VERSION ""

NS_ :

BS_:

BU_: VCM SCIM IC CCM

BO_ 156 VCM_04P_C05: 8 VCM
 SG_ LiftAxle2LowerACK : 32|3@1+ (1,0) [0|0] ""  IC
 SG_ LiftAxle2PositionStatus : 20|3@1+ (1,0) [0|0] ""  IC
 SG_ LiftAxle2LiftFuncSelected : 53|3@1+ (1,0) [0|0] ""  IC
 SG_ PassengerDoorAjar_stat : 35|3@1+ (1,0) [0|0] ""  CCM
 SG_ AirFlowSelectionDownBtn_stat : 2|2@1+ (1,0) [0|0] ""  IC
 SG_ LevelControlInformation : 56|4@1+ (1,0) [0|0] ""  IC
 SG_ LiftAxle1LowerACK : 38|3@1+ (1,0) [0|0] ""  IC
 SG_ WiperModeStatus : 41|3@1+ (1,0) [0|0] ""  IC,CCM
 SG_ Washing_HMI_rqst : 60|2@1+ (1,0) [0|0] ""  CCM
 SG_ LiftAxle2AutoLiftSelected : 8|2@1+ (1,0) [0|0] ""  IC
 SG_ ReverseGearEngaged : 10|2@1+ (1,0) [0|0] ""  CCM
 SG_ LiftAxle1PositionStatus : 17|3@1+ (1,0) [0|0] ""  IC
 SG_ ACC_Status : 47|3@1+ (1,0) [0|0] ""  IC
 SG_ LECM_CabClim_MaxDef_GuiReq : 6|2@1+ (1,0) [0|0] ""  IC
 SG_ RegenerationSwitchStatus : 23|3@1+ (1,0) [0|0] ""  IC
 SG_ DSWindowPosition : 29|3@1+ (1,0) [0|0] ""  CCM
 SG_ WindscreenDefrost_ButtonStatus : 4|2@1+ (1,0) [0|0] ""  IC
 SG_ GearSplit_Status : 0|2@1+ (1,0) [0|0] ""  IC
 SG_ KeyPosition : 44|3@1+ (1,0) [0|0] ""  IC
 SG_ LiftAxle1LiftFuncSelected : 50|3@1+ (1,0) [0|0] ""  IC
 SG_ LiftAxle2UpRequestACK : 26|3@1+ (1,0) [0|0] ""  IC
 SG_ PreTrip_ButtonStat3 : 12|2@1+ (1,0) [0|0] ""  IC
 SG_ LiftAxle1UpRequestACK : 14|3@1+ (1,0) [0|0] ""  IC

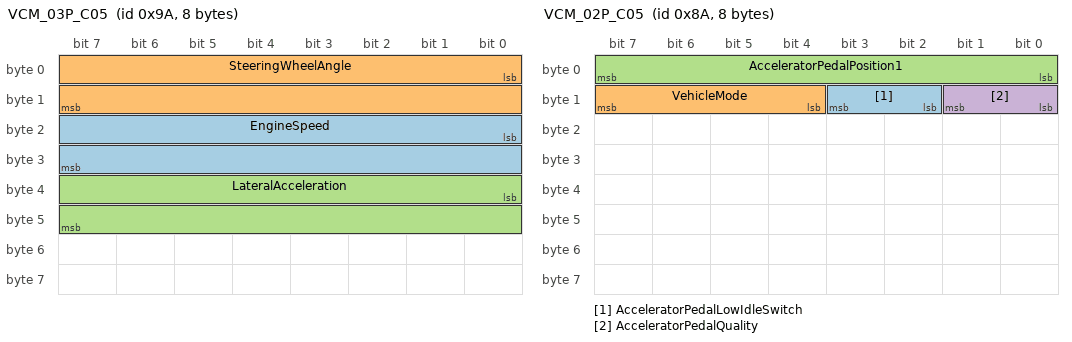
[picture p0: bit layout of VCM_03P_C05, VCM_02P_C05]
BO_ 154 VCM_03P_C05: 8 VCM
 SG_ EngineSpeed : 16|16@1+ (0.125,0) [0|8191.875] "rpm"  CCM
 SG_ SteeringWheelAngle : 0|16@1+ (0.0009765625,-31.374) [-31.374|32.6250234375] "rad"  IC
 SG_ LateralAcceleration : 32|16@1+ (0.00048828125,-15.687) [-15.687|16.31251171875] "m_per_s_squared"  IC

BO_ 138 VCM_02P_C05: 8 VCM
 SG_ AcceleratorPedalLowIdleSwitch : 10|2@1+ (1,0) [0|0] ""  IC
 SG_ VehicleMode : 12|4@1+ (1,0) [0|0] ""  SCIM,IC,CCM
 SG_ AcceleratorPedalPosition1 : 0|8@1+ (0.4,0) [0|102] "Percent"  IC
 SG_ AcceleratorPedalQuality : 8|2@1+ (1,0) [0|0] ""  IC

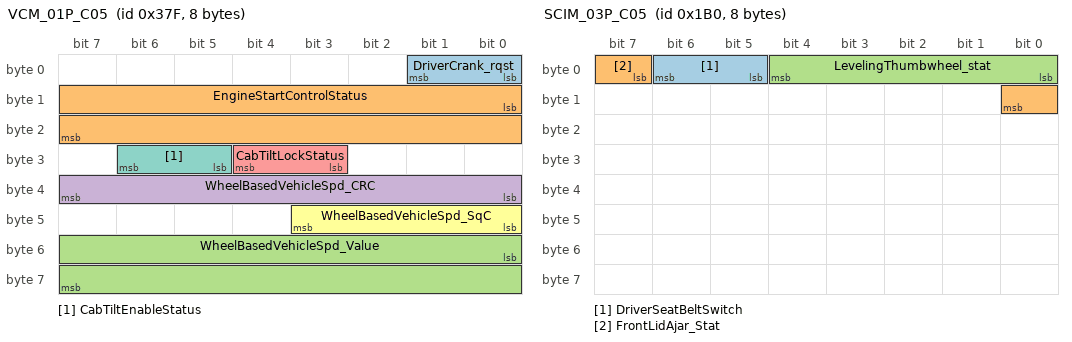
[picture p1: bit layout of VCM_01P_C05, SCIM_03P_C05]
BO_ 895 VCM_01P_C05: 8 VCM
 SG_ DriverCrank_rqst : 0|2@1+ (1,0) [0|0] ""  IC
 SG_ EngineStartControlStatus : 8|16@1+ (1,0) [0|65535] "NotApplicable"  IC
 SG_ WheelBasedVehicleSpd_Value : 48|16@1+ (0.00390625,0) [0|255.99609375] "Km_per_h"  IC
 SG_ WheelBasedVehicleSpd_CRC : 32|8@1+ (1,0) [0|255] ""  IC
 SG_ CabTiltLockStatus : 27|2@1+ (1,0) [0|0] ""  IC
 SG_ WheelBasedVehicleSpd_SqC : 40|4@1+ (1,0) [0|14] "NotApplicable"  IC
 SG_ CabTiltEnableStatus : 29|2@1+ (1,0) [0|0] ""  SCIM

BO_ 2671902706 TesterFuncDiagMsg_C05: 8 VCM
 SG_ FuncDiagDataTester : 0|64@1+ (1,0) [0|0] ""  CCM,IC,SCIM

BO_ 2671902708 TesterFuncDiagMsgF4_C05: 8 VCM
 SG_ FuncDiagDataIntTesterF4 : 0|64@1+ (1,0) [0|0] ""  CCM,IC,SCIM

BO_ 1104 SCIM_P01_C05: 8 SCIM
 SG_ CabTilt_rqst : 0|2@1+ (1,0) [0|0] ""  VCM

BO_ 432 SCIM_03P_C05: 8 SCIM
 SG_ DriverSeatBeltSwitch : 5|2@1+ (1,0) [0|0] ""  VCM,IC
 SG_ FrontLidAjar_Stat : 7|2@1+ (1,0) [0|0] ""  VCM
 SG_ LevelingThumbwheel_stat : 0|5@1+ (1,0) [0|0] ""  VCM

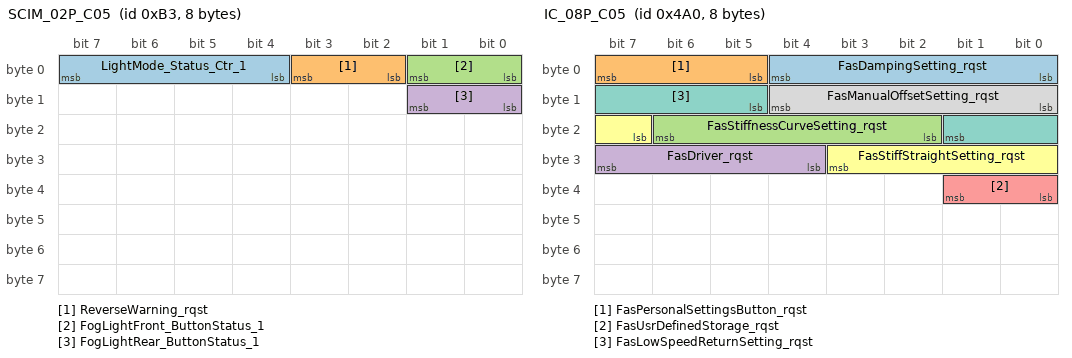
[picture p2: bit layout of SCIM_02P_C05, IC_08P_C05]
BO_ 179 SCIM_02P_C05: 8 SCIM
 SG_ LightMode_Status_Ctr_1 : 4|4@1+ (1,0) [0|0] ""  VCM
 SG_ ReverseWarning_rqst : 2|2@1+ (1,0) [0|0] ""  VCM
 SG_ FogLightFront_ButtonStatus_1 : 0|2@1+ (1,0) [0|0] ""  VCM
 SG_ FogLightRear_ButtonStatus_1 : 8|2@1+ (1,0) [0|0] ""  VCM

BO_ 2671833752 PhysDiagRespMsg_F2_98_C05: 8 CCM
 SG_ PhysDiagRespSig_F2_98 : 0|64@1+ (1,0) [0|0] ""  VCM

BO_ 2671833730 PhysDiagRespMsg_F2_82_C05: 8 IC
 SG_ PhysDiagRespSig_F2_82 : 0|64@1+ (1,0) [0|0] ""  VCM

BO_ 2671833697 PhysDiagRespMsg_F2_61_C05: 8 IC
 SG_ PhysDiagRespSig_F2_61 : 0|64@1+ (1,0) [0|0] ""  VCM

BO_ 2671833664 PhysDiagRespMsg_F2_40_C05: 8 SCIM
 SG_ PhysDiagRespSig_F2_40 : 0|64@1+ (1,0) [0|0] ""  VCM

BO_ 2671810802 PhysDiagReqMsg_98_F2_C05: 8 VCM
 SG_ PhysDiagReqSig_98_F2 : 0|64@1+ (1,0) [0|0] ""  CCM

BO_ 2671805170 PhysDiagReqMsg_82_F2_C05: 8 VCM
 SG_ PhysDiagReqSig_82_F2 : 0|64@1+ (1,0) [0|0] ""  IC

BO_ 2671796722 PhysDiagReqMsg_61_F2_C05: 8 VCM
 SG_ PhysDiagReqSig_61_F2 : 0|64@1+ (1,0) [0|0] ""  IC

BO_ 2671788274 PhysDiagReqMsg_40_F2_C05: 8 VCM
 SG_ PhysDiagReqSig_40_F2 : 0|64@1+ (1,0) [0|0] ""  SCIM

BO_ 2633990180 NmAsr_VCM_C05: 1 VCM

BO_ 2633990208 NmAsr_SCIM_C05: 1 SCIM

BO_ 2633990241 NmAsr_IC_C05: 1 IC

BO_ 2633990296 NmAsr_CCM_C05: 1 CCM

BO_ 1457 IC_09S_C05_FCM: 8 VCM
 SG_ IC_09S_C05_FCS : 0|64@1+ (1,0) [0|0] ""  IC

BO_ 1456 IC_09S_C05: 11 IC
 SG_ ECU3VIN_stat : 0|88@1+ (1,0) [0|0] ""  VCM

BO_ 1184 IC_08P_C05: 8 IC
 SG_ FasDampingSetting_rqst : 0|5@1+ (1,-10) [-10|21] ""  VCM
 SG_ FasPersonalSettingsButton_rqst : 5|3@1+ (1,0) [0|0] ""  VCM
 SG_ FasStiffnessCurveSetting_rqst : 18|5@1+ (1,-10) [-10|21] ""  VCM
 SG_ FasDriver_rqst : 28|4@1+ (1,0) [0|0] ""  VCM
 SG_ FasUsrDefinedStorage_rqst : 32|2@1+ (1,0) [0|0] ""  VCM
 SG_ FasStiffStraightSetting_rqst : 23|5@1+ (1,-10) [-10|21] ""  VCM
 SG_ FasLowSpeedReturnSetting_rqst : 13|5@1+ (1,-10) [-10|21] ""  VCM
 SG_ FasManualOffsetSetting_rqst : 8|5@1+ (1,-10) [-10|21] ""  VCM

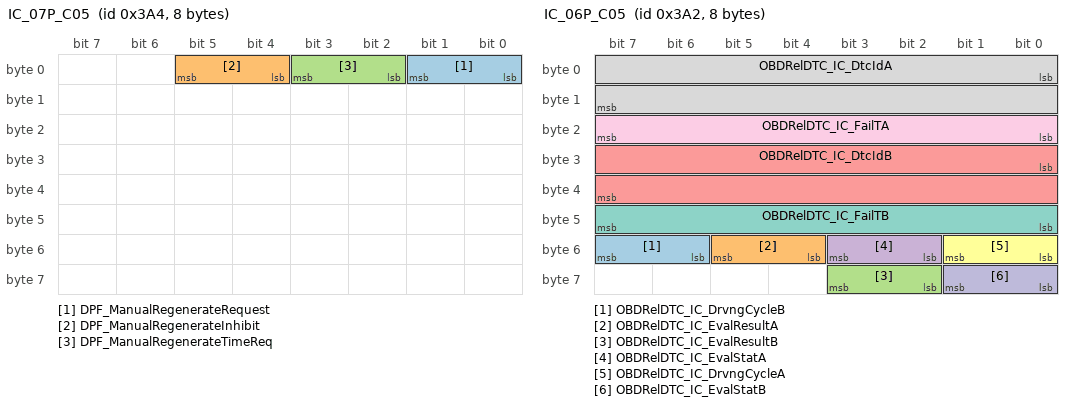
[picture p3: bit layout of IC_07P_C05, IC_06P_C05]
BO_ 932 IC_07P_C05: 8 IC
 SG_ DPF_ManualRegenerateRequest : 0|2@1+ (1,0) [0|0] ""  VCM
 SG_ DPF_ManualRegenerateInhibit : 4|2@1+ (1,0) [0|0] ""  VCM
 SG_ DPF_ManualRegenerateTimeReq : 2|2@1+ (1,0) [0|0] ""  VCM

BO_ 930 IC_06P_C05: 8 IC
 SG_ OBDRelDTC_IC_DrvngCycleB : 54|2@1+ (1,0) [0|0] ""  VCM
 SG_ OBDRelDTC_IC_EvalResultA : 52|2@1+ (1,0) [0|0] ""  VCM
 SG_ OBDRelDTC_IC_EvalResultB : 58|2@1+ (1,0) [0|0] ""  VCM
 SG_ OBDRelDTC_IC_EvalStatA : 50|2@1+ (1,0) [0|0] ""  VCM
 SG_ OBDRelDTC_IC_DtcIdB : 24|16@1+ (1,0) [0|65535] ""  VCM
 SG_ OBDRelDTC_IC_DrvngCycleA : 48|2@1+ (1,0) [0|0] ""  VCM
 SG_ OBDRelDTC_IC_FailTB : 40|8@1+ (1,0) [0|255] ""  VCM
 SG_ OBDRelDTC_IC_DtcIdA : 0|16@1+ (1,0) [0|65535] ""  VCM
 SG_ OBDRelDTC_IC_FailTA : 16|8@1+ (1,0) [0|255] ""  VCM
 SG_ OBDRelDTC_IC_EvalStatB : 56|2@1+ (1,0) [0|0] ""  VCM

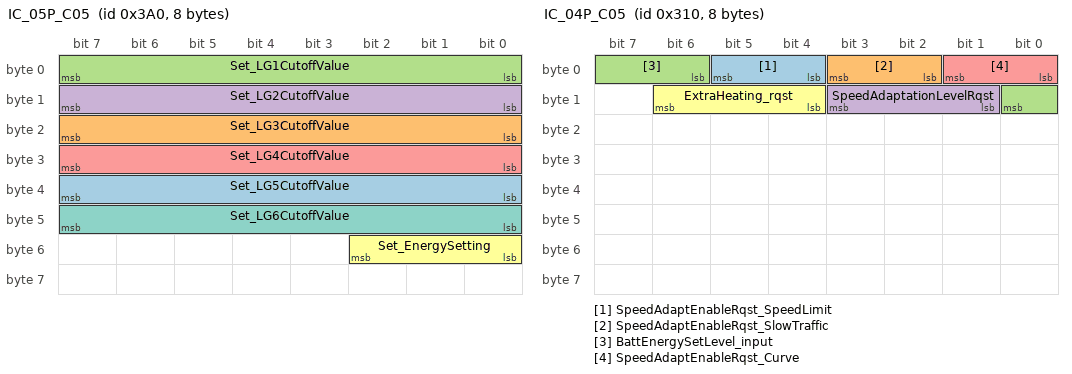
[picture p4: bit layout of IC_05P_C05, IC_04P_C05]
BO_ 928 IC_05P_C05: 8 IC
 SG_ Set_LG5CutoffValue : 32|8@1+ (1,0) [0|255] "Percent"  VCM
 SG_ Set_LG3CutoffValue : 16|8@1+ (1,0) [0|255] "Percent"  VCM
 SG_ Set_LG1CutoffValue : 0|8@1+ (1,0) [0|255] "Percent"  VCM
 SG_ Set_LG2CutoffValue : 8|8@1+ (1,0) [0|255] "Percent"  VCM
 SG_ Set_LG4CutoffValue : 24|8@1+ (1,0) [0|255] "Percent"  VCM
 SG_ Set_EnergySetting : 48|3@1+ (1,0) [0|0] ""  VCM
 SG_ Set_LG6CutoffValue : 40|8@1+ (1,0) [0|255] "Percent"  VCM

BO_ 784 IC_04P_C05: 8 IC
 SG_ SpeedAdaptEnableRqst_SpeedLimit : 4|2@1+ (1,0) [0|0] ""  VCM
 SG_ SpeedAdaptEnableRqst_SlowTraffic : 2|2@1+ (1,0) [0|0] ""  VCM
 SG_ BattEnergySetLevel_input : 6|3@1+ (1,0) [0|0] ""  VCM
 SG_ SpeedAdaptationLevelRqst : 9|3@1+ (1,0) [0|0] ""  VCM
 SG_ SpeedAdaptEnableRqst_Curve : 0|2@1+ (1,0) [0|0] ""  VCM
 SG_ ExtraHeating_rqst : 12|3@1+ (1,0) [0|0] ""  CCM,VCM

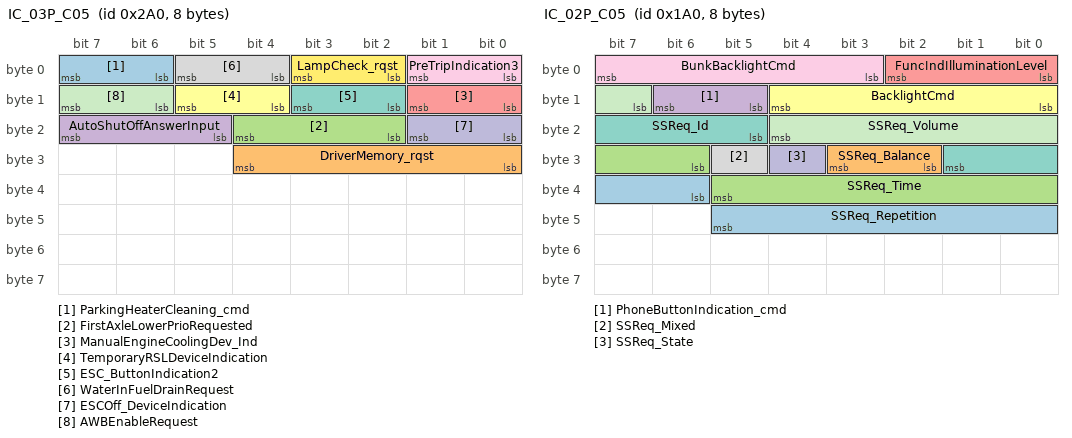
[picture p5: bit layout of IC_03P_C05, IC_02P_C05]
BO_ 672 IC_03P_C05: 8 IC
 SG_ ParkingHeaterCleaning_cmd : 6|2@1+ (1,0) [0|0] ""  VCM,CCM
 SG_ DriverMemory_rqst : 24|5@1+ (1,0) [0|0] ""  CCM,VCM
 SG_ FirstAxleLowerPrioRequested : 18|3@1+ (1,0) [0|0] ""  VCM
 SG_ AutoShutOffAnswerInput : 21|3@1+ (1,0) [0|0] ""  VCM
 SG_ ManualEngineCoolingDev_Ind : 8|2@1+ (1,0) [0|0] ""  VCM
 SG_ TemporaryRSLDeviceIndication : 12|2@1+ (1,0) [0|0] ""  VCM
 SG_ ESC_ButtonIndication2 : 10|2@1+ (1,0) [0|0] ""  VCM
 SG_ WaterInFuelDrainRequest : 4|2@1+ (1,0) [0|0] ""  VCM
 SG_ PreTripIndication3 : 0|2@1+ (1,0) [0|0] ""  VCM
 SG_ ESCOff_DeviceIndication : 16|2@1+ (1,0) [0|0] ""  VCM
 SG_ AWBEnableRequest : 14|2@1+ (1,0) [0|0] ""  VCM
 SG_ LampCheck_rqst : 2|2@1+ (1,0) [0|0] ""  VCM

BO_ 416 IC_02P_C05: 8 IC
 SG_ SSReq_Repetition : 38|8@1+ (1,0) [0|255] ""  VCM
 SG_ SSReq_Balance : 26|2@1+ (1,0) [0|0] ""  VCM
 SG_ SSReq_Time : 30|8@1+ (0.1,0) [0|25.5] "s"  VCM
 SG_ PhoneButtonIndication_cmd : 13|2@1+ (1,0) [0|0] ""  VCM
 SG_ FuncIndIlluminationLevel : 0|3@1+ (1,0) [0|0] ""  VCM
 SG_ BacklightCmd : 8|5@1+ (1,0) [0|0] ""  VCM
 SG_ SSReq_Id : 21|5@1+ (1,0) [0|31] ""  VCM
 SG_ SSReq_Mixed : 29|1@1+ (1,0) [0|0] ""  VCM
 SG_ BunkBacklightCmd : 3|5@1+ (1,0) [0|0] ""  VCM
 SG_ SSReq_State : 28|1@1+ (1,0) [0|0] ""  VCM
 SG_ SSReq_Volume : 15|6@1+ (1,0) [0|63] ""  VCM

BO_ 211 IC_01P_C05: 8 IC
 SG_ TimeGapBtnStat : 30|2@1+ (1,0) [0|0] ""  VCM
 SG_ ATC_ButtonIndication : 10|2@1+ (1,0) [0|0] ""  VCM
 SG_ PauseOffBtnStat : 0|2@1+ (1,0) [0|0] ""  VCM
 SG_ ABS_ButtonIndication : 18|2@1+ (1,0) [0|0] ""  VCM
 SG_ SW_HeadlightInterrupt_Stat : 32|2@1+ (1,0) [0|0] ""  VCM
 SG_ PBAlertActiveStatus : 34|3@1+ (1,0) [0|0] ""  VCM
 SG_ EcoRollEnableRequest : 24|2@1+ (1,0) [0|0] ""  VCM
 SG_ EcoSettingsBtnStat : 22|2@1+ (1,0) [0|0] ""  VCM
 SG_ SkipNextBtnStat : 12|2@1+ (1,0) [0|0] ""  VCM
 SG_ TCS_ButtonIndication : 6|2@1+ (1,0) [0|0] ""  VCM
 SG_ DHCBtnStat : 16|2@1+ (1,0) [0|0] ""  VCM
 SG_ PhoneBtnStat : 8|2@1+ (1,0) [0|0] ""  VCM
 SG_ SkipPrevBtnStat : 4|2@1+ (1,0) [0|0] ""  VCM
 SG_ ActivateBtnStat : 26|2@1+ (1,0) [0|0] ""  VCM
 SG_ ResIncrBtnStat : 2|2@1+ (1,0) [0|0] ""  VCM
 SG_ SrcBtnStat : 14|2@1+ (1,0) [0|0] ""  VCM
 SG_ SetDecrBtnStat : 28|2@1+ (1,0) [0|0] ""  VCM
 SG_ MarkerInterruptButtonStatus : 20|2@1+ (1,0) [0|0] ""  VCM

BO_ 1123 DummyFrame_VCM_C_C05: 8 VCM
 SG_ DummyApplicationSignal : 0|8@1+ (1,0) [0|255] ""  SCIM,IC,CCM

BO_ 2671964824 DiagUUDTRespMsg1_F2_98_C05: 8 CCM
 SG_ DiagUUDTRespSig_F2_98 : 0|64@1+ (1,0) [0|0] ""  VCM

BO_ 2671964802 DiagUUDTRespMsg1_F2_82_C05: 8 IC
 SG_ DiagUUDTRespSig_F2_82 : 0|64@1+ (1,0) [0|0] ""  VCM

BO_ 2671964769 DiagUUDTRespMsg1_F2_61_C05: 8 IC
 SG_ DiagUUDTRespSig_F2_61 : 0|64@1+ (1,0) [0|0] ""  VCM

BO_ 2671964736 DiagUUDTRespMsg1_F2_40_C05: 8 SCIM
 SG_ DiagUUDTRespSig_F2_40 : 0|64@1+ (1,0) [0|0] ""  VCM

BO_ 2671834264 DiagRespMsgForIntTest_F4_98_C05: 8 CCM
 SG_ InternalTesterDiagSig_F4_98 : 0|64@1+ (1,0) [0|0] ""  VCM

BO_ 2671834242 DiagRespMsgForIntTest_F4_82_C05: 8 IC
 SG_ InternalTesterDiagSig_F4_82 : 0|64@1+ (1,0) [0|0] ""  VCM

BO_ 2671834209 DiagRespMsgForIntTest_F4_61_C05: 8 IC
 SG_ InternalTesterDiagSig_F4_61 : 0|64@1+ (1,0) [0|0] ""  VCM

BO_ 2671834176 DiagRespMsgForIntTest_F4_40_C05: 8 SCIM
 SG_ InternalTesterDiagSig_F4_40 : 0|64@1+ (1,0) [0|0] ""  VCM

BO_ 2671810804 DiagReqMsgOfIntTest_98_F4_C05: 8 VCM
 SG_ InternalTesterDiagSig_98_F4 : 0|64@1+ (1,0) [0|0] ""  CCM

BO_ 2671805172 DiagReqMsgOfIntTest_82_F4_C05: 8 VCM
 SG_ InternalTesterDiagSig_82_F4 : 0|64@1+ (1,0) [0|0] ""  IC

BO_ 2671796724 DiagReqMsgOfIntTest_61_F4_C05: 8 VCM
 SG_ InternalTesterDiagSig_61_F4 : 0|64@1+ (1,0) [0|0] ""  IC

BO_ 2671788276 DiagReqMsgOfIntTest_40_F4_C05: 8 VCM
 SG_ InternalTesterDiagSig_40_F4 : 0|64@1+ (1,0) [0|0] ""  SCIM

BO_ 1121 CCM_07P_C05_FCM: 8 VCM
 SG_ CCM_07P_C05_FCS : 0|64@1+ (1,0) [0|0] ""  CCM

BO_ 1120 CCM_07P_C05: 10 CCM
 SG_ EngineTimer_stat_Timer2Minutes : 64|8@1+ (1,0) [0|255] "min"  VCM
 SG_ EngineTimer_stat_Timer1Recurr : 0|4@1+ (1,0) [0|0] ""  VCM
 SG_ EngineTimer_stat_Timer3Minutes : 56|8@1+ (1,0) [0|255] "min"  VCM
 SG_ EngineTimer_stat_Timer2StartDay : 16|4@1+ (1,0) [0|0] ""  VCM
 SG_ EngineTimer_stat_Timer3Recurr : 8|4@1+ (1,0) [0|0] ""  VCM
 SG_ EngineTimer_stat_Timer1Hours : 40|8@1+ (1,0) [0|255] "h"  VCM
 SG_ EngineTimer_stat_Timer3_Status : 76|2@1+ (1,0) [0|0] ""  VCM
 SG_ EngineTimer_stat_Timer1_Status : 72|2@1+ (1,0) [0|0] ""  VCM
 SG_ EngineTimer_stat_Timer1Minutes : 24|8@1+ (1,0) [0|255] "min"  VCM
 SG_ EngineTimer_stat_Timer2Recurr : 4|4@1+ (1,0) [0|0] ""  VCM
 SG_ EngineTimer_stat_Timer3Hours : 32|8@1+ (1,0) [0|255] "h"  VCM
 SG_ EngineTimer_stat_Timer2_Status : 74|2@1+ (1,0) [0|0] ""  VCM
 SG_ EngineTimer_stat_Timer2Hours : 48|8@1+ (1,0) [0|255] "h"  VCM
 SG_ EngineTimer_stat_Timer1StartDay : 12|4@1+ (1,0) [0|0] ""  VCM
 SG_ EngineTimer_stat_Timer3StartDay : 20|4@1+ (1,0) [0|0] ""  VCM

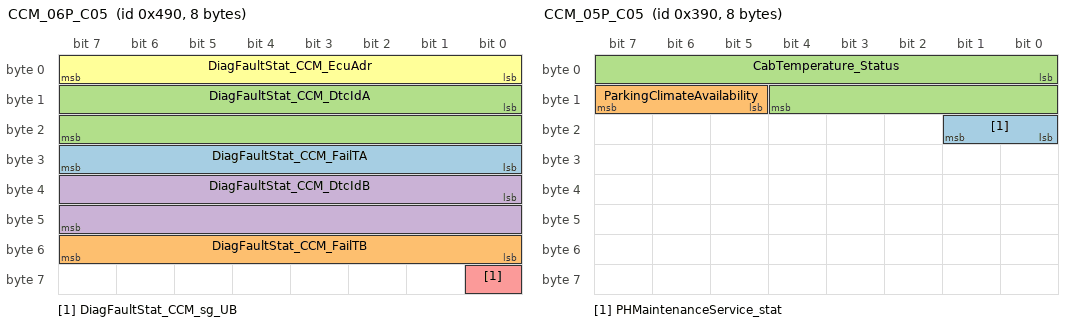
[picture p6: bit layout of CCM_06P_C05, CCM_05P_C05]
BO_ 1168 CCM_06P_C05: 8 CCM
 SG_ DiagFaultStat_CCM_FailTA : 24|8@1+ (1,0) [0|255] ""  VCM
 SG_ DiagFaultStat_CCM_FailTB : 48|8@1+ (1,0) [0|255] ""  VCM
 SG_ DiagFaultStat_CCM_DtcIdA : 8|16@1+ (1,0) [0|65535] ""  VCM
 SG_ DiagFaultStat_CCM_DtcIdB : 32|16@1+ (1,0) [0|65535] ""  VCM
 SG_ DiagFaultStat_CCM_sg_UB : 56|1@1+ (1,0) [0|0] ""  VCM
 SG_ DiagFaultStat_CCM_EcuAdr : 0|8@1+ (1,0) [0|255] ""  VCM

BO_ 912 CCM_05P_C05: 8 CCM
 SG_ PHMaintenanceService_stat : 16|2@1+ (1,0) [0|0] ""  VCM
 SG_ ParkingClimateAvailability : 13|3@1+ (1,0) [0|0] ""  VCM
 SG_ CabTemperature_Status : 0|13@1+ (0.025,-40) [-40|164.775] "DegreeC"  VCM

BO_ 656 CCM_04P_C05: 8 CCM
 SG_ AcCoolantPumpEngagementRequest : 0|8@1+ (0.4,0) [0|102] "Percent"  VCM

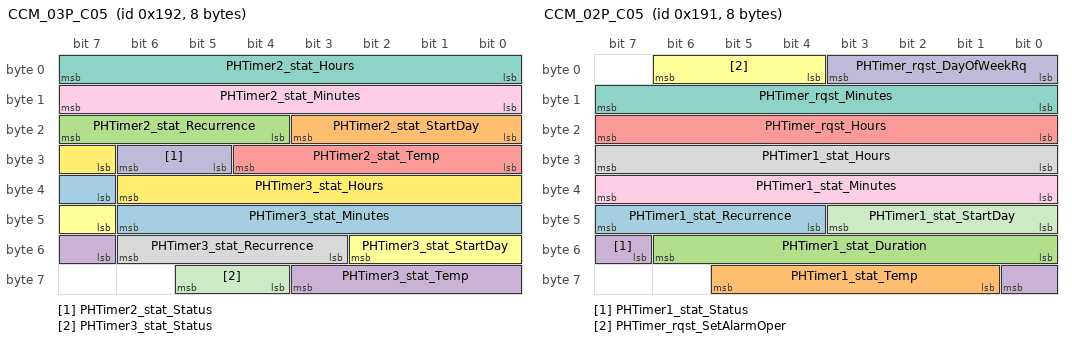
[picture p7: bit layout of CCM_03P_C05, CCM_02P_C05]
BO_ 402 CCM_03P_C05: 8 CCM
 SG_ PHTimer3_stat_Minutes : 39|8@1+ (1,0) [0|255] "min"  VCM
 SG_ PHTimer2_stat_StartDay : 16|4@1+ (1,0) [0|0] ""  VCM
 SG_ PHTimer2_stat_Recurrence : 20|4@1+ (1,0) [0|0] ""  VCM
 SG_ PHTimer3_stat_Temp : 55|5@1+ (1,0) [0|0] ""  VCM
 SG_ PHTimer2_stat_Temp : 24|5@1+ (1,0) [0|0] ""  VCM
 SG_ PHTimer3_stat_StartDay : 47|4@1+ (1,0) [0|0] ""  VCM
 SG_ PHTimer2_stat_Hours : 0|8@1+ (1,0) [0|255] "h"  VCM
 SG_ PHTimer3_stat_Recurrence : 51|4@1+ (1,0) [0|0] ""  VCM
 SG_ PHTimer2_stat_Minutes : 8|8@1+ (1,0) [0|255] "min"  VCM
 SG_ PHTimer2_stat_Status : 29|2@1+ (1,0) [0|0] ""  VCM
 SG_ PHTimer3_stat_Status : 60|2@1+ (1,0) [0|0] ""  VCM
 SG_ PHTimer3_stat_Hours : 31|8@1+ (1,0) [0|255] "h"  VCM

BO_ 401 CCM_02P_C05: 8 CCM
 SG_ PHTimer1_stat_Recurrence : 44|4@1+ (1,0) [0|0] ""  VCM
 SG_ PHTimer1_stat_Temp : 57|5@1+ (1,0) [0|0] ""  VCM
 SG_ PHTimer1_stat_Duration : 48|7@1+ (1,0) [0|127] "min"  VCM
 SG_ PHTimer1_stat_Status : 55|2@1+ (1,0) [0|0] ""  VCM
 SG_ PHTimer_rqst_Hours : 16|8@1+ (1,0) [0|255] "h"  VCM
 SG_ PHTimer_rqst_SetAlarmOper : 4|3@1+ (1,0) [0|0] ""  VCM
 SG_ PHTimer_rqst_Minutes : 8|8@1+ (1,0) [0|255] "min"  VCM
 SG_ PHTimer1_stat_Hours : 24|8@1+ (1,0) [0|255] "h"  VCM
 SG_ PHTimer1_stat_Minutes : 32|8@1+ (1,0) [0|255] "min"  VCM
 SG_ PHTimer_rqst_DayOfWeekRq : 0|4@1+ (1,0) [0|0] ""  VCM
 SG_ PHTimer1_stat_StartDay : 40|4@1+ (1,0) [0|0] ""  VCM

BO_ 400 CCM_01P_C05: 8 CCM
 SG_ WindscreenDefrostInd_cmd : 1|1@1+ (1,0) [0|0] ""  VCM
 SG_ ParkingHeater_IndicationCmd : 0|1@1+ (1,0) [0|0] ""  VCM
 SG_ AutoBlowerLevelIndication_Cmd : 18|3@1+ (1,0) [0|0] ""  VCM
 SG_ AC_CompressorClutchCmd : 4|2@1+ (1,0) [0|0] ""  VCM
 SG_ ACdisplayIndication_Cmd : 15|3@1+ (1,0) [0|0] ""  VCM
 SG_ ParkingHeaterCleaning_Rqst : 8|2@1+ (1,0) [0|0] ""  IC,VCM
 SG_ TemperatureRqstIndication_cmd : 29|5@1+ (1,0) [0|0] ""  IC,VCM
 SG_ ParkingClimate_IndicationCmd : 21|3@1+ (1,0) [0|0] ""  VCM,IC
 SG_ ACmode_IndicationCmd : 44|1@1+ (1,0) [0|0] ""  VCM
 SG_ AutoDefogIndication_Cmd : 12|3@1+ (1,0) [0|0] ""  VCM
 SG_ TempRqst_cmd : 24|5@1+ (1,0) [0|0] ""  VCM
 SG_ ExtraHeating_status : 10|2@1+ (1,0) [0|0] ""  IC,VCM
 SG_ AQSmodeIndication_Cmd : 2|2@1+ (1,0) [0|0] ""  VCM
 SG_ CabInteriorTempVentilated_Stat : 34|10@1+ (0.125,-40) [-40|87.875] "DegreeC"  VCM
 SG_ AutoMode_IndicationCmd : 45|1@1+ (1,0) [0|0] ""  VCM
 SG_ ShortStopHeater_cmd : 6|2@1+ (1,0) [0|0] ""  VCM
 SG_ ACCoolingFanSpeedRequest_CCM : 48|16@1+ (1,0) [0|65535] "rpm"  VCM

BO_ 1717 AnmMsg_VCM_C05: 8 VCM
 SG_ AnmSig_VCM_CAN05 : 0|32@1+ (1,0) [0|0] ""  IC,CCM,SCIM

BO_ 1718 AnmMsg_SCIM_C05: 8 SCIM
 SG_ AnmSig_SCIM_CAN05 : 0|32@1+ (1,0) [0|0] ""  CCM,VCM,IC

BO_ 1716 AnmMsg_IC_C05: 8 IC
 SG_ AnmSig_IC_CAN05 : 0|32@1+ (1,0) [0|0] ""  SCIM,CCM,VCM

BO_ 1719 AnmMsg_CCM_C05: 8 CCM
 SG_ AnmSig_CCM_CAN05 : 0|32@1+ (1,0) [0|0] ""  VCM,SCIM,IC

CM_ SG_ 1120 EngineTimer_stat_Timer2Minutes "254 Error ; 255 Not available";
CM_ SG_ 1120 EngineTimer_stat_Timer3Minutes "254 Error ; 255 Not available";
CM_ SG_ 1120 EngineTimer_stat_Timer1Hours "254 Error ; 255 Not available";
CM_ SG_ 1120 EngineTimer_stat_Timer1Minutes "254 Error ; 255 Not available";
CM_ SG_ 1120 EngineTimer_stat_Timer3Hours "254 Error ; 255 Not available";
CM_ SG_ 1120 EngineTimer_stat_Timer2Hours "254 Error ; 255 Not available";
CM_ SG_ 401 PHTimer_rqst_Hours "254 Error ; 255 Not available";
CM_ SG_ 401 PHTimer_rqst_Minutes "254 Error ; 255 Not available";
BA_DEF_ BO_  "GenMsgStartDelayTime" INT 0 0;
BA_DEF_ BO_  "GenMsgDelayTime" INT 0 0;
BA_DEF_ BO_  "GenMsgCycleTime" INT 0 0;
BA_DEF_ BO_  "GenMsgSendType" ENUM  "Cyclic","NotUsed","NotUsed","NotUsed","NotUsed","NotUsed","NotUsed","IfActive","NoMsgSendType","NotUsed";
BA_DEF_ SG_  "GenSigStartValue" INT 0 0;
BA_DEF_ SG_  "GenSigCycleTimeActive" INT 0 0;
BA_DEF_ SG_  "GenSigCycleTime" INT 0 0;
BA_DEF_ SG_  "GenSigSendType" ENUM  "Cyclic","OnWrite","OnWriteWithRepetition","OnChange","OnChangeWithRepetition","IfActive","IfActiveWithRepetition","NoSigSendType","NotUsed","NotUsed","NotUsed","NotUsed","NotUsed";
BA_DEF_ BO_  "VFrameFormat" ENUM  "StandardCAN","ExtendedCAN","reserved","J1939PG","reserved","reserved","reserved","reserved","reserved","reserved","reserved","reserved","reserved","reserved","StandardCAN_FD","ExtendedCAN_FD";
BA_DEF_ SG_  "SigType" ENUM  "Default","Range","RangeSigned","ASCII","Discrete","Control","ReferencePGN","DTC","StringDelimiter","StringLength","StringLengthControl";
BA_DEF_ BO_  "NmAsrMessage" ENUM  "No","Yes";
BA_DEF_ SG_  "NeedsUpdateBit" ENUM  "No","Yes";
BA_DEF_ SG_  "MmAnSignal" ENUM  "No","Yes";
BA_DEF_ SG_  "GenSigMaxLatency" INT 0 65535;
BA_DEF_ SG_  "GenSigILSupport" ENUM  "Yes","No";
BA_DEF_ BO_  "GenMsgILSupport" ENUM  "No","Yes";
BA_DEF_ SG_  "E2EProfile" STRING ;
BA_DEF_ SG_  "E2EDataLength" INT 0 65535;
BA_DEF_ SG_  "E2EDataId" INT 0 65535;
BA_DEF_ BO_  "DiagUUDTResponse" ENUM  "No","Yes";
BA_DEF_ BO_  "DiagState" ENUM  "No","Yes";
BA_DEF_ BO_  "DiagResponse" ENUM  "No","Yes";
BA_DEF_ BO_  "DiagRequest" ENUM  "No","Yes";
BA_DEF_ BO_  "DiagConnection" HEX 0 65535;
BA_DEF_ BO_  "CanTpFcFrameId" HEX 0 2147483647;
BA_DEF_ BO_  "CanTpBs" INT 0 255;
BA_DEF_REL_ BU_SG_REL_  "GenSigTimeoutTime" INT 0 65535;
BA_DEF_REL_ BU_SG_REL_  "GenSigFirstTimeoutTime" INT 0 65535;
BA_DEF_DEF_  "GenMsgStartDelayTime" 0;
BA_DEF_DEF_  "GenMsgDelayTime" 0;
BA_DEF_DEF_  "GenMsgCycleTime" 0;
BA_DEF_DEF_  "GenMsgSendType" "Cyclic";
BA_DEF_DEF_  "GenSigStartValue" 0;
BA_DEF_DEF_  "GenSigCycleTimeActive" 0;
BA_DEF_DEF_  "GenSigCycleTime" 0;
BA_DEF_DEF_  "GenSigSendType" "Cyclic";
BA_DEF_DEF_  "VFrameFormat" "ExtendedCAN";
BA_DEF_DEF_  "SigType" "Default";
BA_DEF_DEF_  "NmAsrMessage" "No";
BA_DEF_DEF_  "NeedsUpdateBit" "No";
BA_DEF_DEF_  "MmAnSignal" "No";
BA_DEF_DEF_  "GenSigMaxLatency" 0;
BA_DEF_DEF_  "GenSigILSupport" "Yes";
BA_DEF_DEF_  "GenMsgILSupport" "Yes";
BA_DEF_DEF_  "E2EProfile" "none";
BA_DEF_DEF_  "E2EDataLength" 0;
BA_DEF_DEF_  "E2EDataId" 0;
BA_DEF_DEF_  "DiagUUDTResponse" "No";
BA_DEF_DEF_  "DiagState" "No";
BA_DEF_DEF_  "DiagResponse" "No";
BA_DEF_DEF_  "DiagRequest" "No";
BA_DEF_DEF_  "DiagConnection" 0;
BA_DEF_DEF_  "CanTpFcFrameId" 2147483647;
BA_DEF_DEF_  "CanTpBs" 255;
BA_DEF_DEF_REL_ "GenSigTimeoutTime" 0;
BA_DEF_DEF_REL_ "GenSigFirstTimeoutTime" 0;
BA_ "VFrameFormat" BO_ 156 0;
BA_ "GenMsgCycleTime" BO_ 156 20;
BA_ "VFrameFormat" BO_ 154 0;
BA_ "GenMsgCycleTime" BO_ 154 20;
BA_ "VFrameFormat" BO_ 138 0;
BA_ "GenMsgCycleTime" BO_ 138 10;
BA_ "VFrameFormat" BO_ 895 0;
BA_ "GenMsgCycleTime" BO_ 895 50;
BA_ "GenMsgStartDelayTime" BO_ 895 5;
BA_ "DiagConnection" BO_ 2671902706 62082;
BA_ "DiagState" BO_ 2671902706 1;
BA_ "GenMsgILSupport" BO_ 2671902706 0;
BA_ "GenMsgSendType" BO_ 2671902706 8;
BA_ "DiagConnection" BO_ 2671902708 62719;
BA_ "DiagState" BO_ 2671902708 1;
BA_ "GenMsgILSupport" BO_ 2671902708 0;
BA_ "GenMsgSendType" BO_ 2671902708 8;
BA_ "VFrameFormat" BO_ 1104 0;
BA_ "GenMsgCycleTime" BO_ 1104 100;
BA_ "GenMsgStartDelayTime" BO_ 1104 10;
BA_ "VFrameFormat" BO_ 432 0;
BA_ "GenMsgCycleTime" BO_ 432 50;
BA_ "VFrameFormat" BO_ 179 0;
BA_ "GenMsgCycleTime" BO_ 179 20;
BA_ "DiagConnection" BO_ 2671833752 62104;
BA_ "DiagResponse" BO_ 2671833752 1;
BA_ "GenMsgILSupport" BO_ 2671833752 0;
BA_ "GenMsgSendType" BO_ 2671833752 8;
BA_ "DiagConnection" BO_ 2671833730 62082;
BA_ "DiagResponse" BO_ 2671833730 1;
BA_ "GenMsgILSupport" BO_ 2671833730 0;
BA_ "GenMsgSendType" BO_ 2671833730 8;
BA_ "DiagConnection" BO_ 2671833697 62049;
BA_ "DiagResponse" BO_ 2671833697 1;
BA_ "GenMsgILSupport" BO_ 2671833697 0;
BA_ "GenMsgSendType" BO_ 2671833697 8;
BA_ "DiagConnection" BO_ 2671833664 62016;
BA_ "DiagResponse" BO_ 2671833664 1;
BA_ "GenMsgILSupport" BO_ 2671833664 0;
BA_ "GenMsgSendType" BO_ 2671833664 8;
BA_ "DiagConnection" BO_ 2671810802 62104;
BA_ "DiagRequest" BO_ 2671810802 1;
BA_ "GenMsgILSupport" BO_ 2671810802 0;
BA_ "GenMsgSendType" BO_ 2671810802 8;
BA_ "DiagConnection" BO_ 2671805170 62082;
BA_ "DiagRequest" BO_ 2671805170 1;
BA_ "GenMsgILSupport" BO_ 2671805170 0;
BA_ "GenMsgSendType" BO_ 2671805170 8;
BA_ "DiagConnection" BO_ 2671796722 62049;
BA_ "DiagRequest" BO_ 2671796722 1;
BA_ "GenMsgILSupport" BO_ 2671796722 0;
BA_ "GenMsgSendType" BO_ 2671796722 8;
BA_ "DiagConnection" BO_ 2671788274 62016;
BA_ "DiagRequest" BO_ 2671788274 1;
BA_ "GenMsgILSupport" BO_ 2671788274 0;
BA_ "GenMsgSendType" BO_ 2671788274 8;
BA_ "GenMsgILSupport" BO_ 2633990180 0;
BA_ "NmAsrMessage" BO_ 2633990180 1;
BA_ "GenMsgSendType" BO_ 2633990180 8;
BA_ "GenMsgILSupport" BO_ 2633990208 0;
BA_ "NmAsrMessage" BO_ 2633990208 1;
BA_ "GenMsgSendType" BO_ 2633990208 8;
BA_ "GenMsgILSupport" BO_ 2633990241 0;
BA_ "NmAsrMessage" BO_ 2633990241 1;
BA_ "GenMsgSendType" BO_ 2633990241 8;
BA_ "GenMsgILSupport" BO_ 2633990296 0;
BA_ "NmAsrMessage" BO_ 2633990296 1;
BA_ "GenMsgSendType" BO_ 2633990296 8;
BA_ "GenMsgILSupport" BO_ 1457 0;
BA_ "VFrameFormat" BO_ 1457 0;
BA_ "GenMsgSendType" BO_ 1457 8;
BA_ "CanTpFcFrameId" BO_ 1456 1457;
BA_ "VFrameFormat" BO_ 1456 0;
BA_ "GenMsgSendType" BO_ 1456 8;
BA_ "GenMsgDelayTime" BO_ 1456 980;
BA_ "VFrameFormat" BO_ 1184 0;
BA_ "GenMsgCycleTime" BO_ 1184 1000;
BA_ "VFrameFormat" BO_ 932 0;
BA_ "GenMsgCycleTime" BO_ 932 500;
BA_ "VFrameFormat" BO_ 930 0;
BA_ "GenMsgCycleTime" BO_ 930 500;
BA_ "VFrameFormat" BO_ 928 0;
BA_ "GenMsgCycleTime" BO_ 928 500;
BA_ "VFrameFormat" BO_ 784 0;
BA_ "GenMsgCycleTime" BO_ 784 200;
BA_ "VFrameFormat" BO_ 672 0;
BA_ "GenMsgCycleTime" BO_ 672 100;
BA_ "VFrameFormat" BO_ 416 0;
BA_ "GenMsgCycleTime" BO_ 416 50;
BA_ "VFrameFormat" BO_ 211 0;
BA_ "GenMsgCycleTime" BO_ 211 20;
BA_ "VFrameFormat" BO_ 1123 0;
BA_ "GenMsgCycleTime" BO_ 1123 100;
BA_ "GenMsgStartDelayTime" BO_ 1123 50;
BA_ "DiagConnection" BO_ 2671964824 62104;
BA_ "DiagUUDTResponse" BO_ 2671964824 1;
BA_ "GenMsgILSupport" BO_ 2671964824 0;
BA_ "GenMsgSendType" BO_ 2671964824 8;
BA_ "DiagConnection" BO_ 2671964802 62082;
BA_ "DiagUUDTResponse" BO_ 2671964802 1;
BA_ "GenMsgILSupport" BO_ 2671964802 0;
BA_ "GenMsgSendType" BO_ 2671964802 8;
BA_ "DiagConnection" BO_ 2671964769 62049;
BA_ "DiagUUDTResponse" BO_ 2671964769 1;
BA_ "GenMsgILSupport" BO_ 2671964769 0;
BA_ "GenMsgSendType" BO_ 2671964769 8;
BA_ "DiagConnection" BO_ 2671964736 62016;
BA_ "DiagUUDTResponse" BO_ 2671964736 1;
BA_ "GenMsgILSupport" BO_ 2671964736 0;
BA_ "GenMsgSendType" BO_ 2671964736 8;
BA_ "DiagConnection" BO_ 2671834264 62616;
BA_ "DiagResponse" BO_ 2671834264 1;
BA_ "GenMsgILSupport" BO_ 2671834264 0;
BA_ "GenMsgSendType" BO_ 2671834264 8;
BA_ "DiagConnection" BO_ 2671834242 62594;
BA_ "DiagResponse" BO_ 2671834242 1;
BA_ "GenMsgILSupport" BO_ 2671834242 0;
BA_ "GenMsgSendType" BO_ 2671834242 8;
BA_ "DiagConnection" BO_ 2671834209 62561;
BA_ "DiagResponse" BO_ 2671834209 1;
BA_ "GenMsgILSupport" BO_ 2671834209 0;
BA_ "GenMsgSendType" BO_ 2671834209 8;
BA_ "DiagConnection" BO_ 2671834176 62528;
BA_ "DiagResponse" BO_ 2671834176 1;
BA_ "GenMsgILSupport" BO_ 2671834176 0;
BA_ "GenMsgSendType" BO_ 2671834176 8;
BA_ "DiagConnection" BO_ 2671810804 62616;
BA_ "DiagRequest" BO_ 2671810804 1;
BA_ "GenMsgILSupport" BO_ 2671810804 0;
BA_ "GenMsgSendType" BO_ 2671810804 8;
BA_ "DiagConnection" BO_ 2671805172 62594;
BA_ "DiagRequest" BO_ 2671805172 1;
BA_ "GenMsgILSupport" BO_ 2671805172 0;
BA_ "GenMsgSendType" BO_ 2671805172 8;
BA_ "DiagConnection" BO_ 2671796724 62561;
BA_ "DiagRequest" BO_ 2671796724 1;
BA_ "GenMsgILSupport" BO_ 2671796724 0;
BA_ "GenMsgSendType" BO_ 2671796724 8;
BA_ "DiagConnection" BO_ 2671788276 62528;
BA_ "DiagRequest" BO_ 2671788276 1;
BA_ "GenMsgILSupport" BO_ 2671788276 0;
BA_ "GenMsgSendType" BO_ 2671788276 8;
BA_ "GenMsgILSupport" BO_ 1121 0;
BA_ "VFrameFormat" BO_ 1121 0;
BA_ "GenMsgSendType" BO_ 1121 8;
BA_ "CanTpFcFrameId" BO_ 1120 1121;
BA_ "VFrameFormat" BO_ 1120 0;
BA_ "GenMsgCycleTime" BO_ 1120 500;
BA_ "VFrameFormat" BO_ 1168 0;
BA_ "GenMsgCycleTime" BO_ 1168 1000;
BA_ "GenMsgDelayTime" BO_ 1168 80;
BA_ "VFrameFormat" BO_ 912 0;
BA_ "GenMsgCycleTime" BO_ 912 500;
BA_ "VFrameFormat" BO_ 656 0;
BA_ "GenMsgCycleTime" BO_ 656 100;
BA_ "VFrameFormat" BO_ 402 0;
BA_ "GenMsgCycleTime" BO_ 402 50;
BA_ "VFrameFormat" BO_ 401 0;
BA_ "GenMsgCycleTime" BO_ 401 50;
BA_ "VFrameFormat" BO_ 400 0;
BA_ "GenMsgCycleTime" BO_ 400 50;
BA_ "VFrameFormat" BO_ 1717 0;
BA_ "GenMsgCycleTime" BO_ 1717 100;
BA_ "VFrameFormat" BO_ 1718 0;
BA_ "GenMsgCycleTime" BO_ 1718 100;
BA_ "VFrameFormat" BO_ 1716 0;
BA_ "GenMsgCycleTime" BO_ 1716 100;
BA_ "VFrameFormat" BO_ 1719 0;
BA_ "GenMsgCycleTime" BO_ 1719 100;
BA_ "GenSigCycleTime" SG_ 156 LiftAxle2LowerACK 100;
BA_ "GenSigCycleTimeActive" SG_ 156 LiftAxle2LowerACK 100;
BA_ "GenSigStartValue" SG_ 156 LiftAxle2LowerACK 7;
BA_ "GenSigMaxLatency" SG_ 156 LiftAxle2LowerACK 20;
BA_ "GenSigCycleTime" SG_ 156 LiftAxle2PositionStatus 100;
BA_ "GenSigCycleTimeActive" SG_ 156 LiftAxle2PositionStatus 100;
BA_ "GenSigStartValue" SG_ 156 LiftAxle2PositionStatus 7;
BA_ "GenSigMaxLatency" SG_ 156 LiftAxle2PositionStatus 20;
BA_ "GenSigCycleTime" SG_ 156 LiftAxle2LiftFuncSelected 100;
BA_ "GenSigCycleTimeActive" SG_ 156 LiftAxle2LiftFuncSelected 100;
BA_ "GenSigStartValue" SG_ 156 LiftAxle2LiftFuncSelected 7;
BA_ "GenSigMaxLatency" SG_ 156 LiftAxle2LiftFuncSelected 20;
BA_ "GenSigCycleTime" SG_ 156 PassengerDoorAjar_stat 100;
BA_ "GenSigCycleTimeActive" SG_ 156 PassengerDoorAjar_stat 100;
BA_ "GenSigStartValue" SG_ 156 PassengerDoorAjar_stat 7;
BA_ "GenSigMaxLatency" SG_ 156 PassengerDoorAjar_stat 20;
BA_ "GenSigCycleTime" SG_ 156 AirFlowSelectionDownBtn_stat 100;
BA_ "GenSigCycleTimeActive" SG_ 156 AirFlowSelectionDownBtn_stat 100;
BA_ "GenSigStartValue" SG_ 156 AirFlowSelectionDownBtn_stat 3;
BA_ "GenSigMaxLatency" SG_ 156 AirFlowSelectionDownBtn_stat 20;
BA_ "GenSigCycleTime" SG_ 156 LevelControlInformation 100;
BA_ "GenSigCycleTimeActive" SG_ 156 LevelControlInformation 100;
BA_ "GenSigStartValue" SG_ 156 LevelControlInformation 15;
BA_ "GenSigMaxLatency" SG_ 156 LevelControlInformation 20;
BA_ "GenSigCycleTime" SG_ 156 LiftAxle1LowerACK 100;
BA_ "GenSigCycleTimeActive" SG_ 156 LiftAxle1LowerACK 100;
BA_ "GenSigStartValue" SG_ 156 LiftAxle1LowerACK 7;
BA_ "GenSigMaxLatency" SG_ 156 LiftAxle1LowerACK 20;
BA_ "GenSigCycleTime" SG_ 156 WiperModeStatus 100;
BA_ "GenSigCycleTimeActive" SG_ 156 WiperModeStatus 100;
BA_ "GenSigStartValue" SG_ 156 WiperModeStatus 7;
BA_ "GenSigMaxLatency" SG_ 156 WiperModeStatus 20;
BA_ "GenSigCycleTime" SG_ 156 Washing_HMI_rqst 100;
BA_ "GenSigCycleTimeActive" SG_ 156 Washing_HMI_rqst 100;
BA_ "GenSigStartValue" SG_ 156 Washing_HMI_rqst 3;
BA_ "GenSigMaxLatency" SG_ 156 Washing_HMI_rqst 20;
BA_ "GenSigCycleTime" SG_ 156 LiftAxle2AutoLiftSelected 100;
BA_ "GenSigCycleTimeActive" SG_ 156 LiftAxle2AutoLiftSelected 100;
BA_ "GenSigStartValue" SG_ 156 LiftAxle2AutoLiftSelected 3;
BA_ "GenSigMaxLatency" SG_ 156 LiftAxle2AutoLiftSelected 20;
BA_ "GenSigCycleTime" SG_ 156 ReverseGearEngaged 100;
BA_ "GenSigCycleTimeActive" SG_ 156 ReverseGearEngaged 100;
BA_ "GenSigStartValue" SG_ 156 ReverseGearEngaged 3;
BA_ "GenSigMaxLatency" SG_ 156 ReverseGearEngaged 20;
BA_ "GenSigCycleTime" SG_ 156 LiftAxle1PositionStatus 100;
BA_ "GenSigCycleTimeActive" SG_ 156 LiftAxle1PositionStatus 100;
BA_ "GenSigStartValue" SG_ 156 LiftAxle1PositionStatus 7;
BA_ "GenSigMaxLatency" SG_ 156 LiftAxle1PositionStatus 20;
BA_ "GenSigCycleTime" SG_ 156 ACC_Status 100;
BA_ "GenSigCycleTimeActive" SG_ 156 ACC_Status 100;
BA_ "GenSigStartValue" SG_ 156 ACC_Status 7;
BA_ "GenSigMaxLatency" SG_ 156 ACC_Status 20;
BA_ "GenSigCycleTime" SG_ 156 LECM_CabClim_MaxDef_GuiReq 100;
BA_ "GenSigCycleTimeActive" SG_ 156 LECM_CabClim_MaxDef_GuiReq 100;
BA_ "GenSigStartValue" SG_ 156 LECM_CabClim_MaxDef_GuiReq 3;
BA_ "GenSigMaxLatency" SG_ 156 LECM_CabClim_MaxDef_GuiReq 20;
BA_ "GenSigCycleTime" SG_ 156 RegenerationSwitchStatus 100;
BA_ "GenSigCycleTimeActive" SG_ 156 RegenerationSwitchStatus 100;
BA_ "GenSigStartValue" SG_ 156 RegenerationSwitchStatus 7;
BA_ "GenSigMaxLatency" SG_ 156 RegenerationSwitchStatus 20;
BA_ "GenSigCycleTime" SG_ 156 DSWindowPosition 100;
BA_ "GenSigCycleTimeActive" SG_ 156 DSWindowPosition 100;
BA_ "GenSigStartValue" SG_ 156 DSWindowPosition 7;
BA_ "GenSigMaxLatency" SG_ 156 DSWindowPosition 20;
BA_ "GenSigCycleTime" SG_ 156 WindscreenDefrost_ButtonStatus 100;
BA_ "GenSigCycleTimeActive" SG_ 156 WindscreenDefrost_ButtonStatus 100;
BA_ "GenSigStartValue" SG_ 156 WindscreenDefrost_ButtonStatus 3;
BA_ "GenSigMaxLatency" SG_ 156 WindscreenDefrost_ButtonStatus 20;
BA_ "GenSigCycleTime" SG_ 156 GearSplit_Status 100;
BA_ "GenSigCycleTimeActive" SG_ 156 GearSplit_Status 100;
BA_ "GenSigStartValue" SG_ 156 GearSplit_Status 3;
BA_ "GenSigMaxLatency" SG_ 156 GearSplit_Status 20;
BA_ "GenSigCycleTime" SG_ 156 KeyPosition 100;
BA_ "GenSigCycleTimeActive" SG_ 156 KeyPosition 100;
BA_ "GenSigStartValue" SG_ 156 KeyPosition 7;
BA_ "GenSigMaxLatency" SG_ 156 KeyPosition 20;
BA_ "GenSigCycleTime" SG_ 156 LiftAxle1LiftFuncSelected 100;
BA_ "GenSigCycleTimeActive" SG_ 156 LiftAxle1LiftFuncSelected 100;
BA_ "GenSigStartValue" SG_ 156 LiftAxle1LiftFuncSelected 7;
BA_ "GenSigMaxLatency" SG_ 156 LiftAxle1LiftFuncSelected 20;
BA_ "GenSigCycleTime" SG_ 156 LiftAxle2UpRequestACK 100;
BA_ "GenSigCycleTimeActive" SG_ 156 LiftAxle2UpRequestACK 100;
BA_ "GenSigStartValue" SG_ 156 LiftAxle2UpRequestACK 7;
BA_ "GenSigMaxLatency" SG_ 156 LiftAxle2UpRequestACK 20;
BA_ "GenSigCycleTime" SG_ 156 PreTrip_ButtonStat3 100;
BA_ "GenSigCycleTimeActive" SG_ 156 PreTrip_ButtonStat3 100;
BA_ "GenSigStartValue" SG_ 156 PreTrip_ButtonStat3 3;
BA_ "GenSigMaxLatency" SG_ 156 PreTrip_ButtonStat3 20;
BA_ "GenSigCycleTime" SG_ 156 LiftAxle1UpRequestACK 100;
BA_ "GenSigCycleTimeActive" SG_ 156 LiftAxle1UpRequestACK 100;
BA_ "GenSigStartValue" SG_ 156 LiftAxle1UpRequestACK 7;
BA_ "GenSigMaxLatency" SG_ 156 LiftAxle1UpRequestACK 20;
BA_ "GenSigCycleTime" SG_ 154 EngineSpeed 100;
BA_ "GenSigCycleTimeActive" SG_ 154 EngineSpeed 100;
BA_ "GenSigStartValue" SG_ 154 EngineSpeed 65535;
BA_ "GenSigMaxLatency" SG_ 154 EngineSpeed 20;
BA_ "GenSigCycleTime" SG_ 154 SteeringWheelAngle 100;
BA_ "GenSigCycleTimeActive" SG_ 154 SteeringWheelAngle 100;
BA_ "GenSigStartValue" SG_ 154 SteeringWheelAngle 65535;
BA_ "GenSigMaxLatency" SG_ 154 SteeringWheelAngle 20;
BA_ "GenSigCycleTime" SG_ 154 LateralAcceleration 100;
BA_ "GenSigCycleTimeActive" SG_ 154 LateralAcceleration 100;
BA_ "GenSigStartValue" SG_ 154 LateralAcceleration 65535;
BA_ "GenSigMaxLatency" SG_ 154 LateralAcceleration 20;
BA_ "GenSigCycleTime" SG_ 138 AcceleratorPedalLowIdleSwitch 100;
BA_ "GenSigCycleTimeActive" SG_ 138 AcceleratorPedalLowIdleSwitch 100;
BA_ "GenSigStartValue" SG_ 138 AcceleratorPedalLowIdleSwitch 3;
BA_ "GenSigMaxLatency" SG_ 138 AcceleratorPedalLowIdleSwitch 10;
BA_ "GenSigCycleTime" SG_ 138 VehicleMode 100;
BA_ "GenSigCycleTimeActive" SG_ 138 VehicleMode 100;
BA_ "GenSigStartValue" SG_ 138 VehicleMode 15;
BA_ "GenSigCycleTime" SG_ 138 AcceleratorPedalPosition1 100;
BA_ "GenSigCycleTimeActive" SG_ 138 AcceleratorPedalPosition1 100;
BA_ "GenSigStartValue" SG_ 138 AcceleratorPedalPosition1 255;
BA_ "GenSigMaxLatency" SG_ 138 AcceleratorPedalPosition1 10;
BA_ "GenSigCycleTime" SG_ 138 AcceleratorPedalQuality 100;
BA_ "GenSigCycleTimeActive" SG_ 138 AcceleratorPedalQuality 100;
BA_ "GenSigStartValue" SG_ 138 AcceleratorPedalQuality 3;
BA_ "GenSigMaxLatency" SG_ 138 AcceleratorPedalQuality 10;
BA_ "GenSigCycleTime" SG_ 895 DriverCrank_rqst 100;
BA_ "GenSigCycleTimeActive" SG_ 895 DriverCrank_rqst 100;
BA_ "GenSigStartValue" SG_ 895 DriverCrank_rqst 3;
BA_ "GenSigMaxLatency" SG_ 895 DriverCrank_rqst 50;
BA_ "GenSigCycleTime" SG_ 895 EngineStartControlStatus 100;
BA_ "GenSigCycleTimeActive" SG_ 895 EngineStartControlStatus 100;
BA_ "GenSigStartValue" SG_ 895 EngineStartControlStatus 65535;
BA_ "GenSigMaxLatency" SG_ 895 EngineStartControlStatus 50;
BA_ "GenSigCycleTime" SG_ 895 WheelBasedVehicleSpd_Value 100;
BA_ "GenSigCycleTimeActive" SG_ 895 WheelBasedVehicleSpd_Value 100;
BA_ "GenSigStartValue" SG_ 895 WheelBasedVehicleSpd_Value 65535;
BA_ "GenSigMaxLatency" SG_ 895 WheelBasedVehicleSpd_Value 100;
BA_ "GenSigCycleTime" SG_ 895 WheelBasedVehicleSpd_CRC 100;
BA_ "GenSigCycleTimeActive" SG_ 895 WheelBasedVehicleSpd_CRC 100;
BA_ "GenSigStartValue" SG_ 895 WheelBasedVehicleSpd_CRC 255;
BA_ "GenSigMaxLatency" SG_ 895 WheelBasedVehicleSpd_CRC 100;
BA_ "E2EDataId" SG_ 895 WheelBasedVehicleSpd_CRC 178;
BA_ "E2EDataLength" SG_ 895 WheelBasedVehicleSpd_CRC 32;
BA_ "E2EProfile" SG_ 895 WheelBasedVehicleSpd_CRC "P01";
BA_ "GenSigCycleTime" SG_ 895 CabTiltLockStatus 100;
BA_ "GenSigCycleTimeActive" SG_ 895 CabTiltLockStatus 100;
BA_ "GenSigStartValue" SG_ 895 CabTiltLockStatus 3;
BA_ "GenSigMaxLatency" SG_ 895 CabTiltLockStatus 50;
BA_ "GenSigCycleTime" SG_ 895 WheelBasedVehicleSpd_SqC 100;
BA_ "GenSigCycleTimeActive" SG_ 895 WheelBasedVehicleSpd_SqC 100;
BA_ "GenSigStartValue" SG_ 895 WheelBasedVehicleSpd_SqC 14;
BA_ "GenSigMaxLatency" SG_ 895 WheelBasedVehicleSpd_SqC 100;
BA_ "GenSigCycleTime" SG_ 895 CabTiltEnableStatus 100;
BA_ "GenSigCycleTimeActive" SG_ 895 CabTiltEnableStatus 100;
BA_ "GenSigStartValue" SG_ 895 CabTiltEnableStatus 3;
BA_ "GenSigMaxLatency" SG_ 895 CabTiltEnableStatus 50;
BA_ "GenSigSendType" SG_ 2671902706 FuncDiagDataTester 7;
BA_ "GenSigSendType" SG_ 2671902708 FuncDiagDataIntTesterF4 7;
BA_ "GenSigCycleTime" SG_ 1104 CabTilt_rqst 100;
BA_ "GenSigCycleTimeActive" SG_ 1104 CabTilt_rqst 100;
BA_ "GenSigStartValue" SG_ 1104 CabTilt_rqst 3;
BA_ "GenSigMaxLatency" SG_ 1104 CabTilt_rqst 100;
BA_ "GenSigCycleTime" SG_ 432 DriverSeatBeltSwitch 100;
BA_ "GenSigCycleTimeActive" SG_ 432 DriverSeatBeltSwitch 100;
BA_ "GenSigStartValue" SG_ 432 DriverSeatBeltSwitch 3;
BA_ "GenSigMaxLatency" SG_ 432 DriverSeatBeltSwitch 50;
BA_ "GenSigCycleTime" SG_ 432 FrontLidAjar_Stat 100;
BA_ "GenSigCycleTimeActive" SG_ 432 FrontLidAjar_Stat 100;
BA_ "GenSigStartValue" SG_ 432 FrontLidAjar_Stat 3;
BA_ "GenSigMaxLatency" SG_ 432 FrontLidAjar_Stat 50;
BA_ "GenSigCycleTime" SG_ 432 LevelingThumbwheel_stat 100;
BA_ "GenSigCycleTimeActive" SG_ 432 LevelingThumbwheel_stat 100;
BA_ "GenSigStartValue" SG_ 432 LevelingThumbwheel_stat 31;
BA_ "GenSigMaxLatency" SG_ 432 LevelingThumbwheel_stat 50;
BA_ "GenSigCycleTime" SG_ 179 LightMode_Status_Ctr_1 100;
BA_ "GenSigCycleTimeActive" SG_ 179 LightMode_Status_Ctr_1 100;
BA_ "GenSigStartValue" SG_ 179 LightMode_Status_Ctr_1 15;
BA_ "GenSigMaxLatency" SG_ 179 LightMode_Status_Ctr_1 20;
BA_ "GenSigCycleTime" SG_ 179 ReverseWarning_rqst 100;
BA_ "GenSigCycleTimeActive" SG_ 179 ReverseWarning_rqst 100;
BA_ "GenSigStartValue" SG_ 179 ReverseWarning_rqst 3;
BA_ "GenSigMaxLatency" SG_ 179 ReverseWarning_rqst 20;
BA_ "GenSigCycleTime" SG_ 179 FogLightFront_ButtonStatus_1 100;
BA_ "GenSigCycleTimeActive" SG_ 179 FogLightFront_ButtonStatus_1 100;
BA_ "GenSigStartValue" SG_ 179 FogLightFront_ButtonStatus_1 3;
BA_ "GenSigMaxLatency" SG_ 179 FogLightFront_ButtonStatus_1 20;
BA_ "GenSigCycleTime" SG_ 179 FogLightRear_ButtonStatus_1 100;
BA_ "GenSigCycleTimeActive" SG_ 179 FogLightRear_ButtonStatus_1 100;
BA_ "GenSigStartValue" SG_ 179 FogLightRear_ButtonStatus_1 3;
BA_ "GenSigMaxLatency" SG_ 179 FogLightRear_ButtonStatus_1 20;
BA_ "GenSigSendType" SG_ 2671833752 PhysDiagRespSig_F2_98 7;
BA_ "GenSigSendType" SG_ 2671833730 PhysDiagRespSig_F2_82 7;
BA_ "GenSigSendType" SG_ 2671833697 PhysDiagRespSig_F2_61 7;
BA_ "GenSigSendType" SG_ 2671833664 PhysDiagRespSig_F2_40 7;
BA_ "GenSigSendType" SG_ 2671810802 PhysDiagReqSig_98_F2 7;
BA_ "GenSigSendType" SG_ 2671805170 PhysDiagReqSig_82_F2 7;
BA_ "GenSigSendType" SG_ 2671796722 PhysDiagReqSig_61_F2 7;
BA_ "GenSigSendType" SG_ 2671788274 PhysDiagReqSig_40_F2 7;
BA_ "GenSigSendType" SG_ 1457 IC_09S_C05_FCS 7;
BA_ "GenSigSendType" SG_ 1456 ECU3VIN_stat 1;
BA_ "GenSigMaxLatency" SG_ 1456 ECU3VIN_stat 1000;
BA_ "GenSigCycleTime" SG_ 1184 FasDampingSetting_rqst 100;
BA_ "GenSigCycleTimeActive" SG_ 1184 FasDampingSetting_rqst 100;
BA_ "GenSigStartValue" SG_ 1184 FasDampingSetting_rqst 31;
BA_ "GenSigMaxLatency" SG_ 1184 FasDampingSetting_rqst 1000;
BA_ "GenSigCycleTime" SG_ 1184 FasPersonalSettingsButton_rqst 100;
BA_ "GenSigCycleTimeActive" SG_ 1184 FasPersonalSettingsButton_rqst 100;
BA_ "GenSigStartValue" SG_ 1184 FasPersonalSettingsButton_rqst 7;
BA_ "GenSigMaxLatency" SG_ 1184 FasPersonalSettingsButton_rqst 1000;
BA_ "GenSigCycleTime" SG_ 1184 FasStiffnessCurveSetting_rqst 100;
BA_ "GenSigCycleTimeActive" SG_ 1184 FasStiffnessCurveSetting_rqst 100;
BA_ "GenSigStartValue" SG_ 1184 FasStiffnessCurveSetting_rqst 31;
BA_ "GenSigMaxLatency" SG_ 1184 FasStiffnessCurveSetting_rqst 1000;
BA_ "GenSigCycleTime" SG_ 1184 FasDriver_rqst 100;
BA_ "GenSigCycleTimeActive" SG_ 1184 FasDriver_rqst 100;
BA_ "GenSigStartValue" SG_ 1184 FasDriver_rqst 15;
BA_ "GenSigMaxLatency" SG_ 1184 FasDriver_rqst 1000;
BA_ "GenSigCycleTime" SG_ 1184 FasUsrDefinedStorage_rqst 100;
BA_ "GenSigCycleTimeActive" SG_ 1184 FasUsrDefinedStorage_rqst 100;
BA_ "GenSigStartValue" SG_ 1184 FasUsrDefinedStorage_rqst 3;
BA_ "GenSigMaxLatency" SG_ 1184 FasUsrDefinedStorage_rqst 1000;
BA_ "GenSigCycleTime" SG_ 1184 FasStiffStraightSetting_rqst 100;
BA_ "GenSigCycleTimeActive" SG_ 1184 FasStiffStraightSetting_rqst 100;
BA_ "GenSigStartValue" SG_ 1184 FasStiffStraightSetting_rqst 31;
BA_ "GenSigMaxLatency" SG_ 1184 FasStiffStraightSetting_rqst 1000;
BA_ "GenSigCycleTime" SG_ 1184 FasLowSpeedReturnSetting_rqst 100;
BA_ "GenSigCycleTimeActive" SG_ 1184 FasLowSpeedReturnSetting_rqst 100;
BA_ "GenSigStartValue" SG_ 1184 FasLowSpeedReturnSetting_rqst 31;
BA_ "GenSigMaxLatency" SG_ 1184 FasLowSpeedReturnSetting_rqst 1000;
BA_ "GenSigCycleTime" SG_ 1184 FasManualOffsetSetting_rqst 100;
BA_ "GenSigCycleTimeActive" SG_ 1184 FasManualOffsetSetting_rqst 100;
BA_ "GenSigStartValue" SG_ 1184 FasManualOffsetSetting_rqst 31;
BA_ "GenSigMaxLatency" SG_ 1184 FasManualOffsetSetting_rqst 1000;
BA_ "GenSigCycleTime" SG_ 932 DPF_ManualRegenerateRequest 100;
BA_ "GenSigCycleTimeActive" SG_ 932 DPF_ManualRegenerateRequest 100;
BA_ "GenSigStartValue" SG_ 932 DPF_ManualRegenerateRequest 3;
BA_ "GenSigMaxLatency" SG_ 932 DPF_ManualRegenerateRequest 500;
BA_ "GenSigCycleTime" SG_ 932 DPF_ManualRegenerateInhibit 100;
BA_ "GenSigCycleTimeActive" SG_ 932 DPF_ManualRegenerateInhibit 100;
BA_ "GenSigStartValue" SG_ 932 DPF_ManualRegenerateInhibit 3;
BA_ "GenSigMaxLatency" SG_ 932 DPF_ManualRegenerateInhibit 500;
BA_ "GenSigCycleTime" SG_ 932 DPF_ManualRegenerateTimeReq 100;
BA_ "GenSigCycleTimeActive" SG_ 932 DPF_ManualRegenerateTimeReq 100;
BA_ "GenSigStartValue" SG_ 932 DPF_ManualRegenerateTimeReq 3;
BA_ "GenSigMaxLatency" SG_ 932 DPF_ManualRegenerateTimeReq 500;
BA_ "GenSigCycleTime" SG_ 930 OBDRelDTC_IC_DrvngCycleB 100;
BA_ "GenSigCycleTimeActive" SG_ 930 OBDRelDTC_IC_DrvngCycleB 100;
BA_ "GenSigStartValue" SG_ 930 OBDRelDTC_IC_DrvngCycleB 3;
BA_ "GenSigMaxLatency" SG_ 930 OBDRelDTC_IC_DrvngCycleB 510;
BA_ "GenSigCycleTime" SG_ 930 OBDRelDTC_IC_EvalResultA 100;
BA_ "GenSigCycleTimeActive" SG_ 930 OBDRelDTC_IC_EvalResultA 100;
BA_ "GenSigStartValue" SG_ 930 OBDRelDTC_IC_EvalResultA 3;
BA_ "GenSigMaxLatency" SG_ 930 OBDRelDTC_IC_EvalResultA 510;
BA_ "GenSigCycleTime" SG_ 930 OBDRelDTC_IC_EvalResultB 100;
BA_ "GenSigCycleTimeActive" SG_ 930 OBDRelDTC_IC_EvalResultB 100;
BA_ "GenSigStartValue" SG_ 930 OBDRelDTC_IC_EvalResultB 3;
BA_ "GenSigMaxLatency" SG_ 930 OBDRelDTC_IC_EvalResultB 510;
BA_ "GenSigCycleTime" SG_ 930 OBDRelDTC_IC_EvalStatA 100;
BA_ "GenSigCycleTimeActive" SG_ 930 OBDRelDTC_IC_EvalStatA 100;
BA_ "GenSigStartValue" SG_ 930 OBDRelDTC_IC_EvalStatA 3;
BA_ "GenSigMaxLatency" SG_ 930 OBDRelDTC_IC_EvalStatA 510;
BA_ "GenSigCycleTime" SG_ 930 OBDRelDTC_IC_DtcIdB 100;
BA_ "GenSigCycleTimeActive" SG_ 930 OBDRelDTC_IC_DtcIdB 100;
BA_ "GenSigMaxLatency" SG_ 930 OBDRelDTC_IC_DtcIdB 510;
BA_ "GenSigCycleTime" SG_ 930 OBDRelDTC_IC_DrvngCycleA 100;
BA_ "GenSigCycleTimeActive" SG_ 930 OBDRelDTC_IC_DrvngCycleA 100;
BA_ "GenSigStartValue" SG_ 930 OBDRelDTC_IC_DrvngCycleA 3;
BA_ "GenSigMaxLatency" SG_ 930 OBDRelDTC_IC_DrvngCycleA 510;
BA_ "GenSigCycleTime" SG_ 930 OBDRelDTC_IC_FailTB 100;
BA_ "GenSigCycleTimeActive" SG_ 930 OBDRelDTC_IC_FailTB 100;
BA_ "GenSigMaxLatency" SG_ 930 OBDRelDTC_IC_FailTB 510;
BA_ "GenSigCycleTime" SG_ 930 OBDRelDTC_IC_DtcIdA 100;
BA_ "GenSigCycleTimeActive" SG_ 930 OBDRelDTC_IC_DtcIdA 100;
BA_ "GenSigMaxLatency" SG_ 930 OBDRelDTC_IC_DtcIdA 510;
BA_ "GenSigCycleTime" SG_ 930 OBDRelDTC_IC_FailTA 100;
BA_ "GenSigCycleTimeActive" SG_ 930 OBDRelDTC_IC_FailTA 100;
BA_ "GenSigMaxLatency" SG_ 930 OBDRelDTC_IC_FailTA 510;
BA_ "GenSigCycleTime" SG_ 930 OBDRelDTC_IC_EvalStatB 100;
BA_ "GenSigCycleTimeActive" SG_ 930 OBDRelDTC_IC_EvalStatB 100;
BA_ "GenSigStartValue" SG_ 930 OBDRelDTC_IC_EvalStatB 3;
BA_ "GenSigMaxLatency" SG_ 930 OBDRelDTC_IC_EvalStatB 510;
BA_ "GenSigCycleTime" SG_ 928 Set_LG5CutoffValue 100;
BA_ "GenSigCycleTimeActive" SG_ 928 Set_LG5CutoffValue 100;
BA_ "GenSigStartValue" SG_ 928 Set_LG5CutoffValue 255;
BA_ "GenSigMaxLatency" SG_ 928 Set_LG5CutoffValue 515;
BA_ "GenSigCycleTime" SG_ 928 Set_LG3CutoffValue 100;
BA_ "GenSigCycleTimeActive" SG_ 928 Set_LG3CutoffValue 100;
BA_ "GenSigStartValue" SG_ 928 Set_LG3CutoffValue 255;
BA_ "GenSigMaxLatency" SG_ 928 Set_LG3CutoffValue 515;
BA_ "GenSigCycleTime" SG_ 928 Set_LG1CutoffValue 100;
BA_ "GenSigCycleTimeActive" SG_ 928 Set_LG1CutoffValue 100;
BA_ "GenSigStartValue" SG_ 928 Set_LG1CutoffValue 255;
BA_ "GenSigMaxLatency" SG_ 928 Set_LG1CutoffValue 515;
BA_ "GenSigCycleTime" SG_ 928 Set_LG2CutoffValue 100;
BA_ "GenSigCycleTimeActive" SG_ 928 Set_LG2CutoffValue 100;
BA_ "GenSigStartValue" SG_ 928 Set_LG2CutoffValue 255;
BA_ "GenSigMaxLatency" SG_ 928 Set_LG2CutoffValue 515;
BA_ "GenSigCycleTime" SG_ 928 Set_LG4CutoffValue 100;
BA_ "GenSigCycleTimeActive" SG_ 928 Set_LG4CutoffValue 100;
BA_ "GenSigStartValue" SG_ 928 Set_LG4CutoffValue 255;
BA_ "GenSigMaxLatency" SG_ 928 Set_LG4CutoffValue 515;
BA_ "GenSigCycleTime" SG_ 928 Set_EnergySetting 100;
BA_ "GenSigCycleTimeActive" SG_ 928 Set_EnergySetting 100;
BA_ "GenSigStartValue" SG_ 928 Set_EnergySetting 7;
BA_ "GenSigMaxLatency" SG_ 928 Set_EnergySetting 515;
BA_ "GenSigCycleTime" SG_ 928 Set_LG6CutoffValue 100;
BA_ "GenSigCycleTimeActive" SG_ 928 Set_LG6CutoffValue 100;
BA_ "GenSigStartValue" SG_ 928 Set_LG6CutoffValue 255;
BA_ "GenSigMaxLatency" SG_ 928 Set_LG6CutoffValue 515;
BA_ "GenSigCycleTime" SG_ 784 SpeedAdaptEnableRqst_SpeedLimit 100;
BA_ "GenSigCycleTimeActive" SG_ 784 SpeedAdaptEnableRqst_SpeedLimit 100;
BA_ "GenSigStartValue" SG_ 784 SpeedAdaptEnableRqst_SpeedLimit 3;
BA_ "GenSigMaxLatency" SG_ 784 SpeedAdaptEnableRqst_SpeedLimit 200;
BA_ "GenSigCycleTime" SG_ 784 SpeedAdaptEnableRqst_SlowTraffic 100;
BA_ "GenSigCycleTimeActive" SG_ 784 SpeedAdaptEnableRqst_SlowTraffic 100;
BA_ "GenSigStartValue" SG_ 784 SpeedAdaptEnableRqst_SlowTraffic 3;
BA_ "GenSigMaxLatency" SG_ 784 SpeedAdaptEnableRqst_SlowTraffic 200;
BA_ "GenSigCycleTime" SG_ 784 BattEnergySetLevel_input 100;
BA_ "GenSigCycleTimeActive" SG_ 784 BattEnergySetLevel_input 100;
BA_ "GenSigStartValue" SG_ 784 BattEnergySetLevel_input 7;
BA_ "GenSigMaxLatency" SG_ 784 BattEnergySetLevel_input 200;
BA_ "GenSigCycleTime" SG_ 784 SpeedAdaptationLevelRqst 100;
BA_ "GenSigCycleTimeActive" SG_ 784 SpeedAdaptationLevelRqst 100;
BA_ "GenSigStartValue" SG_ 784 SpeedAdaptationLevelRqst 7;
BA_ "GenSigMaxLatency" SG_ 784 SpeedAdaptationLevelRqst 200;
BA_ "GenSigCycleTime" SG_ 784 SpeedAdaptEnableRqst_Curve 100;
BA_ "GenSigCycleTimeActive" SG_ 784 SpeedAdaptEnableRqst_Curve 100;
BA_ "GenSigStartValue" SG_ 784 SpeedAdaptEnableRqst_Curve 3;
BA_ "GenSigMaxLatency" SG_ 784 SpeedAdaptEnableRqst_Curve 200;
BA_ "GenSigCycleTime" SG_ 784 ExtraHeating_rqst 100;
BA_ "GenSigCycleTimeActive" SG_ 784 ExtraHeating_rqst 100;
BA_ "GenSigStartValue" SG_ 784 ExtraHeating_rqst 7;
BA_ "GenSigMaxLatency" SG_ 784 ExtraHeating_rqst 200;
BA_ "GenSigCycleTime" SG_ 672 ParkingHeaterCleaning_cmd 100;
BA_ "GenSigCycleTimeActive" SG_ 672 ParkingHeaterCleaning_cmd 100;
BA_ "GenSigStartValue" SG_ 672 ParkingHeaterCleaning_cmd 3;
BA_ "GenSigMaxLatency" SG_ 672 ParkingHeaterCleaning_cmd 100;
BA_ "GenSigCycleTime" SG_ 672 DriverMemory_rqst 100;
BA_ "GenSigCycleTimeActive" SG_ 672 DriverMemory_rqst 100;
BA_ "GenSigStartValue" SG_ 672 DriverMemory_rqst 31;
BA_ "GenSigMaxLatency" SG_ 672 DriverMemory_rqst 100;
BA_ "GenSigCycleTime" SG_ 672 FirstAxleLowerPrioRequested 100;
BA_ "GenSigCycleTimeActive" SG_ 672 FirstAxleLowerPrioRequested 100;
BA_ "GenSigStartValue" SG_ 672 FirstAxleLowerPrioRequested 7;
BA_ "GenSigMaxLatency" SG_ 672 FirstAxleLowerPrioRequested 100;
BA_ "GenSigCycleTime" SG_ 672 AutoShutOffAnswerInput 100;
BA_ "GenSigCycleTimeActive" SG_ 672 AutoShutOffAnswerInput 100;
BA_ "GenSigStartValue" SG_ 672 AutoShutOffAnswerInput 7;
BA_ "GenSigMaxLatency" SG_ 672 AutoShutOffAnswerInput 100;
BA_ "GenSigCycleTime" SG_ 672 ManualEngineCoolingDev_Ind 100;
BA_ "GenSigCycleTimeActive" SG_ 672 ManualEngineCoolingDev_Ind 100;
BA_ "GenSigStartValue" SG_ 672 ManualEngineCoolingDev_Ind 3;
BA_ "GenSigMaxLatency" SG_ 672 ManualEngineCoolingDev_Ind 100;
BA_ "GenSigCycleTime" SG_ 672 TemporaryRSLDeviceIndication 100;
BA_ "GenSigCycleTimeActive" SG_ 672 TemporaryRSLDeviceIndication 100;
BA_ "GenSigStartValue" SG_ 672 TemporaryRSLDeviceIndication 3;
BA_ "GenSigMaxLatency" SG_ 672 TemporaryRSLDeviceIndication 100;
BA_ "GenSigCycleTime" SG_ 672 ESC_ButtonIndication2 100;
BA_ "GenSigCycleTimeActive" SG_ 672 ESC_ButtonIndication2 100;
BA_ "GenSigStartValue" SG_ 672 ESC_ButtonIndication2 3;
BA_ "GenSigMaxLatency" SG_ 672 ESC_ButtonIndication2 100;
BA_ "GenSigCycleTime" SG_ 672 WaterInFuelDrainRequest 100;
BA_ "GenSigCycleTimeActive" SG_ 672 WaterInFuelDrainRequest 100;
BA_ "GenSigStartValue" SG_ 672 WaterInFuelDrainRequest 3;
BA_ "GenSigMaxLatency" SG_ 672 WaterInFuelDrainRequest 100;
BA_ "GenSigCycleTime" SG_ 672 PreTripIndication3 100;
BA_ "GenSigCycleTimeActive" SG_ 672 PreTripIndication3 100;
BA_ "GenSigStartValue" SG_ 672 PreTripIndication3 3;
BA_ "GenSigMaxLatency" SG_ 672 PreTripIndication3 100;
BA_ "GenSigCycleTime" SG_ 672 ESCOff_DeviceIndication 100;
BA_ "GenSigCycleTimeActive" SG_ 672 ESCOff_DeviceIndication 100;
BA_ "GenSigStartValue" SG_ 672 ESCOff_DeviceIndication 3;
BA_ "GenSigMaxLatency" SG_ 672 ESCOff_DeviceIndication 100;
BA_ "GenSigCycleTime" SG_ 672 AWBEnableRequest 100;
BA_ "GenSigCycleTimeActive" SG_ 672 AWBEnableRequest 100;
BA_ "GenSigStartValue" SG_ 672 AWBEnableRequest 3;
BA_ "GenSigMaxLatency" SG_ 672 AWBEnableRequest 100;
BA_ "GenSigCycleTime" SG_ 672 LampCheck_rqst 100;
BA_ "GenSigCycleTimeActive" SG_ 672 LampCheck_rqst 100;
BA_ "GenSigStartValue" SG_ 672 LampCheck_rqst 3;
BA_ "GenSigMaxLatency" SG_ 672 LampCheck_rqst 100;
BA_ "GenSigCycleTime" SG_ 416 SSReq_Repetition 100;
BA_ "GenSigCycleTimeActive" SG_ 416 SSReq_Repetition 100;
BA_ "GenSigMaxLatency" SG_ 416 SSReq_Repetition 50;
BA_ "GenSigCycleTime" SG_ 416 SSReq_Balance 100;
BA_ "GenSigCycleTimeActive" SG_ 416 SSReq_Balance 100;
BA_ "GenSigMaxLatency" SG_ 416 SSReq_Balance 50;
BA_ "GenSigCycleTime" SG_ 416 SSReq_Time 100;
BA_ "GenSigCycleTimeActive" SG_ 416 SSReq_Time 100;
BA_ "GenSigMaxLatency" SG_ 416 SSReq_Time 50;
BA_ "GenSigCycleTime" SG_ 416 PhoneButtonIndication_cmd 100;
BA_ "GenSigCycleTimeActive" SG_ 416 PhoneButtonIndication_cmd 100;
BA_ "GenSigStartValue" SG_ 416 PhoneButtonIndication_cmd 3;
BA_ "GenSigMaxLatency" SG_ 416 PhoneButtonIndication_cmd 50;
BA_ "GenSigCycleTime" SG_ 416 FuncIndIlluminationLevel 100;
BA_ "GenSigCycleTimeActive" SG_ 416 FuncIndIlluminationLevel 100;
BA_ "GenSigStartValue" SG_ 416 FuncIndIlluminationLevel 1;
BA_ "GenSigMaxLatency" SG_ 416 FuncIndIlluminationLevel 50;
BA_ "GenSigCycleTime" SG_ 416 BacklightCmd 100;
BA_ "GenSigCycleTimeActive" SG_ 416 BacklightCmd 100;
BA_ "GenSigMaxLatency" SG_ 416 BacklightCmd 50;
BA_ "GenSigCycleTime" SG_ 416 SSReq_Id 100;
BA_ "GenSigCycleTimeActive" SG_ 416 SSReq_Id 100;
BA_ "GenSigMaxLatency" SG_ 416 SSReq_Id 50;
BA_ "GenSigCycleTime" SG_ 416 SSReq_Mixed 100;
BA_ "GenSigCycleTimeActive" SG_ 416 SSReq_Mixed 100;
BA_ "GenSigMaxLatency" SG_ 416 SSReq_Mixed 50;
BA_ "GenSigCycleTime" SG_ 416 BunkBacklightCmd 100;
BA_ "GenSigCycleTimeActive" SG_ 416 BunkBacklightCmd 100;
BA_ "GenSigStartValue" SG_ 416 BunkBacklightCmd 31;
BA_ "GenSigMaxLatency" SG_ 416 BunkBacklightCmd 50;
BA_ "GenSigCycleTime" SG_ 416 SSReq_State 100;
BA_ "GenSigCycleTimeActive" SG_ 416 SSReq_State 100;
BA_ "GenSigMaxLatency" SG_ 416 SSReq_State 50;
BA_ "GenSigCycleTime" SG_ 416 SSReq_Volume 100;
BA_ "GenSigCycleTimeActive" SG_ 416 SSReq_Volume 100;
BA_ "GenSigMaxLatency" SG_ 416 SSReq_Volume 50;
BA_ "GenSigCycleTime" SG_ 211 TimeGapBtnStat 100;
BA_ "GenSigCycleTimeActive" SG_ 211 TimeGapBtnStat 100;
BA_ "GenSigStartValue" SG_ 211 TimeGapBtnStat 3;
BA_ "GenSigMaxLatency" SG_ 211 TimeGapBtnStat 30;
BA_ "GenSigCycleTime" SG_ 211 ATC_ButtonIndication 100;
BA_ "GenSigCycleTimeActive" SG_ 211 ATC_ButtonIndication 100;
BA_ "GenSigStartValue" SG_ 211 ATC_ButtonIndication 3;
BA_ "GenSigMaxLatency" SG_ 211 ATC_ButtonIndication 30;
BA_ "GenSigCycleTime" SG_ 211 PauseOffBtnStat 100;
BA_ "GenSigCycleTimeActive" SG_ 211 PauseOffBtnStat 100;
BA_ "GenSigStartValue" SG_ 211 PauseOffBtnStat 3;
BA_ "GenSigMaxLatency" SG_ 211 PauseOffBtnStat 30;
BA_ "GenSigCycleTime" SG_ 211 ABS_ButtonIndication 100;
BA_ "GenSigCycleTimeActive" SG_ 211 ABS_ButtonIndication 100;
BA_ "GenSigStartValue" SG_ 211 ABS_ButtonIndication 3;
BA_ "GenSigMaxLatency" SG_ 211 ABS_ButtonIndication 30;
BA_ "GenSigCycleTime" SG_ 211 SW_HeadlightInterrupt_Stat 100;
BA_ "GenSigCycleTimeActive" SG_ 211 SW_HeadlightInterrupt_Stat 100;
BA_ "GenSigStartValue" SG_ 211 SW_HeadlightInterrupt_Stat 3;
BA_ "GenSigMaxLatency" SG_ 211 SW_HeadlightInterrupt_Stat 30;
BA_ "GenSigCycleTime" SG_ 211 PBAlertActiveStatus 100;
BA_ "GenSigCycleTimeActive" SG_ 211 PBAlertActiveStatus 100;
BA_ "GenSigStartValue" SG_ 211 PBAlertActiveStatus 7;
BA_ "GenSigMaxLatency" SG_ 211 PBAlertActiveStatus 30;
BA_ "GenSigCycleTime" SG_ 211 EcoRollEnableRequest 100;
BA_ "GenSigCycleTimeActive" SG_ 211 EcoRollEnableRequest 100;
BA_ "GenSigStartValue" SG_ 211 EcoRollEnableRequest 3;
BA_ "GenSigMaxLatency" SG_ 211 EcoRollEnableRequest 30;
BA_ "GenSigCycleTime" SG_ 211 EcoSettingsBtnStat 100;
BA_ "GenSigCycleTimeActive" SG_ 211 EcoSettingsBtnStat 100;
BA_ "GenSigStartValue" SG_ 211 EcoSettingsBtnStat 3;
BA_ "GenSigMaxLatency" SG_ 211 EcoSettingsBtnStat 30;
BA_ "GenSigCycleTime" SG_ 211 SkipNextBtnStat 100;
BA_ "GenSigCycleTimeActive" SG_ 211 SkipNextBtnStat 100;
BA_ "GenSigStartValue" SG_ 211 SkipNextBtnStat 3;
BA_ "GenSigMaxLatency" SG_ 211 SkipNextBtnStat 30;
BA_ "GenSigCycleTime" SG_ 211 TCS_ButtonIndication 100;
BA_ "GenSigCycleTimeActive" SG_ 211 TCS_ButtonIndication 100;
BA_ "GenSigStartValue" SG_ 211 TCS_ButtonIndication 3;
BA_ "GenSigMaxLatency" SG_ 211 TCS_ButtonIndication 30;
BA_ "GenSigCycleTime" SG_ 211 DHCBtnStat 100;
BA_ "GenSigCycleTimeActive" SG_ 211 DHCBtnStat 100;
BA_ "GenSigStartValue" SG_ 211 DHCBtnStat 3;
BA_ "GenSigMaxLatency" SG_ 211 DHCBtnStat 30;
BA_ "GenSigCycleTime" SG_ 211 PhoneBtnStat 100;
BA_ "GenSigCycleTimeActive" SG_ 211 PhoneBtnStat 100;
BA_ "GenSigStartValue" SG_ 211 PhoneBtnStat 3;
BA_ "GenSigMaxLatency" SG_ 211 PhoneBtnStat 30;
BA_ "GenSigCycleTime" SG_ 211 SkipPrevBtnStat 100;
BA_ "GenSigCycleTimeActive" SG_ 211 SkipPrevBtnStat 100;
BA_ "GenSigStartValue" SG_ 211 SkipPrevBtnStat 3;
BA_ "GenSigMaxLatency" SG_ 211 SkipPrevBtnStat 30;
BA_ "GenSigCycleTime" SG_ 211 ActivateBtnStat 100;
BA_ "GenSigCycleTimeActive" SG_ 211 ActivateBtnStat 100;
BA_ "GenSigStartValue" SG_ 211 ActivateBtnStat 3;
BA_ "GenSigMaxLatency" SG_ 211 ActivateBtnStat 30;
BA_ "GenSigCycleTime" SG_ 211 ResIncrBtnStat 100;
BA_ "GenSigCycleTimeActive" SG_ 211 ResIncrBtnStat 100;
BA_ "GenSigStartValue" SG_ 211 ResIncrBtnStat 3;
BA_ "GenSigMaxLatency" SG_ 211 ResIncrBtnStat 30;
BA_ "GenSigCycleTime" SG_ 211 SrcBtnStat 100;
BA_ "GenSigCycleTimeActive" SG_ 211 SrcBtnStat 100;
BA_ "GenSigStartValue" SG_ 211 SrcBtnStat 3;
BA_ "GenSigMaxLatency" SG_ 211 SrcBtnStat 30;
BA_ "GenSigCycleTime" SG_ 211 SetDecrBtnStat 100;
BA_ "GenSigCycleTimeActive" SG_ 211 SetDecrBtnStat 100;
BA_ "GenSigStartValue" SG_ 211 SetDecrBtnStat 3;
BA_ "GenSigMaxLatency" SG_ 211 SetDecrBtnStat 30;
BA_ "GenSigCycleTime" SG_ 211 MarkerInterruptButtonStatus 100;
BA_ "GenSigCycleTimeActive" SG_ 211 MarkerInterruptButtonStatus 100;
BA_ "GenSigStartValue" SG_ 211 MarkerInterruptButtonStatus 3;
BA_ "GenSigMaxLatency" SG_ 211 MarkerInterruptButtonStatus 30;
BA_ "GenSigCycleTime" SG_ 1123 DummyApplicationSignal 100;
BA_ "GenSigCycleTimeActive" SG_ 1123 DummyApplicationSignal 100;
BA_ "GenSigSendType" SG_ 2671964824 DiagUUDTRespSig_F2_98 7;
BA_ "GenSigSendType" SG_ 2671964802 DiagUUDTRespSig_F2_82 7;
BA_ "GenSigSendType" SG_ 2671964769 DiagUUDTRespSig_F2_61 7;
BA_ "GenSigSendType" SG_ 2671964736 DiagUUDTRespSig_F2_40 7;
BA_ "GenSigSendType" SG_ 2671834264 InternalTesterDiagSig_F4_98 7;
BA_ "GenSigSendType" SG_ 2671834242 InternalTesterDiagSig_F4_82 7;
BA_ "GenSigSendType" SG_ 2671834209 InternalTesterDiagSig_F4_61 7;
BA_ "GenSigSendType" SG_ 2671834176 InternalTesterDiagSig_F4_40 7;
BA_ "GenSigSendType" SG_ 2671810804 InternalTesterDiagSig_98_F4 7;
BA_ "GenSigSendType" SG_ 2671805172 InternalTesterDiagSig_82_F4 7;
BA_ "GenSigSendType" SG_ 2671796724 InternalTesterDiagSig_61_F4 7;
BA_ "GenSigSendType" SG_ 2671788276 InternalTesterDiagSig_40_F4 7;
BA_ "GenSigSendType" SG_ 1121 CCM_07P_C05_FCS 7;
BA_ "GenSigCycleTime" SG_ 1120 EngineTimer_stat_Timer2Minutes 100;
BA_ "GenSigCycleTimeActive" SG_ 1120 EngineTimer_stat_Timer2Minutes 100;
BA_ "GenSigStartValue" SG_ 1120 EngineTimer_stat_Timer2Minutes 255;
BA_ "GenSigMaxLatency" SG_ 1120 EngineTimer_stat_Timer2Minutes 500;
BA_ "GenSigCycleTime" SG_ 1120 EngineTimer_stat_Timer1Recurr 100;
BA_ "GenSigCycleTimeActive" SG_ 1120 EngineTimer_stat_Timer1Recurr 100;
BA_ "GenSigStartValue" SG_ 1120 EngineTimer_stat_Timer1Recurr 15;
BA_ "GenSigMaxLatency" SG_ 1120 EngineTimer_stat_Timer1Recurr 500;
BA_ "GenSigCycleTime" SG_ 1120 EngineTimer_stat_Timer3Minutes 100;
BA_ "GenSigCycleTimeActive" SG_ 1120 EngineTimer_stat_Timer3Minutes 100;
BA_ "GenSigStartValue" SG_ 1120 EngineTimer_stat_Timer3Minutes 255;
BA_ "GenSigMaxLatency" SG_ 1120 EngineTimer_stat_Timer3Minutes 500;
BA_ "GenSigCycleTime" SG_ 1120 EngineTimer_stat_Timer2StartDay 100;
BA_ "GenSigCycleTimeActive" SG_ 1120 EngineTimer_stat_Timer2StartDay 100;
BA_ "GenSigStartValue" SG_ 1120 EngineTimer_stat_Timer2StartDay 15;
BA_ "GenSigMaxLatency" SG_ 1120 EngineTimer_stat_Timer2StartDay 500;
BA_ "GenSigCycleTime" SG_ 1120 EngineTimer_stat_Timer3Recurr 100;
BA_ "GenSigCycleTimeActive" SG_ 1120 EngineTimer_stat_Timer3Recurr 100;
BA_ "GenSigStartValue" SG_ 1120 EngineTimer_stat_Timer3Recurr 15;
BA_ "GenSigMaxLatency" SG_ 1120 EngineTimer_stat_Timer3Recurr 500;
BA_ "GenSigCycleTime" SG_ 1120 EngineTimer_stat_Timer1Hours 100;
BA_ "GenSigCycleTimeActive" SG_ 1120 EngineTimer_stat_Timer1Hours 100;
BA_ "GenSigStartValue" SG_ 1120 EngineTimer_stat_Timer1Hours 255;
BA_ "GenSigMaxLatency" SG_ 1120 EngineTimer_stat_Timer1Hours 500;
BA_ "GenSigCycleTime" SG_ 1120 EngineTimer_stat_Timer3_Status 100;
BA_ "GenSigCycleTimeActive" SG_ 1120 EngineTimer_stat_Timer3_Status 100;
BA_ "GenSigStartValue" SG_ 1120 EngineTimer_stat_Timer3_Status 3;
BA_ "GenSigMaxLatency" SG_ 1120 EngineTimer_stat_Timer3_Status 500;
BA_ "GenSigCycleTime" SG_ 1120 EngineTimer_stat_Timer1_Status 100;
BA_ "GenSigCycleTimeActive" SG_ 1120 EngineTimer_stat_Timer1_Status 100;
BA_ "GenSigStartValue" SG_ 1120 EngineTimer_stat_Timer1_Status 3;
BA_ "GenSigMaxLatency" SG_ 1120 EngineTimer_stat_Timer1_Status 500;
BA_ "GenSigCycleTime" SG_ 1120 EngineTimer_stat_Timer1Minutes 100;
BA_ "GenSigCycleTimeActive" SG_ 1120 EngineTimer_stat_Timer1Minutes 100;
BA_ "GenSigStartValue" SG_ 1120 EngineTimer_stat_Timer1Minutes 255;
BA_ "GenSigMaxLatency" SG_ 1120 EngineTimer_stat_Timer1Minutes 500;
BA_ "GenSigCycleTime" SG_ 1120 EngineTimer_stat_Timer2Recurr 100;
BA_ "GenSigCycleTimeActive" SG_ 1120 EngineTimer_stat_Timer2Recurr 100;
BA_ "GenSigStartValue" SG_ 1120 EngineTimer_stat_Timer2Recurr 15;
BA_ "GenSigMaxLatency" SG_ 1120 EngineTimer_stat_Timer2Recurr 500;
BA_ "GenSigCycleTime" SG_ 1120 EngineTimer_stat_Timer3Hours 100;
BA_ "GenSigCycleTimeActive" SG_ 1120 EngineTimer_stat_Timer3Hours 100;
BA_ "GenSigStartValue" SG_ 1120 EngineTimer_stat_Timer3Hours 255;
BA_ "GenSigMaxLatency" SG_ 1120 EngineTimer_stat_Timer3Hours 500;
BA_ "GenSigCycleTime" SG_ 1120 EngineTimer_stat_Timer2_Status 100;
BA_ "GenSigCycleTimeActive" SG_ 1120 EngineTimer_stat_Timer2_Status 100;
BA_ "GenSigStartValue" SG_ 1120 EngineTimer_stat_Timer2_Status 3;
BA_ "GenSigMaxLatency" SG_ 1120 EngineTimer_stat_Timer2_Status 500;
BA_ "GenSigCycleTime" SG_ 1120 EngineTimer_stat_Timer2Hours 100;
BA_ "GenSigCycleTimeActive" SG_ 1120 EngineTimer_stat_Timer2Hours 100;
BA_ "GenSigStartValue" SG_ 1120 EngineTimer_stat_Timer2Hours 255;
BA_ "GenSigMaxLatency" SG_ 1120 EngineTimer_stat_Timer2Hours 500;
BA_ "GenSigCycleTime" SG_ 1120 EngineTimer_stat_Timer1StartDay 100;
BA_ "GenSigCycleTimeActive" SG_ 1120 EngineTimer_stat_Timer1StartDay 100;
BA_ "GenSigStartValue" SG_ 1120 EngineTimer_stat_Timer1StartDay 15;
BA_ "GenSigMaxLatency" SG_ 1120 EngineTimer_stat_Timer1StartDay 500;
BA_ "GenSigCycleTime" SG_ 1120 EngineTimer_stat_Timer3StartDay 100;
BA_ "GenSigCycleTimeActive" SG_ 1120 EngineTimer_stat_Timer3StartDay 100;
BA_ "GenSigStartValue" SG_ 1120 EngineTimer_stat_Timer3StartDay 15;
BA_ "GenSigMaxLatency" SG_ 1120 EngineTimer_stat_Timer3StartDay 500;
BA_ "GenSigSendType" SG_ 1168 DiagFaultStat_CCM_FailTA 3;
BA_ "GenSigStartValue" SG_ 1168 DiagFaultStat_CCM_FailTA 255;
BA_ "GenSigMaxLatency" SG_ 1168 DiagFaultStat_CCM_FailTA 1000;
BA_ "NeedsUpdateBit" SG_ 1168 DiagFaultStat_CCM_FailTA 1;
BA_ "GenSigSendType" SG_ 1168 DiagFaultStat_CCM_FailTB 3;
BA_ "GenSigStartValue" SG_ 1168 DiagFaultStat_CCM_FailTB 255;
BA_ "GenSigMaxLatency" SG_ 1168 DiagFaultStat_CCM_FailTB 1000;
BA_ "NeedsUpdateBit" SG_ 1168 DiagFaultStat_CCM_FailTB 1;
BA_ "GenSigSendType" SG_ 1168 DiagFaultStat_CCM_DtcIdA 3;
BA_ "GenSigStartValue" SG_ 1168 DiagFaultStat_CCM_DtcIdA 65535;
BA_ "GenSigMaxLatency" SG_ 1168 DiagFaultStat_CCM_DtcIdA 1000;
BA_ "NeedsUpdateBit" SG_ 1168 DiagFaultStat_CCM_DtcIdA 1;
BA_ "GenSigSendType" SG_ 1168 DiagFaultStat_CCM_DtcIdB 3;
BA_ "GenSigStartValue" SG_ 1168 DiagFaultStat_CCM_DtcIdB 65535;
BA_ "GenSigMaxLatency" SG_ 1168 DiagFaultStat_CCM_DtcIdB 1000;
BA_ "NeedsUpdateBit" SG_ 1168 DiagFaultStat_CCM_DtcIdB 1;
BA_ "GenSigSendType" SG_ 1168 DiagFaultStat_CCM_sg_UB 7;
BA_ "GenSigSendType" SG_ 1168 DiagFaultStat_CCM_EcuAdr 3;
BA_ "GenSigStartValue" SG_ 1168 DiagFaultStat_CCM_EcuAdr 255;
BA_ "GenSigMaxLatency" SG_ 1168 DiagFaultStat_CCM_EcuAdr 1000;
BA_ "NeedsUpdateBit" SG_ 1168 DiagFaultStat_CCM_EcuAdr 1;
BA_ "GenSigCycleTime" SG_ 912 PHMaintenanceService_stat 100;
BA_ "GenSigCycleTimeActive" SG_ 912 PHMaintenanceService_stat 100;
BA_ "GenSigStartValue" SG_ 912 PHMaintenanceService_stat 3;
BA_ "GenSigMaxLatency" SG_ 912 PHMaintenanceService_stat 500;
BA_ "GenSigCycleTime" SG_ 912 ParkingClimateAvailability 100;
BA_ "GenSigCycleTimeActive" SG_ 912 ParkingClimateAvailability 100;
BA_ "GenSigStartValue" SG_ 912 ParkingClimateAvailability 7;
BA_ "GenSigMaxLatency" SG_ 912 ParkingClimateAvailability 500;
BA_ "GenSigCycleTime" SG_ 912 CabTemperature_Status 100;
BA_ "GenSigCycleTimeActive" SG_ 912 CabTemperature_Status 100;
BA_ "GenSigStartValue" SG_ 912 CabTemperature_Status 8191;
BA_ "GenSigMaxLatency" SG_ 912 CabTemperature_Status 500;
BA_ "GenSigCycleTime" SG_ 656 AcCoolantPumpEngagementRequest 100;
BA_ "GenSigCycleTimeActive" SG_ 656 AcCoolantPumpEngagementRequest 100;
BA_ "GenSigStartValue" SG_ 656 AcCoolantPumpEngagementRequest 255;
BA_ "GenSigMaxLatency" SG_ 656 AcCoolantPumpEngagementRequest 100;
BA_ "GenSigCycleTime" SG_ 402 PHTimer3_stat_Minutes 100;
BA_ "GenSigCycleTimeActive" SG_ 402 PHTimer3_stat_Minutes 100;
BA_ "GenSigStartValue" SG_ 402 PHTimer3_stat_Minutes 255;
BA_ "GenSigMaxLatency" SG_ 402 PHTimer3_stat_Minutes 50;
BA_ "GenSigCycleTime" SG_ 402 PHTimer2_stat_StartDay 100;
BA_ "GenSigCycleTimeActive" SG_ 402 PHTimer2_stat_StartDay 100;
BA_ "GenSigStartValue" SG_ 402 PHTimer2_stat_StartDay 15;
BA_ "GenSigMaxLatency" SG_ 402 PHTimer2_stat_StartDay 50;
BA_ "GenSigCycleTime" SG_ 402 PHTimer2_stat_Recurrence 100;
BA_ "GenSigCycleTimeActive" SG_ 402 PHTimer2_stat_Recurrence 100;
BA_ "GenSigStartValue" SG_ 402 PHTimer2_stat_Recurrence 15;
BA_ "GenSigMaxLatency" SG_ 402 PHTimer2_stat_Recurrence 50;
BA_ "GenSigCycleTime" SG_ 402 PHTimer3_stat_Temp 100;
BA_ "GenSigCycleTimeActive" SG_ 402 PHTimer3_stat_Temp 100;
BA_ "GenSigStartValue" SG_ 402 PHTimer3_stat_Temp 31;
BA_ "GenSigMaxLatency" SG_ 402 PHTimer3_stat_Temp 50;
BA_ "GenSigCycleTime" SG_ 402 PHTimer2_stat_Temp 100;
BA_ "GenSigCycleTimeActive" SG_ 402 PHTimer2_stat_Temp 100;
BA_ "GenSigStartValue" SG_ 402 PHTimer2_stat_Temp 31;
BA_ "GenSigMaxLatency" SG_ 402 PHTimer2_stat_Temp 50;
BA_ "GenSigCycleTime" SG_ 402 PHTimer3_stat_StartDay 100;
BA_ "GenSigCycleTimeActive" SG_ 402 PHTimer3_stat_StartDay 100;
BA_ "GenSigStartValue" SG_ 402 PHTimer3_stat_StartDay 15;
BA_ "GenSigMaxLatency" SG_ 402 PHTimer3_stat_StartDay 50;
BA_ "GenSigCycleTime" SG_ 402 PHTimer2_stat_Hours 100;
BA_ "GenSigCycleTimeActive" SG_ 402 PHTimer2_stat_Hours 100;
BA_ "GenSigStartValue" SG_ 402 PHTimer2_stat_Hours 255;
BA_ "GenSigMaxLatency" SG_ 402 PHTimer2_stat_Hours 50;
BA_ "GenSigCycleTime" SG_ 402 PHTimer3_stat_Recurrence 100;
BA_ "GenSigCycleTimeActive" SG_ 402 PHTimer3_stat_Recurrence 100;
BA_ "GenSigStartValue" SG_ 402 PHTimer3_stat_Recurrence 15;
BA_ "GenSigMaxLatency" SG_ 402 PHTimer3_stat_Recurrence 50;
BA_ "GenSigCycleTime" SG_ 402 PHTimer2_stat_Minutes 100;
BA_ "GenSigCycleTimeActive" SG_ 402 PHTimer2_stat_Minutes 100;
BA_ "GenSigStartValue" SG_ 402 PHTimer2_stat_Minutes 255;
BA_ "GenSigMaxLatency" SG_ 402 PHTimer2_stat_Minutes 50;
BA_ "GenSigCycleTime" SG_ 402 PHTimer2_stat_Status 100;
BA_ "GenSigCycleTimeActive" SG_ 402 PHTimer2_stat_Status 100;
BA_ "GenSigStartValue" SG_ 402 PHTimer2_stat_Status 3;
BA_ "GenSigMaxLatency" SG_ 402 PHTimer2_stat_Status 50;
BA_ "GenSigCycleTime" SG_ 402 PHTimer3_stat_Status 100;
BA_ "GenSigCycleTimeActive" SG_ 402 PHTimer3_stat_Status 100;
BA_ "GenSigStartValue" SG_ 402 PHTimer3_stat_Status 3;
BA_ "GenSigMaxLatency" SG_ 402 PHTimer3_stat_Status 50;
BA_ "GenSigCycleTime" SG_ 402 PHTimer3_stat_Hours 100;
BA_ "GenSigCycleTimeActive" SG_ 402 PHTimer3_stat_Hours 100;
BA_ "GenSigStartValue" SG_ 402 PHTimer3_stat_Hours 255;
BA_ "GenSigMaxLatency" SG_ 402 PHTimer3_stat_Hours 50;
BA_ "GenSigCycleTime" SG_ 401 PHTimer1_stat_Recurrence 100;
BA_ "GenSigCycleTimeActive" SG_ 401 PHTimer1_stat_Recurrence 100;
BA_ "GenSigStartValue" SG_ 401 PHTimer1_stat_Recurrence 15;
BA_ "GenSigMaxLatency" SG_ 401 PHTimer1_stat_Recurrence 50;
BA_ "GenSigCycleTime" SG_ 401 PHTimer1_stat_Temp 100;
BA_ "GenSigCycleTimeActive" SG_ 401 PHTimer1_stat_Temp 100;
BA_ "GenSigStartValue" SG_ 401 PHTimer1_stat_Temp 31;
BA_ "GenSigMaxLatency" SG_ 401 PHTimer1_stat_Temp 50;
BA_ "GenSigCycleTime" SG_ 401 PHTimer1_stat_Duration 100;
BA_ "GenSigCycleTimeActive" SG_ 401 PHTimer1_stat_Duration 100;
BA_ "GenSigStartValue" SG_ 401 PHTimer1_stat_Duration 127;
BA_ "GenSigMaxLatency" SG_ 401 PHTimer1_stat_Duration 50;
BA_ "GenSigCycleTime" SG_ 401 PHTimer1_stat_Status 100;
BA_ "GenSigCycleTimeActive" SG_ 401 PHTimer1_stat_Status 100;
BA_ "GenSigStartValue" SG_ 401 PHTimer1_stat_Status 3;
BA_ "GenSigMaxLatency" SG_ 401 PHTimer1_stat_Status 50;
BA_ "GenSigCycleTime" SG_ 401 PHTimer_rqst_Hours 100;
BA_ "GenSigCycleTimeActive" SG_ 401 PHTimer_rqst_Hours 100;
BA_ "GenSigStartValue" SG_ 401 PHTimer_rqst_Hours 255;
BA_ "GenSigMaxLatency" SG_ 401 PHTimer_rqst_Hours 50;
BA_ "GenSigCycleTime" SG_ 401 PHTimer_rqst_SetAlarmOper 100;
BA_ "GenSigCycleTimeActive" SG_ 401 PHTimer_rqst_SetAlarmOper 100;
BA_ "GenSigStartValue" SG_ 401 PHTimer_rqst_SetAlarmOper 7;
BA_ "GenSigMaxLatency" SG_ 401 PHTimer_rqst_SetAlarmOper 50;
BA_ "GenSigCycleTime" SG_ 401 PHTimer_rqst_Minutes 100;
BA_ "GenSigCycleTimeActive" SG_ 401 PHTimer_rqst_Minutes 100;
BA_ "GenSigStartValue" SG_ 401 PHTimer_rqst_Minutes 255;
BA_ "GenSigMaxLatency" SG_ 401 PHTimer_rqst_Minutes 50;
BA_ "GenSigCycleTime" SG_ 401 PHTimer1_stat_Hours 100;
BA_ "GenSigCycleTimeActive" SG_ 401 PHTimer1_stat_Hours 100;
BA_ "GenSigStartValue" SG_ 401 PHTimer1_stat_Hours 255;
BA_ "GenSigMaxLatency" SG_ 401 PHTimer1_stat_Hours 50;
BA_ "GenSigCycleTime" SG_ 401 PHTimer1_stat_Minutes 100;
BA_ "GenSigCycleTimeActive" SG_ 401 PHTimer1_stat_Minutes 100;
BA_ "GenSigStartValue" SG_ 401 PHTimer1_stat_Minutes 255;
BA_ "GenSigMaxLatency" SG_ 401 PHTimer1_stat_Minutes 50;
BA_ "GenSigCycleTime" SG_ 401 PHTimer_rqst_DayOfWeekRq 100;
BA_ "GenSigCycleTimeActive" SG_ 401 PHTimer_rqst_DayOfWeekRq 100;
BA_ "GenSigStartValue" SG_ 401 PHTimer_rqst_DayOfWeekRq 15;
BA_ "GenSigMaxLatency" SG_ 401 PHTimer_rqst_DayOfWeekRq 50;
BA_ "GenSigCycleTime" SG_ 401 PHTimer1_stat_StartDay 100;
BA_ "GenSigCycleTimeActive" SG_ 401 PHTimer1_stat_StartDay 100;
BA_ "GenSigStartValue" SG_ 401 PHTimer1_stat_StartDay 15;
BA_ "GenSigMaxLatency" SG_ 401 PHTimer1_stat_StartDay 50;
BA_ "GenSigCycleTime" SG_ 400 WindscreenDefrostInd_cmd 100;
BA_ "GenSigCycleTimeActive" SG_ 400 WindscreenDefrostInd_cmd 100;
BA_ "GenSigMaxLatency" SG_ 400 WindscreenDefrostInd_cmd 50;
BA_ "GenSigCycleTime" SG_ 400 ParkingHeater_IndicationCmd 100;
BA_ "GenSigCycleTimeActive" SG_ 400 ParkingHeater_IndicationCmd 100;
BA_ "GenSigMaxLatency" SG_ 400 ParkingHeater_IndicationCmd 50;
BA_ "GenSigCycleTime" SG_ 400 AutoBlowerLevelIndication_Cmd 100;
BA_ "GenSigCycleTimeActive" SG_ 400 AutoBlowerLevelIndication_Cmd 100;
BA_ "GenSigStartValue" SG_ 400 AutoBlowerLevelIndication_Cmd 7;
BA_ "GenSigMaxLatency" SG_ 400 AutoBlowerLevelIndication_Cmd 50;
BA_ "GenSigCycleTime" SG_ 400 AC_CompressorClutchCmd 100;
BA_ "GenSigCycleTimeActive" SG_ 400 AC_CompressorClutchCmd 100;
BA_ "GenSigStartValue" SG_ 400 AC_CompressorClutchCmd 3;
BA_ "GenSigMaxLatency" SG_ 400 AC_CompressorClutchCmd 50;
BA_ "GenSigCycleTime" SG_ 400 ACdisplayIndication_Cmd 100;
BA_ "GenSigCycleTimeActive" SG_ 400 ACdisplayIndication_Cmd 100;
BA_ "GenSigStartValue" SG_ 400 ACdisplayIndication_Cmd 7;
BA_ "GenSigMaxLatency" SG_ 400 ACdisplayIndication_Cmd 50;
BA_ "GenSigCycleTime" SG_ 400 ParkingHeaterCleaning_Rqst 100;
BA_ "GenSigCycleTimeActive" SG_ 400 ParkingHeaterCleaning_Rqst 100;
BA_ "GenSigStartValue" SG_ 400 ParkingHeaterCleaning_Rqst 3;
BA_ "GenSigMaxLatency" SG_ 400 ParkingHeaterCleaning_Rqst 50;
BA_ "GenSigCycleTime" SG_ 400 TemperatureRqstIndication_cmd 100;
BA_ "GenSigCycleTimeActive" SG_ 400 TemperatureRqstIndication_cmd 100;
BA_ "GenSigStartValue" SG_ 400 TemperatureRqstIndication_cmd 31;
BA_ "GenSigMaxLatency" SG_ 400 TemperatureRqstIndication_cmd 50;
BA_ "GenSigCycleTime" SG_ 400 ParkingClimate_IndicationCmd 100;
BA_ "GenSigCycleTimeActive" SG_ 400 ParkingClimate_IndicationCmd 100;
BA_ "GenSigStartValue" SG_ 400 ParkingClimate_IndicationCmd 7;
BA_ "GenSigMaxLatency" SG_ 400 ParkingClimate_IndicationCmd 50;
BA_ "GenSigCycleTime" SG_ 400 ACmode_IndicationCmd 100;
BA_ "GenSigCycleTimeActive" SG_ 400 ACmode_IndicationCmd 100;
BA_ "GenSigMaxLatency" SG_ 400 ACmode_IndicationCmd 50;
BA_ "GenSigCycleTime" SG_ 400 AutoDefogIndication_Cmd 100;
BA_ "GenSigCycleTimeActive" SG_ 400 AutoDefogIndication_Cmd 100;
BA_ "GenSigStartValue" SG_ 400 AutoDefogIndication_Cmd 7;
BA_ "GenSigMaxLatency" SG_ 400 AutoDefogIndication_Cmd 50;
BA_ "GenSigCycleTime" SG_ 400 TempRqst_cmd 100;
BA_ "GenSigCycleTimeActive" SG_ 400 TempRqst_cmd 100;
BA_ "GenSigStartValue" SG_ 400 TempRqst_cmd 31;
BA_ "GenSigMaxLatency" SG_ 400 TempRqst_cmd 50;
BA_ "GenSigCycleTime" SG_ 400 ExtraHeating_status 100;
BA_ "GenSigCycleTimeActive" SG_ 400 ExtraHeating_status 100;
BA_ "GenSigStartValue" SG_ 400 ExtraHeating_status 3;
BA_ "GenSigMaxLatency" SG_ 400 ExtraHeating_status 50;
BA_ "GenSigCycleTime" SG_ 400 AQSmodeIndication_Cmd 100;
BA_ "GenSigCycleTimeActive" SG_ 400 AQSmodeIndication_Cmd 100;
BA_ "GenSigStartValue" SG_ 400 AQSmodeIndication_Cmd 3;
BA_ "GenSigMaxLatency" SG_ 400 AQSmodeIndication_Cmd 50;
BA_ "GenSigCycleTime" SG_ 400 CabInteriorTempVentilated_Stat 100;
BA_ "GenSigCycleTimeActive" SG_ 400 CabInteriorTempVentilated_Stat 100;
BA_ "GenSigStartValue" SG_ 400 CabInteriorTempVentilated_Stat 1023;
BA_ "GenSigMaxLatency" SG_ 400 CabInteriorTempVentilated_Stat 50;
BA_ "GenSigCycleTime" SG_ 400 AutoMode_IndicationCmd 100;
BA_ "GenSigCycleTimeActive" SG_ 400 AutoMode_IndicationCmd 100;
BA_ "GenSigMaxLatency" SG_ 400 AutoMode_IndicationCmd 50;
BA_ "GenSigCycleTime" SG_ 400 ShortStopHeater_cmd 100;
BA_ "GenSigCycleTimeActive" SG_ 400 ShortStopHeater_cmd 100;
BA_ "GenSigStartValue" SG_ 400 ShortStopHeater_cmd 3;
BA_ "GenSigMaxLatency" SG_ 400 ShortStopHeater_cmd 50;
BA_ "GenSigCycleTime" SG_ 400 ACCoolingFanSpeedRequest_CCM 100;
BA_ "GenSigCycleTimeActive" SG_ 400 ACCoolingFanSpeedRequest_CCM 100;
BA_ "GenSigStartValue" SG_ 400 ACCoolingFanSpeedRequest_CCM 65535;
BA_ "GenSigMaxLatency" SG_ 400 ACCoolingFanSpeedRequest_CCM 50;
BA_ "GenSigSendType" SG_ 1717 AnmSig_VCM_CAN05 1;
BA_ "GenSigCycleTime" SG_ 1717 AnmSig_VCM_CAN05 100;
BA_ "GenSigCycleTimeActive" SG_ 1717 AnmSig_VCM_CAN05 100;
BA_ "MmAnSignal" SG_ 1717 AnmSig_VCM_CAN05 1;
BA_ "GenSigSendType" SG_ 1718 AnmSig_SCIM_CAN05 1;
BA_ "GenSigCycleTime" SG_ 1718 AnmSig_SCIM_CAN05 100;
BA_ "GenSigCycleTimeActive" SG_ 1718 AnmSig_SCIM_CAN05 100;
BA_ "MmAnSignal" SG_ 1718 AnmSig_SCIM_CAN05 1;
BA_ "GenSigSendType" SG_ 1716 AnmSig_IC_CAN05 1;
BA_ "GenSigCycleTime" SG_ 1716 AnmSig_IC_CAN05 100;
BA_ "GenSigCycleTimeActive" SG_ 1716 AnmSig_IC_CAN05 100;
BA_ "MmAnSignal" SG_ 1716 AnmSig_IC_CAN05 1;
BA_ "GenSigSendType" SG_ 1719 AnmSig_CCM_CAN05 1;
BA_ "GenSigCycleTime" SG_ 1719 AnmSig_CCM_CAN05 100;
BA_ "GenSigCycleTimeActive" SG_ 1719 AnmSig_CCM_CAN05 100;
BA_ "MmAnSignal" SG_ 1719 AnmSig_CCM_CAN05 1;
BA_REL_ "GenSigFirstTimeoutTime" BU_SG_REL_ IC SG_ 156 LiftAxle2LowerACK 3000;
BA_REL_ "GenSigTimeoutTime" BU_SG_REL_ IC SG_ 156 LiftAxle2LowerACK 120;
BA_REL_ "GenSigFirstTimeoutTime" BU_SG_REL_ IC SG_ 156 LiftAxle2PositionStatus 3000;
BA_REL_ "GenSigTimeoutTime" BU_SG_REL_ IC SG_ 156 LiftAxle2PositionStatus 120;
BA_REL_ "GenSigFirstTimeoutTime" BU_SG_REL_ IC SG_ 156 LiftAxle2LiftFuncSelected 3000;
BA_REL_ "GenSigTimeoutTime" BU_SG_REL_ IC SG_ 156 LiftAxle2LiftFuncSelected 120;
BA_REL_ "GenSigFirstTimeoutTime" BU_SG_REL_ CCM SG_ 156 PassengerDoorAjar_stat 3000;
BA_REL_ "GenSigTimeoutTime" BU_SG_REL_ CCM SG_ 156 PassengerDoorAjar_stat 120;
BA_REL_ "GenSigFirstTimeoutTime" BU_SG_REL_ IC SG_ 156 AirFlowSelectionDownBtn_stat 3000;
BA_REL_ "GenSigTimeoutTime" BU_SG_REL_ IC SG_ 156 AirFlowSelectionDownBtn_stat 120;
BA_REL_ "GenSigFirstTimeoutTime" BU_SG_REL_ IC SG_ 156 LevelControlInformation 3000;
BA_REL_ "GenSigTimeoutTime" BU_SG_REL_ IC SG_ 156 LevelControlInformation 120;
BA_REL_ "GenSigFirstTimeoutTime" BU_SG_REL_ IC SG_ 156 LiftAxle1LowerACK 3000;
BA_REL_ "GenSigTimeoutTime" BU_SG_REL_ IC SG_ 156 LiftAxle1LowerACK 120;
BA_REL_ "GenSigFirstTimeoutTime" BU_SG_REL_ IC SG_ 156 WiperModeStatus 3000;
BA_REL_ "GenSigTimeoutTime" BU_SG_REL_ IC SG_ 156 WiperModeStatus 120;
BA_REL_ "GenSigFirstTimeoutTime" BU_SG_REL_ CCM SG_ 156 WiperModeStatus 3000;
BA_REL_ "GenSigTimeoutTime" BU_SG_REL_ CCM SG_ 156 WiperModeStatus 120;
BA_REL_ "GenSigFirstTimeoutTime" BU_SG_REL_ CCM SG_ 156 Washing_HMI_rqst 3000;
BA_REL_ "GenSigTimeoutTime" BU_SG_REL_ CCM SG_ 156 Washing_HMI_rqst 120;
BA_REL_ "GenSigFirstTimeoutTime" BU_SG_REL_ IC SG_ 156 LiftAxle2AutoLiftSelected 3000;
BA_REL_ "GenSigTimeoutTime" BU_SG_REL_ IC SG_ 156 LiftAxle2AutoLiftSelected 120;
BA_REL_ "GenSigFirstTimeoutTime" BU_SG_REL_ CCM SG_ 156 ReverseGearEngaged 3000;
BA_REL_ "GenSigTimeoutTime" BU_SG_REL_ CCM SG_ 156 ReverseGearEngaged 120;
BA_REL_ "GenSigFirstTimeoutTime" BU_SG_REL_ IC SG_ 156 LiftAxle1PositionStatus 3000;
BA_REL_ "GenSigTimeoutTime" BU_SG_REL_ IC SG_ 156 LiftAxle1PositionStatus 120;
BA_REL_ "GenSigFirstTimeoutTime" BU_SG_REL_ IC SG_ 156 ACC_Status 3000;
BA_REL_ "GenSigTimeoutTime" BU_SG_REL_ IC SG_ 156 ACC_Status 120;
BA_REL_ "GenSigFirstTimeoutTime" BU_SG_REL_ IC SG_ 156 LECM_CabClim_MaxDef_GuiReq 3000;
BA_REL_ "GenSigTimeoutTime" BU_SG_REL_ IC SG_ 156 LECM_CabClim_MaxDef_GuiReq 120;
BA_REL_ "GenSigFirstTimeoutTime" BU_SG_REL_ IC SG_ 156 RegenerationSwitchStatus 3000;
BA_REL_ "GenSigTimeoutTime" BU_SG_REL_ IC SG_ 156 RegenerationSwitchStatus 120;
BA_REL_ "GenSigFirstTimeoutTime" BU_SG_REL_ CCM SG_ 156 DSWindowPosition 3000;
BA_REL_ "GenSigTimeoutTime" BU_SG_REL_ CCM SG_ 156 DSWindowPosition 120;
BA_REL_ "GenSigFirstTimeoutTime" BU_SG_REL_ IC SG_ 156 WindscreenDefrost_ButtonStatus 3000;
BA_REL_ "GenSigTimeoutTime" BU_SG_REL_ IC SG_ 156 WindscreenDefrost_ButtonStatus 120;
BA_REL_ "GenSigFirstTimeoutTime" BU_SG_REL_ IC SG_ 156 GearSplit_Status 3000;
BA_REL_ "GenSigTimeoutTime" BU_SG_REL_ IC SG_ 156 GearSplit_Status 120;
BA_REL_ "GenSigFirstTimeoutTime" BU_SG_REL_ IC SG_ 156 KeyPosition 3000;
BA_REL_ "GenSigTimeoutTime" BU_SG_REL_ IC SG_ 156 KeyPosition 120;
BA_REL_ "GenSigFirstTimeoutTime" BU_SG_REL_ IC SG_ 156 LiftAxle1LiftFuncSelected 3000;
BA_REL_ "GenSigTimeoutTime" BU_SG_REL_ IC SG_ 156 LiftAxle1LiftFuncSelected 120;
BA_REL_ "GenSigFirstTimeoutTime" BU_SG_REL_ IC SG_ 156 LiftAxle2UpRequestACK 3000;
BA_REL_ "GenSigTimeoutTime" BU_SG_REL_ IC SG_ 156 LiftAxle2UpRequestACK 120;
BA_REL_ "GenSigFirstTimeoutTime" BU_SG_REL_ IC SG_ 156 PreTrip_ButtonStat3 3000;
BA_REL_ "GenSigTimeoutTime" BU_SG_REL_ IC SG_ 156 PreTrip_ButtonStat3 120;
BA_REL_ "GenSigFirstTimeoutTime" BU_SG_REL_ IC SG_ 156 LiftAxle1UpRequestACK 3000;
BA_REL_ "GenSigTimeoutTime" BU_SG_REL_ IC SG_ 156 LiftAxle1UpRequestACK 120;
BA_REL_ "GenSigFirstTimeoutTime" BU_SG_REL_ CCM SG_ 154 EngineSpeed 3000;
BA_REL_ "GenSigTimeoutTime" BU_SG_REL_ CCM SG_ 154 EngineSpeed 120;
BA_REL_ "GenSigFirstTimeoutTime" BU_SG_REL_ IC SG_ 154 SteeringWheelAngle 3000;
BA_REL_ "GenSigTimeoutTime" BU_SG_REL_ IC SG_ 154 SteeringWheelAngle 120;
BA_REL_ "GenSigFirstTimeoutTime" BU_SG_REL_ IC SG_ 154 LateralAcceleration 3000;
BA_REL_ "GenSigTimeoutTime" BU_SG_REL_ IC SG_ 154 LateralAcceleration 120;
BA_REL_ "GenSigFirstTimeoutTime" BU_SG_REL_ IC SG_ 138 AcceleratorPedalLowIdleSwitch 3000;
BA_REL_ "GenSigTimeoutTime" BU_SG_REL_ IC SG_ 138 AcceleratorPedalLowIdleSwitch 100;
BA_REL_ "GenSigFirstTimeoutTime" BU_SG_REL_ SCIM SG_ 138 VehicleMode 3000;
BA_REL_ "GenSigTimeoutTime" BU_SG_REL_ SCIM SG_ 138 VehicleMode 100;
BA_REL_ "GenSigFirstTimeoutTime" BU_SG_REL_ IC SG_ 138 VehicleMode 3000;
BA_REL_ "GenSigTimeoutTime" BU_SG_REL_ IC SG_ 138 VehicleMode 100;
BA_REL_ "GenSigFirstTimeoutTime" BU_SG_REL_ CCM SG_ 138 VehicleMode 3000;
BA_REL_ "GenSigTimeoutTime" BU_SG_REL_ CCM SG_ 138 VehicleMode 100;
BA_REL_ "GenSigFirstTimeoutTime" BU_SG_REL_ IC SG_ 138 AcceleratorPedalPosition1 3000;
BA_REL_ "GenSigTimeoutTime" BU_SG_REL_ IC SG_ 138 AcceleratorPedalPosition1 100;
BA_REL_ "GenSigFirstTimeoutTime" BU_SG_REL_ IC SG_ 138 AcceleratorPedalQuality 3000;
BA_REL_ "GenSigTimeoutTime" BU_SG_REL_ IC SG_ 138 AcceleratorPedalQuality 100;
BA_REL_ "GenSigFirstTimeoutTime" BU_SG_REL_ IC SG_ 895 DriverCrank_rqst 3000;
BA_REL_ "GenSigTimeoutTime" BU_SG_REL_ IC SG_ 895 DriverCrank_rqst 300;
BA_REL_ "GenSigFirstTimeoutTime" BU_SG_REL_ IC SG_ 895 EngineStartControlStatus 3000;
BA_REL_ "GenSigTimeoutTime" BU_SG_REL_ IC SG_ 895 EngineStartControlStatus 300;
BA_REL_ "GenSigFirstTimeoutTime" BU_SG_REL_ IC SG_ 895 WheelBasedVehicleSpd_Value 3000;
BA_REL_ "GenSigTimeoutTime" BU_SG_REL_ IC SG_ 895 WheelBasedVehicleSpd_Value 300;
BA_REL_ "GenSigFirstTimeoutTime" BU_SG_REL_ IC SG_ 895 WheelBasedVehicleSpd_CRC 3000;
BA_REL_ "GenSigTimeoutTime" BU_SG_REL_ IC SG_ 895 WheelBasedVehicleSpd_CRC 300;
BA_REL_ "GenSigFirstTimeoutTime" BU_SG_REL_ IC SG_ 895 CabTiltLockStatus 3000;
BA_REL_ "GenSigTimeoutTime" BU_SG_REL_ IC SG_ 895 CabTiltLockStatus 300;
BA_REL_ "GenSigFirstTimeoutTime" BU_SG_REL_ IC SG_ 895 WheelBasedVehicleSpd_SqC 3000;
BA_REL_ "GenSigTimeoutTime" BU_SG_REL_ IC SG_ 895 WheelBasedVehicleSpd_SqC 300;
BA_REL_ "GenSigFirstTimeoutTime" BU_SG_REL_ SCIM SG_ 895 CabTiltEnableStatus 3000;
BA_REL_ "GenSigTimeoutTime" BU_SG_REL_ SCIM SG_ 895 CabTiltEnableStatus 300;
BA_REL_ "GenSigFirstTimeoutTime" BU_SG_REL_ VCM SG_ 1104 CabTilt_rqst 3000;
BA_REL_ "GenSigTimeoutTime" BU_SG_REL_ VCM SG_ 1104 CabTilt_rqst 600;
BA_REL_ "GenSigFirstTimeoutTime" BU_SG_REL_ VCM SG_ 432 DriverSeatBeltSwitch 3000;
BA_REL_ "GenSigTimeoutTime" BU_SG_REL_ VCM SG_ 432 DriverSeatBeltSwitch 300;
BA_REL_ "GenSigFirstTimeoutTime" BU_SG_REL_ VCM SG_ 432 FrontLidAjar_Stat 3000;
BA_REL_ "GenSigTimeoutTime" BU_SG_REL_ VCM SG_ 432 FrontLidAjar_Stat 300;
BA_REL_ "GenSigFirstTimeoutTime" BU_SG_REL_ VCM SG_ 432 LevelingThumbwheel_stat 3000;
BA_REL_ "GenSigTimeoutTime" BU_SG_REL_ VCM SG_ 432 LevelingThumbwheel_stat 300;
BA_REL_ "GenSigFirstTimeoutTime" BU_SG_REL_ VCM SG_ 179 LightMode_Status_Ctr_1 3000;
BA_REL_ "GenSigTimeoutTime" BU_SG_REL_ VCM SG_ 179 LightMode_Status_Ctr_1 120;
BA_REL_ "GenSigFirstTimeoutTime" BU_SG_REL_ VCM SG_ 179 ReverseWarning_rqst 3000;
BA_REL_ "GenSigTimeoutTime" BU_SG_REL_ VCM SG_ 179 ReverseWarning_rqst 120;
BA_REL_ "GenSigFirstTimeoutTime" BU_SG_REL_ VCM SG_ 179 FogLightFront_ButtonStatus_1 3000;
BA_REL_ "GenSigTimeoutTime" BU_SG_REL_ VCM SG_ 179 FogLightFront_ButtonStatus_1 120;
BA_REL_ "GenSigFirstTimeoutTime" BU_SG_REL_ VCM SG_ 179 FogLightRear_ButtonStatus_1 3000;
BA_REL_ "GenSigTimeoutTime" BU_SG_REL_ VCM SG_ 179 FogLightRear_ButtonStatus_1 120;
BA_REL_ "GenSigFirstTimeoutTime" BU_SG_REL_ VCM SG_ 1184 FasDampingSetting_rqst 24000;
BA_REL_ "GenSigTimeoutTime" BU_SG_REL_ VCM SG_ 1184 FasDampingSetting_rqst 6000;
BA_REL_ "GenSigFirstTimeoutTime" BU_SG_REL_ VCM SG_ 1184 FasPersonalSettingsButton_rqst 24000;
BA_REL_ "GenSigTimeoutTime" BU_SG_REL_ VCM SG_ 1184 FasPersonalSettingsButton_rqst 6000;
BA_REL_ "GenSigFirstTimeoutTime" BU_SG_REL_ VCM SG_ 1184 FasStiffnessCurveSetting_rqst 24000;
BA_REL_ "GenSigTimeoutTime" BU_SG_REL_ VCM SG_ 1184 FasStiffnessCurveSetting_rqst 6000;
BA_REL_ "GenSigFirstTimeoutTime" BU_SG_REL_ VCM SG_ 1184 FasDriver_rqst 24000;
BA_REL_ "GenSigTimeoutTime" BU_SG_REL_ VCM SG_ 1184 FasDriver_rqst 6000;
BA_REL_ "GenSigFirstTimeoutTime" BU_SG_REL_ VCM SG_ 1184 FasUsrDefinedStorage_rqst 24000;
BA_REL_ "GenSigTimeoutTime" BU_SG_REL_ VCM SG_ 1184 FasUsrDefinedStorage_rqst 6000;
BA_REL_ "GenSigFirstTimeoutTime" BU_SG_REL_ VCM SG_ 1184 FasStiffStraightSetting_rqst 24000;
BA_REL_ "GenSigTimeoutTime" BU_SG_REL_ VCM SG_ 1184 FasStiffStraightSetting_rqst 6000;
BA_REL_ "GenSigFirstTimeoutTime" BU_SG_REL_ VCM SG_ 1184 FasLowSpeedReturnSetting_rqst 24000;
BA_REL_ "GenSigTimeoutTime" BU_SG_REL_ VCM SG_ 1184 FasLowSpeedReturnSetting_rqst 6000;
BA_REL_ "GenSigFirstTimeoutTime" BU_SG_REL_ VCM SG_ 1184 FasManualOffsetSetting_rqst 24000;
BA_REL_ "GenSigTimeoutTime" BU_SG_REL_ VCM SG_ 1184 FasManualOffsetSetting_rqst 6000;
BA_REL_ "GenSigFirstTimeoutTime" BU_SG_REL_ VCM SG_ 932 DPF_ManualRegenerateRequest 12000;
BA_REL_ "GenSigTimeoutTime" BU_SG_REL_ VCM SG_ 932 DPF_ManualRegenerateRequest 3000;
BA_REL_ "GenSigFirstTimeoutTime" BU_SG_REL_ VCM SG_ 932 DPF_ManualRegenerateInhibit 12000;
BA_REL_ "GenSigTimeoutTime" BU_SG_REL_ VCM SG_ 932 DPF_ManualRegenerateInhibit 3000;
BA_REL_ "GenSigFirstTimeoutTime" BU_SG_REL_ VCM SG_ 932 DPF_ManualRegenerateTimeReq 12000;
BA_REL_ "GenSigTimeoutTime" BU_SG_REL_ VCM SG_ 932 DPF_ManualRegenerateTimeReq 3000;
BA_REL_ "GenSigFirstTimeoutTime" BU_SG_REL_ VCM SG_ 930 OBDRelDTC_IC_DrvngCycleB 12000;
BA_REL_ "GenSigTimeoutTime" BU_SG_REL_ VCM SG_ 930 OBDRelDTC_IC_DrvngCycleB 3000;
BA_REL_ "GenSigFirstTimeoutTime" BU_SG_REL_ VCM SG_ 930 OBDRelDTC_IC_EvalResultA 12000;
BA_REL_ "GenSigTimeoutTime" BU_SG_REL_ VCM SG_ 930 OBDRelDTC_IC_EvalResultA 3000;
BA_REL_ "GenSigFirstTimeoutTime" BU_SG_REL_ VCM SG_ 930 OBDRelDTC_IC_EvalResultB 12000;
BA_REL_ "GenSigTimeoutTime" BU_SG_REL_ VCM SG_ 930 OBDRelDTC_IC_EvalResultB 3000;
BA_REL_ "GenSigFirstTimeoutTime" BU_SG_REL_ VCM SG_ 930 OBDRelDTC_IC_EvalStatA 12000;
BA_REL_ "GenSigTimeoutTime" BU_SG_REL_ VCM SG_ 930 OBDRelDTC_IC_EvalStatA 3000;
BA_REL_ "GenSigFirstTimeoutTime" BU_SG_REL_ VCM SG_ 930 OBDRelDTC_IC_DtcIdB 12000;
BA_REL_ "GenSigTimeoutTime" BU_SG_REL_ VCM SG_ 930 OBDRelDTC_IC_DtcIdB 3000;
BA_REL_ "GenSigFirstTimeoutTime" BU_SG_REL_ VCM SG_ 930 OBDRelDTC_IC_DrvngCycleA 12000;
BA_REL_ "GenSigTimeoutTime" BU_SG_REL_ VCM SG_ 930 OBDRelDTC_IC_DrvngCycleA 3000;
BA_REL_ "GenSigFirstTimeoutTime" BU_SG_REL_ VCM SG_ 930 OBDRelDTC_IC_FailTB 12000;
BA_REL_ "GenSigTimeoutTime" BU_SG_REL_ VCM SG_ 930 OBDRelDTC_IC_FailTB 3000;
BA_REL_ "GenSigFirstTimeoutTime" BU_SG_REL_ VCM SG_ 930 OBDRelDTC_IC_DtcIdA 12000;
BA_REL_ "GenSigTimeoutTime" BU_SG_REL_ VCM SG_ 930 OBDRelDTC_IC_DtcIdA 3000;
BA_REL_ "GenSigFirstTimeoutTime" BU_SG_REL_ VCM SG_ 930 OBDRelDTC_IC_FailTA 12000;
BA_REL_ "GenSigTimeoutTime" BU_SG_REL_ VCM SG_ 930 OBDRelDTC_IC_FailTA 3000;
BA_REL_ "GenSigFirstTimeoutTime" BU_SG_REL_ VCM SG_ 930 OBDRelDTC_IC_EvalStatB 12000;
BA_REL_ "GenSigTimeoutTime" BU_SG_REL_ VCM SG_ 930 OBDRelDTC_IC_EvalStatB 3000;
BA_REL_ "GenSigFirstTimeoutTime" BU_SG_REL_ VCM SG_ 928 Set_LG5CutoffValue 12000;
BA_REL_ "GenSigTimeoutTime" BU_SG_REL_ VCM SG_ 928 Set_LG5CutoffValue 3000;
BA_REL_ "GenSigFirstTimeoutTime" BU_SG_REL_ VCM SG_ 928 Set_LG3CutoffValue 12000;
BA_REL_ "GenSigTimeoutTime" BU_SG_REL_ VCM SG_ 928 Set_LG3CutoffValue 3000;
BA_REL_ "GenSigFirstTimeoutTime" BU_SG_REL_ VCM SG_ 928 Set_LG1CutoffValue 12000;
BA_REL_ "GenSigTimeoutTime" BU_SG_REL_ VCM SG_ 928 Set_LG1CutoffValue 3000;
BA_REL_ "GenSigFirstTimeoutTime" BU_SG_REL_ VCM SG_ 928 Set_LG2CutoffValue 12000;
BA_REL_ "GenSigTimeoutTime" BU_SG_REL_ VCM SG_ 928 Set_LG2CutoffValue 3000;
BA_REL_ "GenSigFirstTimeoutTime" BU_SG_REL_ VCM SG_ 928 Set_LG4CutoffValue 12000;
BA_REL_ "GenSigTimeoutTime" BU_SG_REL_ VCM SG_ 928 Set_LG4CutoffValue 3000;
BA_REL_ "GenSigFirstTimeoutTime" BU_SG_REL_ VCM SG_ 928 Set_EnergySetting 12000;
BA_REL_ "GenSigTimeoutTime" BU_SG_REL_ VCM SG_ 928 Set_EnergySetting 3000;
BA_REL_ "GenSigFirstTimeoutTime" BU_SG_REL_ VCM SG_ 928 Set_LG6CutoffValue 12000;
BA_REL_ "GenSigTimeoutTime" BU_SG_REL_ VCM SG_ 928 Set_LG6CutoffValue 3000;
BA_REL_ "GenSigFirstTimeoutTime" BU_SG_REL_ VCM SG_ 784 SpeedAdaptEnableRqst_SpeedLimit 4800;
BA_REL_ "GenSigTimeoutTime" BU_SG_REL_ VCM SG_ 784 SpeedAdaptEnableRqst_SpeedLimit 1200;
BA_REL_ "GenSigFirstTimeoutTime" BU_SG_REL_ VCM SG_ 784 SpeedAdaptEnableRqst_SlowTraffic 4800;
BA_REL_ "GenSigTimeoutTime" BU_SG_REL_ VCM SG_ 784 SpeedAdaptEnableRqst_SlowTraffic 1200;
BA_REL_ "GenSigFirstTimeoutTime" BU_SG_REL_ VCM SG_ 784 BattEnergySetLevel_input 4800;
BA_REL_ "GenSigTimeoutTime" BU_SG_REL_ VCM SG_ 784 BattEnergySetLevel_input 1200;
BA_REL_ "GenSigFirstTimeoutTime" BU_SG_REL_ VCM SG_ 784 SpeedAdaptationLevelRqst 4800;
BA_REL_ "GenSigTimeoutTime" BU_SG_REL_ VCM SG_ 784 SpeedAdaptationLevelRqst 1200;
BA_REL_ "GenSigFirstTimeoutTime" BU_SG_REL_ VCM SG_ 784 SpeedAdaptEnableRqst_Curve 4800;
BA_REL_ "GenSigTimeoutTime" BU_SG_REL_ VCM SG_ 784 SpeedAdaptEnableRqst_Curve 1200;
BA_REL_ "GenSigFirstTimeoutTime" BU_SG_REL_ CCM SG_ 784 ExtraHeating_rqst 4800;
BA_REL_ "GenSigTimeoutTime" BU_SG_REL_ CCM SG_ 784 ExtraHeating_rqst 1200;
BA_REL_ "GenSigFirstTimeoutTime" BU_SG_REL_ VCM SG_ 784 ExtraHeating_rqst 4800;
BA_REL_ "GenSigTimeoutTime" BU_SG_REL_ VCM SG_ 784 ExtraHeating_rqst 1200;
BA_REL_ "GenSigFirstTimeoutTime" BU_SG_REL_ VCM SG_ 672 ParkingHeaterCleaning_cmd 3000;
BA_REL_ "GenSigTimeoutTime" BU_SG_REL_ VCM SG_ 672 ParkingHeaterCleaning_cmd 600;
BA_REL_ "GenSigFirstTimeoutTime" BU_SG_REL_ CCM SG_ 672 ParkingHeaterCleaning_cmd 3000;
BA_REL_ "GenSigTimeoutTime" BU_SG_REL_ CCM SG_ 672 ParkingHeaterCleaning_cmd 600;
BA_REL_ "GenSigFirstTimeoutTime" BU_SG_REL_ CCM SG_ 672 DriverMemory_rqst 3000;
BA_REL_ "GenSigTimeoutTime" BU_SG_REL_ CCM SG_ 672 DriverMemory_rqst 600;
BA_REL_ "GenSigFirstTimeoutTime" BU_SG_REL_ VCM SG_ 672 DriverMemory_rqst 3000;
BA_REL_ "GenSigTimeoutTime" BU_SG_REL_ VCM SG_ 672 DriverMemory_rqst 600;
BA_REL_ "GenSigFirstTimeoutTime" BU_SG_REL_ VCM SG_ 672 FirstAxleLowerPrioRequested 3000;
BA_REL_ "GenSigTimeoutTime" BU_SG_REL_ VCM SG_ 672 FirstAxleLowerPrioRequested 600;
BA_REL_ "GenSigFirstTimeoutTime" BU_SG_REL_ VCM SG_ 672 AutoShutOffAnswerInput 3000;
BA_REL_ "GenSigTimeoutTime" BU_SG_REL_ VCM SG_ 672 AutoShutOffAnswerInput 600;
BA_REL_ "GenSigFirstTimeoutTime" BU_SG_REL_ VCM SG_ 672 ManualEngineCoolingDev_Ind 3000;
BA_REL_ "GenSigTimeoutTime" BU_SG_REL_ VCM SG_ 672 ManualEngineCoolingDev_Ind 600;
BA_REL_ "GenSigFirstTimeoutTime" BU_SG_REL_ VCM SG_ 672 TemporaryRSLDeviceIndication 3000;
BA_REL_ "GenSigTimeoutTime" BU_SG_REL_ VCM SG_ 672 TemporaryRSLDeviceIndication 600;
BA_REL_ "GenSigFirstTimeoutTime" BU_SG_REL_ VCM SG_ 672 ESC_ButtonIndication2 3000;
BA_REL_ "GenSigTimeoutTime" BU_SG_REL_ VCM SG_ 672 ESC_ButtonIndication2 600;
BA_REL_ "GenSigFirstTimeoutTime" BU_SG_REL_ VCM SG_ 672 WaterInFuelDrainRequest 3000;
BA_REL_ "GenSigTimeoutTime" BU_SG_REL_ VCM SG_ 672 WaterInFuelDrainRequest 600;
BA_REL_ "GenSigFirstTimeoutTime" BU_SG_REL_ VCM SG_ 672 PreTripIndication3 3000;
BA_REL_ "GenSigTimeoutTime" BU_SG_REL_ VCM SG_ 672 PreTripIndication3 600;
BA_REL_ "GenSigFirstTimeoutTime" BU_SG_REL_ VCM SG_ 672 ESCOff_DeviceIndication 3000;
BA_REL_ "GenSigTimeoutTime" BU_SG_REL_ VCM SG_ 672 ESCOff_DeviceIndication 600;
BA_REL_ "GenSigFirstTimeoutTime" BU_SG_REL_ VCM SG_ 672 AWBEnableRequest 3000;
BA_REL_ "GenSigTimeoutTime" BU_SG_REL_ VCM SG_ 672 AWBEnableRequest 600;
BA_REL_ "GenSigFirstTimeoutTime" BU_SG_REL_ VCM SG_ 672 LampCheck_rqst 3000;
BA_REL_ "GenSigTimeoutTime" BU_SG_REL_ VCM SG_ 672 LampCheck_rqst 600;
BA_REL_ "GenSigFirstTimeoutTime" BU_SG_REL_ VCM SG_ 416 SSReq_Repetition 3000;
BA_REL_ "GenSigTimeoutTime" BU_SG_REL_ VCM SG_ 416 SSReq_Repetition 300;
BA_REL_ "GenSigFirstTimeoutTime" BU_SG_REL_ VCM SG_ 416 SSReq_Balance 3000;
BA_REL_ "GenSigTimeoutTime" BU_SG_REL_ VCM SG_ 416 SSReq_Balance 300;
BA_REL_ "GenSigFirstTimeoutTime" BU_SG_REL_ VCM SG_ 416 SSReq_Time 3000;
BA_REL_ "GenSigTimeoutTime" BU_SG_REL_ VCM SG_ 416 SSReq_Time 300;
BA_REL_ "GenSigFirstTimeoutTime" BU_SG_REL_ VCM SG_ 416 PhoneButtonIndication_cmd 3000;
BA_REL_ "GenSigTimeoutTime" BU_SG_REL_ VCM SG_ 416 PhoneButtonIndication_cmd 300;
BA_REL_ "GenSigFirstTimeoutTime" BU_SG_REL_ VCM SG_ 416 FuncIndIlluminationLevel 3000;
BA_REL_ "GenSigTimeoutTime" BU_SG_REL_ VCM SG_ 416 FuncIndIlluminationLevel 300;
BA_REL_ "GenSigFirstTimeoutTime" BU_SG_REL_ VCM SG_ 416 BacklightCmd 3000;
BA_REL_ "GenSigTimeoutTime" BU_SG_REL_ VCM SG_ 416 BacklightCmd 300;
BA_REL_ "GenSigFirstTimeoutTime" BU_SG_REL_ VCM SG_ 416 SSReq_Id 3000;
BA_REL_ "GenSigTimeoutTime" BU_SG_REL_ VCM SG_ 416 SSReq_Id 300;
BA_REL_ "GenSigFirstTimeoutTime" BU_SG_REL_ VCM SG_ 416 SSReq_Mixed 3000;
BA_REL_ "GenSigTimeoutTime" BU_SG_REL_ VCM SG_ 416 SSReq_Mixed 300;
BA_REL_ "GenSigFirstTimeoutTime" BU_SG_REL_ VCM SG_ 416 BunkBacklightCmd 3000;
BA_REL_ "GenSigTimeoutTime" BU_SG_REL_ VCM SG_ 416 BunkBacklightCmd 300;
BA_REL_ "GenSigFirstTimeoutTime" BU_SG_REL_ VCM SG_ 416 SSReq_State 3000;
BA_REL_ "GenSigTimeoutTime" BU_SG_REL_ VCM SG_ 416 SSReq_State 300;
BA_REL_ "GenSigFirstTimeoutTime" BU_SG_REL_ VCM SG_ 416 SSReq_Volume 3000;
BA_REL_ "GenSigTimeoutTime" BU_SG_REL_ VCM SG_ 416 SSReq_Volume 300;
BA_REL_ "GenSigFirstTimeoutTime" BU_SG_REL_ VCM SG_ 211 TimeGapBtnStat 3000;
BA_REL_ "GenSigTimeoutTime" BU_SG_REL_ VCM SG_ 211 TimeGapBtnStat 120;
BA_REL_ "GenSigFirstTimeoutTime" BU_SG_REL_ VCM SG_ 211 ATC_ButtonIndication 3000;
BA_REL_ "GenSigTimeoutTime" BU_SG_REL_ VCM SG_ 211 ATC_ButtonIndication 120;
BA_REL_ "GenSigFirstTimeoutTime" BU_SG_REL_ VCM SG_ 211 PauseOffBtnStat 3000;
BA_REL_ "GenSigTimeoutTime" BU_SG_REL_ VCM SG_ 211 PauseOffBtnStat 120;
BA_REL_ "GenSigFirstTimeoutTime" BU_SG_REL_ VCM SG_ 211 ABS_ButtonIndication 3000;
BA_REL_ "GenSigTimeoutTime" BU_SG_REL_ VCM SG_ 211 ABS_ButtonIndication 120;
BA_REL_ "GenSigFirstTimeoutTime" BU_SG_REL_ VCM SG_ 211 SW_HeadlightInterrupt_Stat 3000;
BA_REL_ "GenSigTimeoutTime" BU_SG_REL_ VCM SG_ 211 SW_HeadlightInterrupt_Stat 120;
BA_REL_ "GenSigFirstTimeoutTime" BU_SG_REL_ VCM SG_ 211 PBAlertActiveStatus 3000;
BA_REL_ "GenSigTimeoutTime" BU_SG_REL_ VCM SG_ 211 PBAlertActiveStatus 120;
BA_REL_ "GenSigFirstTimeoutTime" BU_SG_REL_ VCM SG_ 211 EcoRollEnableRequest 3000;
BA_REL_ "GenSigTimeoutTime" BU_SG_REL_ VCM SG_ 211 EcoRollEnableRequest 120;
BA_REL_ "GenSigFirstTimeoutTime" BU_SG_REL_ VCM SG_ 211 EcoSettingsBtnStat 3000;
BA_REL_ "GenSigTimeoutTime" BU_SG_REL_ VCM SG_ 211 EcoSettingsBtnStat 120;
BA_REL_ "GenSigFirstTimeoutTime" BU_SG_REL_ VCM SG_ 211 SkipNextBtnStat 3000;
BA_REL_ "GenSigTimeoutTime" BU_SG_REL_ VCM SG_ 211 SkipNextBtnStat 120;
BA_REL_ "GenSigFirstTimeoutTime" BU_SG_REL_ VCM SG_ 211 TCS_ButtonIndication 3000;
BA_REL_ "GenSigTimeoutTime" BU_SG_REL_ VCM SG_ 211 TCS_ButtonIndication 120;
BA_REL_ "GenSigFirstTimeoutTime" BU_SG_REL_ VCM SG_ 211 DHCBtnStat 3000;
BA_REL_ "GenSigTimeoutTime" BU_SG_REL_ VCM SG_ 211 DHCBtnStat 120;
BA_REL_ "GenSigFirstTimeoutTime" BU_SG_REL_ VCM SG_ 211 PhoneBtnStat 3000;
BA_REL_ "GenSigTimeoutTime" BU_SG_REL_ VCM SG_ 211 PhoneBtnStat 120;
BA_REL_ "GenSigFirstTimeoutTime" BU_SG_REL_ VCM SG_ 211 SkipPrevBtnStat 3000;
BA_REL_ "GenSigTimeoutTime" BU_SG_REL_ VCM SG_ 211 SkipPrevBtnStat 120;
BA_REL_ "GenSigFirstTimeoutTime" BU_SG_REL_ VCM SG_ 211 ActivateBtnStat 3000;
BA_REL_ "GenSigTimeoutTime" BU_SG_REL_ VCM SG_ 211 ActivateBtnStat 120;
BA_REL_ "GenSigFirstTimeoutTime" BU_SG_REL_ VCM SG_ 211 ResIncrBtnStat 3000;
BA_REL_ "GenSigTimeoutTime" BU_SG_REL_ VCM SG_ 211 ResIncrBtnStat 120;
BA_REL_ "GenSigFirstTimeoutTime" BU_SG_REL_ VCM SG_ 211 SrcBtnStat 3000;
BA_REL_ "GenSigTimeoutTime" BU_SG_REL_ VCM SG_ 211 SrcBtnStat 120;
BA_REL_ "GenSigFirstTimeoutTime" BU_SG_REL_ VCM SG_ 211 SetDecrBtnStat 3000;
BA_REL_ "GenSigTimeoutTime" BU_SG_REL_ VCM SG_ 211 SetDecrBtnStat 120;
BA_REL_ "GenSigFirstTimeoutTime" BU_SG_REL_ VCM SG_ 211 MarkerInterruptButtonStatus 3000;
BA_REL_ "GenSigTimeoutTime" BU_SG_REL_ VCM SG_ 211 MarkerInterruptButtonStatus 120;
BA_REL_ "GenSigFirstTimeoutTime" BU_SG_REL_ VCM SG_ 1120 EngineTimer_stat_Timer2Minutes 12000;
BA_REL_ "GenSigTimeoutTime" BU_SG_REL_ VCM SG_ 1120 EngineTimer_stat_Timer2Minutes 3000;
BA_REL_ "GenSigFirstTimeoutTime" BU_SG_REL_ VCM SG_ 1120 EngineTimer_stat_Timer1Recurr 12000;
BA_REL_ "GenSigTimeoutTime" BU_SG_REL_ VCM SG_ 1120 EngineTimer_stat_Timer1Recurr 3000;
BA_REL_ "GenSigFirstTimeoutTime" BU_SG_REL_ VCM SG_ 1120 EngineTimer_stat_Timer3Minutes 12000;
BA_REL_ "GenSigTimeoutTime" BU_SG_REL_ VCM SG_ 1120 EngineTimer_stat_Timer3Minutes 3000;
BA_REL_ "GenSigFirstTimeoutTime" BU_SG_REL_ VCM SG_ 1120 EngineTimer_stat_Timer2StartDay 12000;
BA_REL_ "GenSigTimeoutTime" BU_SG_REL_ VCM SG_ 1120 EngineTimer_stat_Timer2StartDay 3000;
BA_REL_ "GenSigFirstTimeoutTime" BU_SG_REL_ VCM SG_ 1120 EngineTimer_stat_Timer3Recurr 12000;
BA_REL_ "GenSigTimeoutTime" BU_SG_REL_ VCM SG_ 1120 EngineTimer_stat_Timer3Recurr 3000;
BA_REL_ "GenSigFirstTimeoutTime" BU_SG_REL_ VCM SG_ 1120 EngineTimer_stat_Timer1Hours 12000;
BA_REL_ "GenSigTimeoutTime" BU_SG_REL_ VCM SG_ 1120 EngineTimer_stat_Timer1Hours 3000;
BA_REL_ "GenSigFirstTimeoutTime" BU_SG_REL_ VCM SG_ 1120 EngineTimer_stat_Timer3_Status 12000;
BA_REL_ "GenSigTimeoutTime" BU_SG_REL_ VCM SG_ 1120 EngineTimer_stat_Timer3_Status 3000;
BA_REL_ "GenSigFirstTimeoutTime" BU_SG_REL_ VCM SG_ 1120 EngineTimer_stat_Timer1_Status 12000;
BA_REL_ "GenSigTimeoutTime" BU_SG_REL_ VCM SG_ 1120 EngineTimer_stat_Timer1_Status 3000;
BA_REL_ "GenSigFirstTimeoutTime" BU_SG_REL_ VCM SG_ 1120 EngineTimer_stat_Timer1Minutes 12000;
BA_REL_ "GenSigTimeoutTime" BU_SG_REL_ VCM SG_ 1120 EngineTimer_stat_Timer1Minutes 3000;
BA_REL_ "GenSigFirstTimeoutTime" BU_SG_REL_ VCM SG_ 1120 EngineTimer_stat_Timer2Recurr 12000;
BA_REL_ "GenSigTimeoutTime" BU_SG_REL_ VCM SG_ 1120 EngineTimer_stat_Timer2Recurr 3000;
BA_REL_ "GenSigFirstTimeoutTime" BU_SG_REL_ VCM SG_ 1120 EngineTimer_stat_Timer3Hours 12000;
BA_REL_ "GenSigTimeoutTime" BU_SG_REL_ VCM SG_ 1120 EngineTimer_stat_Timer3Hours 3000;
BA_REL_ "GenSigFirstTimeoutTime" BU_SG_REL_ VCM SG_ 1120 EngineTimer_stat_Timer2_Status 12000;
BA_REL_ "GenSigTimeoutTime" BU_SG_REL_ VCM SG_ 1120 EngineTimer_stat_Timer2_Status 3000;
BA_REL_ "GenSigFirstTimeoutTime" BU_SG_REL_ VCM SG_ 1120 EngineTimer_stat_Timer2Hours 12000;
BA_REL_ "GenSigTimeoutTime" BU_SG_REL_ VCM SG_ 1120 EngineTimer_stat_Timer2Hours 3000;
BA_REL_ "GenSigFirstTimeoutTime" BU_SG_REL_ VCM SG_ 1120 EngineTimer_stat_Timer1StartDay 12000;
BA_REL_ "GenSigTimeoutTime" BU_SG_REL_ VCM SG_ 1120 EngineTimer_stat_Timer1StartDay 3000;
BA_REL_ "GenSigFirstTimeoutTime" BU_SG_REL_ VCM SG_ 1120 EngineTimer_stat_Timer3StartDay 12000;
BA_REL_ "GenSigTimeoutTime" BU_SG_REL_ VCM SG_ 1120 EngineTimer_stat_Timer3StartDay 3000;
BA_REL_ "GenSigFirstTimeoutTime" BU_SG_REL_ VCM SG_ 1168 DiagFaultStat_CCM_FailTA 24000;
BA_REL_ "GenSigTimeoutTime" BU_SG_REL_ VCM SG_ 1168 DiagFaultStat_CCM_FailTA 6000;
BA_REL_ "GenSigFirstTimeoutTime" BU_SG_REL_ VCM SG_ 1168 DiagFaultStat_CCM_FailTB 24000;
BA_REL_ "GenSigTimeoutTime" BU_SG_REL_ VCM SG_ 1168 DiagFaultStat_CCM_FailTB 6000;
BA_REL_ "GenSigFirstTimeoutTime" BU_SG_REL_ VCM SG_ 1168 DiagFaultStat_CCM_DtcIdA 24000;
BA_REL_ "GenSigTimeoutTime" BU_SG_REL_ VCM SG_ 1168 DiagFaultStat_CCM_DtcIdA 6000;
BA_REL_ "GenSigFirstTimeoutTime" BU_SG_REL_ VCM SG_ 1168 DiagFaultStat_CCM_DtcIdB 24000;
BA_REL_ "GenSigTimeoutTime" BU_SG_REL_ VCM SG_ 1168 DiagFaultStat_CCM_DtcIdB 6000;
BA_REL_ "GenSigFirstTimeoutTime" BU_SG_REL_ VCM SG_ 1168 DiagFaultStat_CCM_EcuAdr 24000;
BA_REL_ "GenSigTimeoutTime" BU_SG_REL_ VCM SG_ 1168 DiagFaultStat_CCM_EcuAdr 6000;
BA_REL_ "GenSigFirstTimeoutTime" BU_SG_REL_ VCM SG_ 912 PHMaintenanceService_stat 12000;
BA_REL_ "GenSigTimeoutTime" BU_SG_REL_ VCM SG_ 912 PHMaintenanceService_stat 3000;
BA_REL_ "GenSigFirstTimeoutTime" BU_SG_REL_ VCM SG_ 912 ParkingClimateAvailability 12000;
BA_REL_ "GenSigTimeoutTime" BU_SG_REL_ VCM SG_ 912 ParkingClimateAvailability 3000;
BA_REL_ "GenSigFirstTimeoutTime" BU_SG_REL_ VCM SG_ 912 CabTemperature_Status 12000;
BA_REL_ "GenSigTimeoutTime" BU_SG_REL_ VCM SG_ 912 CabTemperature_Status 3000;
BA_REL_ "GenSigFirstTimeoutTime" BU_SG_REL_ VCM SG_ 656 AcCoolantPumpEngagementRequest 3000;
BA_REL_ "GenSigTimeoutTime" BU_SG_REL_ VCM SG_ 656 AcCoolantPumpEngagementRequest 600;
BA_REL_ "GenSigFirstTimeoutTime" BU_SG_REL_ VCM SG_ 402 PHTimer3_stat_Minutes 3000;
BA_REL_ "GenSigTimeoutTime" BU_SG_REL_ VCM SG_ 402 PHTimer3_stat_Minutes 300;
BA_REL_ "GenSigFirstTimeoutTime" BU_SG_REL_ VCM SG_ 402 PHTimer2_stat_StartDay 3000;
BA_REL_ "GenSigTimeoutTime" BU_SG_REL_ VCM SG_ 402 PHTimer2_stat_StartDay 300;
BA_REL_ "GenSigFirstTimeoutTime" BU_SG_REL_ VCM SG_ 402 PHTimer2_stat_Recurrence 3000;
BA_REL_ "GenSigTimeoutTime" BU_SG_REL_ VCM SG_ 402 PHTimer2_stat_Recurrence 300;
BA_REL_ "GenSigFirstTimeoutTime" BU_SG_REL_ VCM SG_ 402 PHTimer3_stat_Temp 3000;
BA_REL_ "GenSigTimeoutTime" BU_SG_REL_ VCM SG_ 402 PHTimer3_stat_Temp 300;
BA_REL_ "GenSigFirstTimeoutTime" BU_SG_REL_ VCM SG_ 402 PHTimer2_stat_Temp 3000;
BA_REL_ "GenSigTimeoutTime" BU_SG_REL_ VCM SG_ 402 PHTimer2_stat_Temp 300;
BA_REL_ "GenSigFirstTimeoutTime" BU_SG_REL_ VCM SG_ 402 PHTimer3_stat_StartDay 3000;
BA_REL_ "GenSigTimeoutTime" BU_SG_REL_ VCM SG_ 402 PHTimer3_stat_StartDay 300;
BA_REL_ "GenSigFirstTimeoutTime" BU_SG_REL_ VCM SG_ 402 PHTimer2_stat_Hours 3000;
BA_REL_ "GenSigTimeoutTime" BU_SG_REL_ VCM SG_ 402 PHTimer2_stat_Hours 300;
BA_REL_ "GenSigFirstTimeoutTime" BU_SG_REL_ VCM SG_ 402 PHTimer3_stat_Recurrence 3000;
BA_REL_ "GenSigTimeoutTime" BU_SG_REL_ VCM SG_ 402 PHTimer3_stat_Recurrence 300;
BA_REL_ "GenSigFirstTimeoutTime" BU_SG_REL_ VCM SG_ 402 PHTimer2_stat_Minutes 3000;
BA_REL_ "GenSigTimeoutTime" BU_SG_REL_ VCM SG_ 402 PHTimer2_stat_Minutes 300;
BA_REL_ "GenSigFirstTimeoutTime" BU_SG_REL_ VCM SG_ 402 PHTimer2_stat_Status 3000;
BA_REL_ "GenSigTimeoutTime" BU_SG_REL_ VCM SG_ 402 PHTimer2_stat_Status 300;
BA_REL_ "GenSigFirstTimeoutTime" BU_SG_REL_ VCM SG_ 402 PHTimer3_stat_Status 3000;
BA_REL_ "GenSigTimeoutTime" BU_SG_REL_ VCM SG_ 402 PHTimer3_stat_Status 300;
BA_REL_ "GenSigFirstTimeoutTime" BU_SG_REL_ VCM SG_ 402 PHTimer3_stat_Hours 3000;
BA_REL_ "GenSigTimeoutTime" BU_SG_REL_ VCM SG_ 402 PHTimer3_stat_Hours 300;
BA_REL_ "GenSigFirstTimeoutTime" BU_SG_REL_ VCM SG_ 401 PHTimer1_stat_Recurrence 3000;
BA_REL_ "GenSigTimeoutTime" BU_SG_REL_ VCM SG_ 401 PHTimer1_stat_Recurrence 300;
BA_REL_ "GenSigFirstTimeoutTime" BU_SG_REL_ VCM SG_ 401 PHTimer1_stat_Temp 3000;
BA_REL_ "GenSigTimeoutTime" BU_SG_REL_ VCM SG_ 401 PHTimer1_stat_Temp 300;
BA_REL_ "GenSigFirstTimeoutTime" BU_SG_REL_ VCM SG_ 401 PHTimer1_stat_Duration 3000;
BA_REL_ "GenSigTimeoutTime" BU_SG_REL_ VCM SG_ 401 PHTimer1_stat_Duration 300;
BA_REL_ "GenSigFirstTimeoutTime" BU_SG_REL_ VCM SG_ 401 PHTimer1_stat_Status 3000;
BA_REL_ "GenSigTimeoutTime" BU_SG_REL_ VCM SG_ 401 PHTimer1_stat_Status 300;
BA_REL_ "GenSigFirstTimeoutTime" BU_SG_REL_ VCM SG_ 401 PHTimer_rqst_Hours 3000;
BA_REL_ "GenSigTimeoutTime" BU_SG_REL_ VCM SG_ 401 PHTimer_rqst_Hours 300;
BA_REL_ "GenSigFirstTimeoutTime" BU_SG_REL_ VCM SG_ 401 PHTimer_rqst_SetAlarmOper 3000;
BA_REL_ "GenSigTimeoutTime" BU_SG_REL_ VCM SG_ 401 PHTimer_rqst_SetAlarmOper 300;
BA_REL_ "GenSigFirstTimeoutTime" BU_SG_REL_ VCM SG_ 401 PHTimer_rqst_Minutes 3000;
BA_REL_ "GenSigTimeoutTime" BU_SG_REL_ VCM SG_ 401 PHTimer_rqst_Minutes 300;
BA_REL_ "GenSigFirstTimeoutTime" BU_SG_REL_ VCM SG_ 401 PHTimer1_stat_Hours 3000;
BA_REL_ "GenSigTimeoutTime" BU_SG_REL_ VCM SG_ 401 PHTimer1_stat_Hours 300;
BA_REL_ "GenSigFirstTimeoutTime" BU_SG_REL_ VCM SG_ 401 PHTimer1_stat_Minutes 3000;
BA_REL_ "GenSigTimeoutTime" BU_SG_REL_ VCM SG_ 401 PHTimer1_stat_Minutes 300;
BA_REL_ "GenSigFirstTimeoutTime" BU_SG_REL_ VCM SG_ 401 PHTimer_rqst_DayOfWeekRq 3000;
BA_REL_ "GenSigTimeoutTime" BU_SG_REL_ VCM SG_ 401 PHTimer_rqst_DayOfWeekRq 300;
BA_REL_ "GenSigFirstTimeoutTime" BU_SG_REL_ VCM SG_ 401 PHTimer1_stat_StartDay 3000;
BA_REL_ "GenSigTimeoutTime" BU_SG_REL_ VCM SG_ 401 PHTimer1_stat_StartDay 300;
BA_REL_ "GenSigFirstTimeoutTime" BU_SG_REL_ VCM SG_ 400 WindscreenDefrostInd_cmd 3000;
BA_REL_ "GenSigTimeoutTime" BU_SG_REL_ VCM SG_ 400 WindscreenDefrostInd_cmd 300;
BA_REL_ "GenSigFirstTimeoutTime" BU_SG_REL_ VCM SG_ 400 ParkingHeater_IndicationCmd 3000;
BA_REL_ "GenSigTimeoutTime" BU_SG_REL_ VCM SG_ 400 ParkingHeater_IndicationCmd 300;
BA_REL_ "GenSigFirstTimeoutTime" BU_SG_REL_ VCM SG_ 400 AutoBlowerLevelIndication_Cmd 3000;
BA_REL_ "GenSigTimeoutTime" BU_SG_REL_ VCM SG_ 400 AutoBlowerLevelIndication_Cmd 300;
BA_REL_ "GenSigFirstTimeoutTime" BU_SG_REL_ VCM SG_ 400 AC_CompressorClutchCmd 3000;
BA_REL_ "GenSigTimeoutTime" BU_SG_REL_ VCM SG_ 400 AC_CompressorClutchCmd 300;
BA_REL_ "GenSigFirstTimeoutTime" BU_SG_REL_ VCM SG_ 400 ACdisplayIndication_Cmd 3000;
BA_REL_ "GenSigTimeoutTime" BU_SG_REL_ VCM SG_ 400 ACdisplayIndication_Cmd 300;
BA_REL_ "GenSigFirstTimeoutTime" BU_SG_REL_ IC SG_ 400 ParkingHeaterCleaning_Rqst 3000;
BA_REL_ "GenSigTimeoutTime" BU_SG_REL_ IC SG_ 400 ParkingHeaterCleaning_Rqst 300;
BA_REL_ "GenSigFirstTimeoutTime" BU_SG_REL_ VCM SG_ 400 ParkingHeaterCleaning_Rqst 3000;
BA_REL_ "GenSigTimeoutTime" BU_SG_REL_ VCM SG_ 400 ParkingHeaterCleaning_Rqst 300;
BA_REL_ "GenSigFirstTimeoutTime" BU_SG_REL_ IC SG_ 400 TemperatureRqstIndication_cmd 3000;
BA_REL_ "GenSigTimeoutTime" BU_SG_REL_ IC SG_ 400 TemperatureRqstIndication_cmd 300;
BA_REL_ "GenSigFirstTimeoutTime" BU_SG_REL_ VCM SG_ 400 TemperatureRqstIndication_cmd 3000;
BA_REL_ "GenSigTimeoutTime" BU_SG_REL_ VCM SG_ 400 TemperatureRqstIndication_cmd 300;
BA_REL_ "GenSigFirstTimeoutTime" BU_SG_REL_ VCM SG_ 400 ParkingClimate_IndicationCmd 3000;
BA_REL_ "GenSigTimeoutTime" BU_SG_REL_ VCM SG_ 400 ParkingClimate_IndicationCmd 300;
BA_REL_ "GenSigFirstTimeoutTime" BU_SG_REL_ IC SG_ 400 ParkingClimate_IndicationCmd 3000;
BA_REL_ "GenSigTimeoutTime" BU_SG_REL_ IC SG_ 400 ParkingClimate_IndicationCmd 300;
BA_REL_ "GenSigFirstTimeoutTime" BU_SG_REL_ VCM SG_ 400 ACmode_IndicationCmd 3000;
BA_REL_ "GenSigTimeoutTime" BU_SG_REL_ VCM SG_ 400 ACmode_IndicationCmd 300;
BA_REL_ "GenSigFirstTimeoutTime" BU_SG_REL_ VCM SG_ 400 AutoDefogIndication_Cmd 3000;
BA_REL_ "GenSigTimeoutTime" BU_SG_REL_ VCM SG_ 400 AutoDefogIndication_Cmd 300;
BA_REL_ "GenSigFirstTimeoutTime" BU_SG_REL_ VCM SG_ 400 TempRqst_cmd 3000;
BA_REL_ "GenSigTimeoutTime" BU_SG_REL_ VCM SG_ 400 TempRqst_cmd 300;
BA_REL_ "GenSigFirstTimeoutTime" BU_SG_REL_ IC SG_ 400 ExtraHeating_status 3000;
BA_REL_ "GenSigTimeoutTime" BU_SG_REL_ IC SG_ 400 ExtraHeating_status 300;
BA_REL_ "GenSigFirstTimeoutTime" BU_SG_REL_ VCM SG_ 400 ExtraHeating_status 3000;
BA_REL_ "GenSigTimeoutTime" BU_SG_REL_ VCM SG_ 400 ExtraHeating_status 300;
BA_REL_ "GenSigFirstTimeoutTime" BU_SG_REL_ VCM SG_ 400 AQSmodeIndication_Cmd 3000;
BA_REL_ "GenSigTimeoutTime" BU_SG_REL_ VCM SG_ 400 AQSmodeIndication_Cmd 300;
BA_REL_ "GenSigFirstTimeoutTime" BU_SG_REL_ VCM SG_ 400 CabInteriorTempVentilated_Stat 3000;
BA_REL_ "GenSigTimeoutTime" BU_SG_REL_ VCM SG_ 400 CabInteriorTempVentilated_Stat 300;
BA_REL_ "GenSigFirstTimeoutTime" BU_SG_REL_ VCM SG_ 400 AutoMode_IndicationCmd 3000;
BA_REL_ "GenSigTimeoutTime" BU_SG_REL_ VCM SG_ 400 AutoMode_IndicationCmd 300;
BA_REL_ "GenSigFirstTimeoutTime" BU_SG_REL_ VCM SG_ 400 ShortStopHeater_cmd 3000;
BA_REL_ "GenSigTimeoutTime" BU_SG_REL_ VCM SG_ 400 ShortStopHeater_cmd 300;
BA_REL_ "GenSigFirstTimeoutTime" BU_SG_REL_ VCM SG_ 400 ACCoolingFanSpeedRequest_CCM 3000;
BA_REL_ "GenSigTimeoutTime" BU_SG_REL_ VCM SG_ 400 ACCoolingFanSpeedRequest_CCM 300;
VAL_ 156 LiftAxle2LowerACK 7 "LiftAxle2LowerACK_NotAvailable" 6 "LiftAxle2LowerACK_Error" 5 "LiftAxle2LowerACK_SystemDeniedVersatile" 4 "LiftAxle2LowerACK_Spare_01" 3 "LiftAxle2LowerACK_Spare" 2 "LiftAxle2LowerACK_LowerDeniedRAS_EC" 1 "LiftAxle2LowerACK_ChangeAcknowledged" 0 "LiftAxle2LowerACK_NoAction" ;
VAL_ 156 LiftAxle2PositionStatus 7 "LiftAxlePositionStatus_NotAvailable" 6 "LiftAxlePositionStatus_Error" 5 "LiftAxlePositionStatus_Reserved_01" 4 "LiftAxlePositionStatus_Reserved" 3 "LiftAxlePositionStatus_Lifting" 2 "LiftAxlePositionStatus_Lowering" 1 "LiftAxlePositionStatus_Lifted" 0 "LiftAxlePositionStatus_Lowered" ;
VAL_ 156 LiftAxle2LiftFuncSelected 7 "LiftAxleLiftAutoFuncSelected_NotAvailable" 6 "LiftAxleLiftAutoFuncSelected_Error" 5 "LiftAxleLiftAutoFuncSelected_Reserved" 4 "LiftAxleLiftAutoFuncSelected_UnlimitedLift" 3 "LiftAxleLiftAutoFuncSelected_LiftOverload" 2 "LiftAxleLiftAutoFuncSelected_LiftPlus30" 1 "LiftAxleLiftAutoFuncSelected_Lift" 0 "LiftAxleLiftAutoFuncSelected_NoLift" ;
VAL_ 156 PassengerDoorAjar_stat 7 "DoorAjar_stat_NotAvailable" 6 "DoorAjar_stat_Error" 2 "DoorAjar_stat_DoorOpen" 1 "DoorAjar_stat_DoorClosed" 0 "DoorAjar_stat_Idle" ;
VAL_ 156 AirFlowSelectionDownBtn_stat 3 "PushButtonStatus_NotAvailable" 2 "PushButtonStatus_Error" 1 "PushButtonStatus_Pushed" 0 "PushButtonStatus_Neutral" ;
VAL_ 156 LevelControlInformation 15 "LevelControlInformation_NotAvailable" 14 "LevelControlInformation_Error" 13 "LevelControlInformation_Reserved_06" 12 "LevelControlInformation_Reserved_05" 11 "LevelControlInformation_Reserved_04" 10 "LevelControlInformation_Reserved_03" 9 "LevelControlInformation_Reserved_02" 8 "LevelControlInformation_Reserved_01" 7 "LevelControlInformation_Reserved" 6 "LevelControlInformation_LimpHome" 5 "LevelControlInformation_FerryFunction" 4 "LevelControlInformation_KneelingHeight" 3 "LevelControlInformation_DriveHeight" 2 "LevelControlInformation_DockingHeight" 1 "LevelControlInformation_HeightAdjustment" 0 "LevelControlInformation_Prohibit" ;
VAL_ 156 LiftAxle1LowerACK 7 "LiftAxle1LowerACK_NotAvailable" 6 "LiftAxle1LowerACK_Error" 5 "LiftAxle1LowerACK_SystemDeniedVersatile" 4 "LiftAxle1LowerACK_Spare_01" 3 "LiftAxle1LowerACK_Spare" 2 "LiftAxle1LowerACK_LowerDeniedRAS_EC" 1 "LiftAxle1LowerACK_ChangeAcknowledged" 0 "LiftAxle1LowerACK_NoAction" ;
VAL_ 156 WiperModeStatus 7 "WiperModeStatus_NotAvailable" 6 "WiperModeStatus_ErrorIndicator" 5 "WiperModeStatus_Spare02" 4 "WiperModeStatus_Spare01" 3 "WiperModeStatus_Spare" 2 "WiperModeStatus_HighSpeedWiping" 1 "WiperModeStatus_LowSpeedWiping" 0 "WiperModeStatus_WiperOff" ;
VAL_ 156 Washing_HMI_rqst 3 "InactiveActive_NotAvailable" 2 "InactiveActive_Error" 1 "InactiveActive_Active" 0 "InactiveActive_Inactive" ;
VAL_ 156 LiftAxle2AutoLiftSelected 3 "FalseTrue_NotAvaiable" 2 "FalseTrue_Error" 1 "FalseTrue_True" 0 "FalseTrue_False" ;
VAL_ 156 ReverseGearEngaged 3 "ReverseGearEngaged_NotAvailable" 2 "ReverseGearEngaged_Error" 1 "ReverseGearEngaged_ReverseGearEngaged" 0 "ReverseGearEngaged_ReverseGearNotEngaged" ;
VAL_ 156 LiftAxle1PositionStatus 7 "LiftAxlePositionStatus_NotAvailable" 6 "LiftAxlePositionStatus_Error" 5 "LiftAxlePositionStatus_Reserved_01" 4 "LiftAxlePositionStatus_Reserved" 3 "LiftAxlePositionStatus_Lifting" 2 "LiftAxlePositionStatus_Lowering" 1 "LiftAxlePositionStatus_Lifted" 0 "LiftAxlePositionStatus_Lowered" ;
VAL_ 156 ACC_Status 7 "ACC_Status_NotAvailable" 6 "ACC_Status_Error" 5 "ACC_Status_ACCFailureAndInactive" 4 "ACC_Status_Reserved" 3 "ACC_Status_ActiveWithLimitedBrakeCapacity" 2 "ACC_Status_ActiveECONOMYMODE" 1 "ACC_Status_ActiveSTANDARDMODE" 0 "ACC_Status_Inactive" ;
VAL_ 156 LECM_CabClim_MaxDef_GuiReq 3 "PushButtonStatus_NotAvailable" 2 "PushButtonStatus_Error" 1 "PushButtonStatus_Pushed" 0 "PushButtonStatus_Neutral" ;
VAL_ 156 RegenerationSwitchStatus 7 "A3PosSwitchStatus_NotAvailable" 6 "A3PosSwitchStatus_Error" 5 "A3PosSwitchStatus_Spare_02" 4 "A3PosSwitchStatus_Spare_01" 3 "A3PosSwitchStatus_Spare" 2 "A3PosSwitchStatus_Upper" 1 "A3PosSwitchStatus_Lower" 0 "A3PosSwitchStatus_Middle" ;
VAL_ 156 DSWindowPosition 7 "WindowPosition_NotAvailable" 6 "WindowPosition_Error" 5 "WindowPosition_Spare" 4 "WindowPosition_UnknownPosition" 3 "WindowPosition_Open_70_100Percent" 2 "WindowPosition_Open_30_70Percent" 1 "WindowPosition_Open_0_30Percent" 0 "WindowPosition_Closed" ;
VAL_ 156 WindscreenDefrost_ButtonStatus 3 "PushButtonStatus_NotAvailable" 2 "PushButtonStatus_Error" 1 "PushButtonStatus_Pushed" 0 "PushButtonStatus_Neutral" ;
VAL_ 156 GearSplit_Status 3 "GearSplit_Status_NotAvailable" 2 "GearSplit_Status_Error" 1 "GearSplit_Status_HighSplit" 0 "GearSplit_Status_LowSplit" ;
VAL_ 156 KeyPosition 7 "KeyPosition_NotAvailable" 6 "KeyPosition_ErrorIndicator" 5 "KeyPosition_IgnitionKeyInCrankPosition" 4 "KeyPosition_IgnitionKeyInPreheatPosition" 3 "KeyPosition_IgnitionKeyIn15PositionNormalDrivingPosition" 2 "KeyPosition_IgnitionKeyInAccessoryPosition" 1 "KeyPosition_IgnitionKeyInOffPosition" 0 "KeyPosition_KeyOut" ;
VAL_ 156 LiftAxle1LiftFuncSelected 7 "LiftAxleLiftAutoFuncSelected_NotAvailable" 6 "LiftAxleLiftAutoFuncSelected_Error" 5 "LiftAxleLiftAutoFuncSelected_Reserved" 4 "LiftAxleLiftAutoFuncSelected_UnlimitedLift" 3 "LiftAxleLiftAutoFuncSelected_LiftOverload" 2 "LiftAxleLiftAutoFuncSelected_LiftPlus30" 1 "LiftAxleLiftAutoFuncSelected_Lift" 0 "LiftAxleLiftAutoFuncSelected_NoLift" ;
VAL_ 156 LiftAxle2UpRequestACK 7 "LiftAxleUpRequestACK_NotAvailable" 6 "LiftAxleUpRequestACK_Error" 5 "LiftAxleUpRequestACK_SystemDeniedVersatile" 4 "LiftAxleUpRequestACK_LiftDeniedPBrakeActive" 3 "LiftAxleUpRequestACK_LiftDeniedRearOverload" 2 "LiftAxleUpRequestACK_LiftDeniedFrontOverload" 1 "LiftAxleUpRequestACK_ChangeAcknowledged" 0 "LiftAxleUpRequestACK_NoAction" ;
VAL_ 156 PreTrip_ButtonStat3 3 "PushButtonStatus_NotAvailable" 2 "PushButtonStatus_Error" 1 "PushButtonStatus_Pushed" 0 "PushButtonStatus_Neutral" ;
VAL_ 156 LiftAxle1UpRequestACK 7 "LiftAxleUpRequestACK_NotAvailable" 6 "LiftAxleUpRequestACK_Error" 5 "LiftAxleUpRequestACK_SystemDeniedVersatile" 4 "LiftAxleUpRequestACK_LiftDeniedPBrakeActive" 3 "LiftAxleUpRequestACK_LiftDeniedRearOverload" 2 "LiftAxleUpRequestACK_LiftDeniedFrontOverload" 1 "LiftAxleUpRequestACK_ChangeAcknowledged" 0 "LiftAxleUpRequestACK_NoAction" ;
VAL_ 138 AcceleratorPedalLowIdleSwitch 3 "AcceleratorPedalLowIdleSwitch_NotAvailable" 2 "AcceleratorPedalLowIdleSwitch_Error" 1 "AcceleratorPedalLowIdleSwitch_INLowIdleCondition" 0 "AcceleratorPedalLowIdleSwitch_NotInLowIdleCondition" ;
VAL_ 138 VehicleMode 15 "VehicleMode_NotAvailable" 14 "VehicleMode_Error" 13 "VehicleMode_Spare_7" 12 "VehicleMode_Spare_6" 11 "VehicleMode_Spare_5" 10 "VehicleMode_Spare_4" 9 "VehicleMode_Spare_3" 8 "VehicleMode_Spare_2" 7 "VehicleMode_Spare_1" 6 "VehicleMode_Running" 5 "VehicleMode_Cranking" 4 "VehicleMode_PreRunning" 3 "VehicleMode_Accessory" 2 "VehicleMode_Living" 1 "VehicleMode_Parked" 0 "VehicleMode_Hibernate" ;
VAL_ 138 AcceleratorPedalQuality 3 "PrimaryAcceleratorPedalQuality_NotAvailable" 2 "PrimaryAcceleratorPedalQuality_ErrorMode" 1 "PrimaryAcceleratorPedalQuality_DowngradedMode" 0 "PrimaryAcceleratorPedalQuality_NormalMode" ;
VAL_ 895 DriverCrank_rqst 3 "Request_NotAvailable" 2 "Request_Error" 1 "Request_RequestActive" 0 "Request_NotRequested" ;
VAL_ 895 CabTiltLockStatus 3 "UnlockedLocked_NotAvailable" 2 "UnlockedLocked_Error" 1 "UnlockedLocked_Locked" 0 "UnlockedLocked_Unlocked" ;
VAL_ 895 CabTiltEnableStatus 3 "DisableEnable_NotAvailable" 2 "DisableEnable_Error" 1 "DisableEnable_Enable" 0 "DisableEnable_Disable" ;
VAL_ 1104 CabTilt_rqst 3 "InactiveActive_NotAvailable" 2 "InactiveActive_Error" 1 "InactiveActive_Active" 0 "InactiveActive_Inactive" ;
VAL_ 432 DriverSeatBeltSwitch 3 "DriverSeatBeltSwitch_NotAvailable" 2 "DriverSeatBeltSwitch_Error" 1 "DriverSeatBeltSwitch_SeatBeltBuckledFastened" 0 "DriverSeatBeltSwitch_SeatBeltUnbuckledUnfastened" ;
VAL_ 432 FrontLidAjar_Stat 3 "ClosedOpen_NotAvailable" 2 "ClosedOpen_Error" 1 "ClosedOpen_Open" 0 "ClosedOpen_Closed" ;
VAL_ 432 LevelingThumbwheel_stat 31 "Thumbwheel_stat_NotAvaliable" 30 "Thumbwheel_stat_Error" 29 "Thumbwheel_stat_Spare_12" 28 "Thumbwheel_stat_Spare_11" 27 "Thumbwheel_stat_Spare_10" 26 "Thumbwheel_stat_Spare_09" 25 "Thumbwheel_stat_Spare_08" 24 "Thumbwheel_stat_Spare_07" 23 "Thumbwheel_stat_Spare_06" 22 "Thumbwheel_stat_Spare_05" 21 "Thumbwheel_stat_Spare_04" 20 "Thumbwheel_stat_Spare_03" 19 "Thumbwheel_stat_Spare_02" 18 "Thumbwheel_stat_Spare_01" 17 "Thumbwheel_stat_Spare" 16 "Thumbwheel_stat_ThumbWheelPos16" 15 "Thumbwheel_stat_ThumbWheelPos15" 14 "Thumbwheel_stat_ThumbWheelPos14" 13 "Thumbwheel_stat_ThumbWheelPos13" 12 "Thumbwheel_stat_ThumbWheelPos12" 11 "Thumbwheel_stat_ThumbWheelPos11" 10 "Thumbwheel_stat_ThumbWheelPos10" 9 "Thumbwheel_stat_ThumbWheelPos9" 8 "Thumbwheel_stat_ThumbWheelPos8" 7 "Thumbwheel_stat_ThumbWheelPos7" 6 "Thumbwheel_stat_ThumbWheelPos6" 5 "Thumbwheel_stat_ThumbWheelPos5" 4 "Thumbwheel_stat_ThumbWheelPos4" 3 "Thumbwheel_stat_ThumbWheelPos3" 2 "Thumbwheel_stat_ThumbWheelPos2" 1 "Thumbwheel_stat_ThumbWheelPos1" 0 "Thumbwheel_stat_ThumbWheelPos0" ;
VAL_ 179 LightMode_Status_Ctr_1 15 "Freewheel_Status_Ctr_NotAvailable" 14 "Freewheel_Status_Ctr_Error" 13 "Freewheel_Status_Ctr_Position13" 12 "Freewheel_Status_Ctr_Position12" 11 "Freewheel_Status_Ctr_Position11" 10 "Freewheel_Status_Ctr_Position10" 9 "Freewheel_Status_Ctr_Position9" 8 "Freewheel_Status_Ctr_Position8" 7 "Freewheel_Status_Ctr_Position7" 6 "Freewheel_Status_Ctr_Position6" 5 "Freewheel_Status_Ctr_Position5" 4 "Freewheel_Status_Ctr_Position4" 3 "Freewheel_Status_Ctr_Position3" 2 "Freewheel_Status_Ctr_Position2" 1 "Freewheel_Status_Ctr_Position1" 0 "Freewheel_Status_Ctr_NoMovement" ;
VAL_ 179 ReverseWarning_rqst 3 "ReverseWarning_rqst_NotAvailable" 2 "ReverseWarning_rqst_Error" 1 "ReverseWarning_rqst_SoundOn" 0 "ReverseWarning_rqst_SoundOff" ;
VAL_ 179 FogLightFront_ButtonStatus_1 3 "PushButtonStatus_NotAvailable" 2 "PushButtonStatus_Error" 1 "PushButtonStatus_Pushed" 0 "PushButtonStatus_Neutral" ;
VAL_ 179 FogLightRear_ButtonStatus_1 3 "PushButtonStatus_NotAvailable" 2 "PushButtonStatus_Error" 1 "PushButtonStatus_Pushed" 0 "PushButtonStatus_Neutral" ;
VAL_ 1184 FasPersonalSettingsButton_rqst 7 "FasPersSettingsButton_NotAvailable" 6 "FasPersSettingsButton_Error" 5 "FasPersSettingsButton_Spare" 4 "FasPersSettingsButton_UserDefinedButton" 3 "FasPersSettingsButton_PresetButtonHeavy" 2 "FasPersSettingsButton_PresetButtonFirm" 1 "FasPersSettingsButton_PresetButtonLight" 0 "FasPersSettingsButton_PresetButtonDefault" ;
VAL_ 1184 FasDriver_rqst 15 "FasDriver_NotAvailable" 14 "FasDriver_Error" 13 "FasDriver_Spare3" 12 "FasDriver_Spare2" 11 "FasDriver_Spare1" 10 "FasDriver_Driver10" 9 "FasDriver_Driver9" 8 "FasDriver_Driver8" 7 "FasDriver_Driver7" 6 "FasDriver_Driver6" 5 "FasDriver_Driver5" 4 "FasDriver_Driver4" 3 "FasDriver_Driver3" 2 "FasDriver_Driver2" 1 "FasDriver_Driver1" 0 "FasDriver_DefaultDriver" ;
VAL_ 1184 FasUsrDefinedStorage_rqst 3 "FasUsrDefinedStorage_NotAvailable" 2 "FasUsrDefinedStorage_Error" 1 "FasUsrDefinedStorage_StoreUserDefinedSetting" 0 "FasUsrDefinedStorage_DoNotStoreUserDefinedSetting" ;
VAL_ 932 DPF_ManualRegenerateRequest 3 "Request_NotAvailable" 2 "Request_Error" 1 "Request_RequestActive" 0 "Request_NotRequested" ;
VAL_ 932 DPF_ManualRegenerateInhibit 3 "InactiveActive_NotAvailable" 2 "InactiveActive_Error" 1 "InactiveActive_Active" 0 "InactiveActive_Inactive" ;
VAL_ 932 DPF_ManualRegenerateTimeReq 3 "NotRequested_NotAvailable" 2 "NotRequested_Error" 1 "NotRequested_Requested" 0 "NotRequested_NotRequested" ;
VAL_ 930 OBDRelDTC_IC_DrvngCycleB 3 "DrivingCycleLSBB_NotAvailable" 2 "DrivingCycleLSBB_Error" 1 "DrivingCycleLSBB_Value1" 0 "DrivingCycleLSBB_Value0" ;
VAL_ 930 OBDRelDTC_IC_EvalResultA 3 "DTCEvalResultA_NotAvailable" 2 "DTCEvalResultA_Error" 1 "DTCEvalResultA_Passed" 0 "DTCEvalResultA_Failed" ;
VAL_ 930 OBDRelDTC_IC_EvalResultB 3 "DTCEvalResultB_NotAvailable" 2 "DTCEvalResultB_Error" 1 "DTCEvalResultB_Passed" 0 "DTCEvalResultB_Failed" ;
VAL_ 930 OBDRelDTC_IC_EvalStatA 3 "DTCEvalStatA_NotAvailable" 2 "DTCEvalStatA_Error" 1 "DTCEvalStatA_Complete" 0 "DTCEvalStatA_Incomplete" ;
VAL_ 930 OBDRelDTC_IC_DrvngCycleA 3 "DrivingCycleLSBA_NotAvailable" 2 "DrivingCycleLSBA_Error" 1 "DrivingCycleLSBA_Value1" 0 "DrivingCycleLSBA_Value0" ;
VAL_ 930 OBDRelDTC_IC_EvalStatB 3 "DTCEvalStatB_NotAvailable" 2 "DTCEvalStatB_Error" 1 "DTCEvalStatB_Complete" 0 "DTCEvalStatB_Incomplete" ;
VAL_ 928 Set_EnergySetting 7 "EnergySetting_NotAvailable" 6 "EnergySetting_Error" 5 "EnergySetting_Spare2" 4 "EnergySetting_Spare1" 3 "EnergySetting_Customise" 2 "EnergySetting_PresetLevel2_HighEnergySaving" 1 "EnergySetting_PresetLevel1_EnergySaving" 0 "EnergySetting_OFF" ;
VAL_ 784 SpeedAdaptEnableRqst_SpeedLimit 3 "Selected_NotAvailable" 2 "Selected_Error" 1 "Selected_Selected" 0 "Selected_NotSelected" ;
VAL_ 784 SpeedAdaptEnableRqst_SlowTraffic 3 "Selected_NotAvailable" 2 "Selected_Error" 1 "Selected_Selected" 0 "Selected_NotSelected" ;
VAL_ 784 BattEnergySetLevel_input 7 "BattEnergySetLevel_input_NotAvailable" 6 "BattEnergySetLevel_input_Error" 5 "BattEnergySetLevel_input_Spare" 4 "BattEnergySetLevel_input_Level5" 3 "BattEnergySetLevel_input_Level4" 2 "BattEnergySetLevel_input_Level3" 1 "BattEnergySetLevel_input_Level2" 0 "BattEnergySetLevel_input_Level1" ;
VAL_ 784 SpeedAdaptationLevelRqst 7 "LowMidHigh_NotAvailable" 6 "LowMidHigh_Error" 5 "LowMidHigh_Spare3" 4 "LowMidHigh_Spare2" 3 "LowMidHigh_Spare1" 2 "LowMidHigh_High" 1 "LowMidHigh_Mid" 0 "LowMidHigh_Low" ;
VAL_ 784 SpeedAdaptEnableRqst_Curve 3 "Selected_NotAvailable" 2 "Selected_Error" 1 "Selected_Selected" 0 "Selected_NotSelected" ;
VAL_ 784 ExtraHeating_rqst 7 "ActivationRequest_NotAvailable" 6 "ActivationRequest_Error" 5 "ActivationRequest_Spare3" 4 "ActivationRequest_Spare2" 3 "ActivationRequest_Spare1" 2 "ActivationRequest_AutoStart" 1 "ActivationRequest_Off" 0 "ActivationRequest_NoAction" ;
VAL_ 672 ParkingHeaterCleaning_cmd 3 "ParkingHeaterCleaning_cmd_NotAvailable" 2 "ParkingHeaterCleaning_cmd_Escaped" 1 "ParkingHeaterCleaning_cmd_Activated" 0 "ParkingHeaterCleaning_cmd_NoAction" ;
VAL_ 672 DriverMemory_rqst 31 "DriverMemory_rqst_Error" 30 "DriverMemory_rqst_NotAvailable" 29 "DriverMemory_rqst_Spare_07" 28 "DriverMemory_rqst_Spare_06" 27 "DriverMemory_rqst_Spare_05" 26 "DriverMemory_rqst_Spare_04" 25 "DriverMemory_rqst_Spare_03" 24 "DriverMemory_rqst_Spare_02" 23 "DriverMemory_rqst_Spare_01" 22 "DriverMemory_rqst_Spare" 21 "DriverMemory_rqst_ResetAllMemThenUseDefDriverMem" 20 "DriverMemory_rqst_ResetAndThenUseDriverMemory10" 19 "DriverMemory_rqst_ResetAndThenUseDriverMemory9" 18 "DriverMemory_rqst_ResetAndThenUseDriverMemory8" 17 "DriverMemory_rqst_ResetAndThenUseDriverMemory7" 16 "DriverMemory_rqst_ResetAndThenUseDriverMemory6" 15 "DriverMemory_rqst_ResetAndThenUseDriverMemory5" 14 "DriverMemory_rqst_ResetAndThenUseDriverMemory4" 13 "DriverMemory_rqst_ResetAndThenUseDriverMemory3" 12 "DriverMemory_rqst_ResetAndThenUseDriverMemory2" 11 "DriverMemory_rqst_ResetAndThenUseDriverMemory1" 10 "DriverMemory_rqst_UseDriverMemory10" 9 "DriverMemory_rqst_UseDriverMemory9" 8 "DriverMemory_rqst_UseDriverMemory8" 7 "DriverMemory_rqst_UseDriverMemory7" 6 "DriverMemory_rqst_UseDriverMemory6" 5 "DriverMemory_rqst_UseDriverMemory5" 4 "DriverMemory_rqst_UseDriverMemory4" 3 "DriverMemory_rqst_UseDriverMemory3" 2 "DriverMemory_rqst_UseDriverMemory2" 1 "DriverMemory_rqst_UseDriverMemory1" 0 "DriverMemory_rqst_UseDefaultDriverMemory" ;
VAL_ 672 FirstAxleLowerPrioRequested 7 "FirstAxleLowerPrio_NotAvailable" 6 "FirstAxleLowerPrio_Error" 5 "FirstAxleLowerPrio_Reserved_03" 4 "FirstAxleLowerPrio_Reserved_02" 3 "FirstAxleLowerPrio_Reserved_01" 2 "FirstAxleLowerPrio_Reserved" 1 "FirstAxleLowerPrio_LowerPusher" 0 "FirstAxleLowerPrio_LowerTag" ;
VAL_ 672 AutoShutOffAnswerInput 7 "AutoShutOffAnswerInput_NotAvailable" 6 "AutoShutOffAnswerInput_Error" 5 "AutoShutOffAnswerInput_Spare3" 4 "AutoShutOffAnswerInput_Spare2" 3 "AutoShutOffAnswerInput_Spare1" 2 "AutoShutOffAnswerInput_Delayed" 1 "AutoShutOffAnswerInput_NoAnswer" 0 "AutoShutOffAnswerInput_Accepted" ;
VAL_ 672 ManualEngineCoolingDev_Ind 3 "DeviceIndication_SpareValue" 2 "DeviceIndication_Blink" 1 "DeviceIndication_On" 0 "DeviceIndication_Off" ;
VAL_ 672 TemporaryRSLDeviceIndication 3 "DeviceIndication_SpareValue" 2 "DeviceIndication_Blink" 1 "DeviceIndication_On" 0 "DeviceIndication_Off" ;
VAL_ 672 ESC_ButtonIndication2 3 "DeviceIndication_SpareValue" 2 "DeviceIndication_Blink" 1 "DeviceIndication_On" 0 "DeviceIndication_Off" ;
VAL_ 672 WaterInFuelDrainRequest 3 "Request_NotAvailable" 2 "Request_Error" 1 "Request_RequestActive" 0 "Request_NotRequested" ;
VAL_ 672 PreTripIndication3 3 "DeviceIndication_SpareValue" 2 "DeviceIndication_Blink" 1 "DeviceIndication_On" 0 "DeviceIndication_Off" ;
VAL_ 672 ESCOff_DeviceIndication 3 "DeviceIndication_SpareValue" 2 "DeviceIndication_Blink" 1 "DeviceIndication_On" 0 "DeviceIndication_Off" ;
VAL_ 672 AWBEnableRequest 3 "DisableEnable_NotAvailable" 2 "DisableEnable_Error" 1 "DisableEnable_Enable" 0 "DisableEnable_Disable" ;
VAL_ 672 LampCheck_rqst 3 "LampCheck_NotAvailable" 2 "LampCheck_Error" 1 "LampCheck_PerformLampCheck" 0 "LampCheck_NoAction" ;
VAL_ 416 SSReq_Balance 3 "SystemSoundBalance_Spare" 2 "SystemSoundBalance_Right" 1 "SystemSoundBalance_Left" 0 "SystemSoundBalance_Both" ;
VAL_ 416 PhoneButtonIndication_cmd 3 "DeviceIndication_SpareValue" 2 "DeviceIndication_Blink" 1 "DeviceIndication_On" 0 "DeviceIndication_Off" ;
VAL_ 416 FuncIndIlluminationLevel 7 "FuncIndIlluminationLevel_NotAvailable" 6 "FuncIndIlluminationLevel_Error" 5 "FuncIndIlluminationLevel_Spare" 4 "FuncIndIlluminationLevel_IlluminationLevel4" 3 "FuncIndIlluminationLevel_IlluminationLevel3" 2 "FuncIndIlluminationLevel_IlluminationLevel2" 1 "FuncIndIlluminationLevel_IlluminationLevel1" 0 "FuncIndIlluminationLevel_IlluminationOff" ;
VAL_ 416 BacklightCmd 31 "BacklightCmd_NotAvailable" 30 "BacklightCmd_Error" 16 "BacklightCmd_BacklightLevel16" 15 "BacklightCmd_BacklightLevel15" 14 "BacklightCmd_BacklightLevel14" 13 "BacklightCmd_BacklightLevel13" 12 "BacklightCmd_BacklightLevel12" 11 "BacklightCmd_BacklightLevel11" 10 "BacklightCmd_BacklightLevel10" 9 "BacklightCmd_BacklightLevel9" 8 "BacklightCmd_BacklightLevel8" 7 "BacklightCmd_BacklightLevel7" 6 "BacklightCmd_BacklightLevel6" 5 "BacklightCmd_BacklightLevel5" 4 "BacklightCmd_BacklightLevel4" 3 "BacklightCmd_BacklightLevel3" 2 "BacklightCmd_BacklightLevel2" 1 "BacklightCmd_BacklightLevel1" 0 "BacklightCmd_BacklightOff" ;
VAL_ 416 SSReq_Mixed 1 "SystemSoundMixed_MixedWithBackgroungSound" 0 "SystemSoundMixed_BackgroundSoundMuted" ;
VAL_ 416 BunkBacklightCmd 31 "BacklightCmd_NotAvailable" 30 "BacklightCmd_Error" 16 "BacklightCmd_BacklightLevel16" 15 "BacklightCmd_BacklightLevel15" 14 "BacklightCmd_BacklightLevel14" 13 "BacklightCmd_BacklightLevel13" 12 "BacklightCmd_BacklightLevel12" 11 "BacklightCmd_BacklightLevel11" 10 "BacklightCmd_BacklightLevel10" 9 "BacklightCmd_BacklightLevel9" 8 "BacklightCmd_BacklightLevel8" 7 "BacklightCmd_BacklightLevel7" 6 "BacklightCmd_BacklightLevel6" 5 "BacklightCmd_BacklightLevel5" 4 "BacklightCmd_BacklightLevel4" 3 "BacklightCmd_BacklightLevel3" 2 "BacklightCmd_BacklightLevel2" 1 "BacklightCmd_BacklightLevel1" 0 "BacklightCmd_BacklightOff" ;
VAL_ 416 SSReq_State 1 "SystemSoundState_Play" 0 "SystemSoundState_Stop" ;
VAL_ 211 TimeGapBtnStat 3 "PushButtonStatus_NotAvailable" 2 "PushButtonStatus_Error" 1 "PushButtonStatus_Pushed" 0 "PushButtonStatus_Neutral" ;
VAL_ 211 ATC_ButtonIndication 3 "DeviceIndication_SpareValue" 2 "DeviceIndication_Blink" 1 "DeviceIndication_On" 0 "DeviceIndication_Off" ;
VAL_ 211 PauseOffBtnStat 3 "PushButtonStatus_NotAvailable" 2 "PushButtonStatus_Error" 1 "PushButtonStatus_Pushed" 0 "PushButtonStatus_Neutral" ;
VAL_ 211 ABS_ButtonIndication 3 "DeviceIndication_SpareValue" 2 "DeviceIndication_Blink" 1 "DeviceIndication_On" 0 "DeviceIndication_Off" ;
VAL_ 211 SW_HeadlightInterrupt_Stat 3 "PushButtonStatus_NotAvailable" 2 "PushButtonStatus_Error" 1 "PushButtonStatus_Pushed" 0 "PushButtonStatus_Neutral" ;
VAL_ 211 PBAlertActiveStatus 7 "PBAlertActiveStatus_NotAvailable" 6 "PBAlertActiveStatus_Error" 5 "PBAlertActiveStatus_Spare3" 4 "PBAlertActiveStatus_Spare2" 3 "PBAlertActiveStatus_Spare1" 2 "PBAlertActiveStatus_ShortAlertActive" 1 "PBAlertActiveStatus_LongAlertActive" 0 "PBAlertActiveStatus_Inactive" ;
VAL_ 211 EcoRollEnableRequest 3 "InactiveActive_NotAvailable" 2 "InactiveActive_Error" 1 "InactiveActive_Active" 0 "InactiveActive_Inactive" ;
VAL_ 211 EcoSettingsBtnStat 3 "PushButtonStatus_NotAvailable" 2 "PushButtonStatus_Error" 1 "PushButtonStatus_Pushed" 0 "PushButtonStatus_Neutral" ;
VAL_ 211 SkipNextBtnStat 3 "PushButtonStatus_NotAvailable" 2 "PushButtonStatus_Error" 1 "PushButtonStatus_Pushed" 0 "PushButtonStatus_Neutral" ;
VAL_ 211 TCS_ButtonIndication 3 "DeviceIndication_SpareValue" 2 "DeviceIndication_Blink" 1 "DeviceIndication_On" 0 "DeviceIndication_Off" ;
VAL_ 211 DHCBtnStat 3 "PushButtonStatus_NotAvailable" 2 "PushButtonStatus_Error" 1 "PushButtonStatus_Pushed" 0 "PushButtonStatus_Neutral" ;
VAL_ 211 PhoneBtnStat 3 "PushButtonStatus_NotAvailable" 2 "PushButtonStatus_Error" 1 "PushButtonStatus_Pushed" 0 "PushButtonStatus_Neutral" ;
VAL_ 211 SkipPrevBtnStat 3 "PushButtonStatus_NotAvailable" 2 "PushButtonStatus_Error" 1 "PushButtonStatus_Pushed" 0 "PushButtonStatus_Neutral" ;
VAL_ 211 ActivateBtnStat 3 "PushButtonStatus_NotAvailable" 2 "PushButtonStatus_Error" 1 "PushButtonStatus_Pushed" 0 "PushButtonStatus_Neutral" ;
VAL_ 211 ResIncrBtnStat 3 "PushButtonStatus_NotAvailable" 2 "PushButtonStatus_Error" 1 "PushButtonStatus_Pushed" 0 "PushButtonStatus_Neutral" ;
VAL_ 211 SrcBtnStat 3 "PushButtonStatus_NotAvailable" 2 "PushButtonStatus_Error" 1 "PushButtonStatus_Pushed" 0 "PushButtonStatus_Neutral" ;
VAL_ 211 SetDecrBtnStat 3 "PushButtonStatus_NotAvailable" 2 "PushButtonStatus_Error" 1 "PushButtonStatus_Pushed" 0 "PushButtonStatus_Neutral" ;
VAL_ 211 MarkerInterruptButtonStatus 3 "PushButtonStatus_NotAvailable" 2 "PushButtonStatus_Error" 1 "PushButtonStatus_Pushed" 0 "PushButtonStatus_Neutral" ;
VAL_ 1120 EngineTimer_stat_Timer1Recurr 15 "HeaterTimerRecurrence_NotAvailable" 14 "HeaterTimerRecurrence_Error" 13 "HeaterTimerRecurrence_Spare_3" 12 "HeaterTimerRecurrence_Spare_2" 11 "HeaterTimerRecurrence_Spare_1" 10 "HeaterTimerRecurrence_Sundays" 9 "HeaterTimerRecurrence_Saturdays" 8 "HeaterTimerRecurrence_Fridays" 7 "HeaterTimerRecurrence_Thursdays" 6 "HeaterTimerRecurrence_Wednesdays" 5 "HeaterTimerRecurrence_Tuesdays" 4 "HeaterTimerRecurrence_Mondays" 3 "HeaterTimerRecurrence_Weekends" 2 "HeaterTimerRecurrence_AllWeekdays" 1 "HeaterTimerRecurrence_Daily" 0 "HeaterTimerRecurrence_None" ;
VAL_ 1120 EngineTimer_stat_Timer2StartDay 15 "HeaterTimerStartDay_NotAvailable" 14 "HeaterTimerStartDay_Error" 13 "HeaterTimerStartDay_Spare_05" 12 "HeaterTimerStartDay_Spare_04" 11 "HeaterTimerStartDay_Spare_03" 10 "HeaterTimerStartDay_Spare_02" 9 "HeaterTimerStartDay_Spare_01" 8 "HeaterTimerStartDay_Spare" 7 "HeaterTimerStartDay_Sunday" 6 "HeaterTimerStartDay_Saturday" 5 "HeaterTimerStartDay_Friday" 4 "HeaterTimerStartDay_Thursday" 3 "HeaterTimerStartDay_Wednesday" 2 "HeaterTimerStartDay_Tuesday" 1 "HeaterTimerStartDay_Monday" 0 "HeaterTimerStartDay_NotUsed" ;
VAL_ 1120 EngineTimer_stat_Timer3Recurr 15 "HeaterTimerRecurrence_NotAvailable" 14 "HeaterTimerRecurrence_Error" 13 "HeaterTimerRecurrence_Spare_3" 12 "HeaterTimerRecurrence_Spare_2" 11 "HeaterTimerRecurrence_Spare_1" 10 "HeaterTimerRecurrence_Sundays" 9 "HeaterTimerRecurrence_Saturdays" 8 "HeaterTimerRecurrence_Fridays" 7 "HeaterTimerRecurrence_Thursdays" 6 "HeaterTimerRecurrence_Wednesdays" 5 "HeaterTimerRecurrence_Tuesdays" 4 "HeaterTimerRecurrence_Mondays" 3 "HeaterTimerRecurrence_Weekends" 2 "HeaterTimerRecurrence_AllWeekdays" 1 "HeaterTimerRecurrence_Daily" 0 "HeaterTimerRecurrence_None" ;
VAL_ 1120 EngineTimer_stat_Timer3_Status 3 "ParkHeaterTimer_Status_NotAvailable" 2 "ParkHeaterTimer_Status_TimerDeleted" 1 "ParkHeaterTimer_Status_TimerNotActivated" 0 "ParkHeaterTimer_Status_TimerActivated" ;
VAL_ 1120 EngineTimer_stat_Timer1_Status 3 "ParkHeaterTimer_Status_NotAvailable" 2 "ParkHeaterTimer_Status_TimerDeleted" 1 "ParkHeaterTimer_Status_TimerNotActivated" 0 "ParkHeaterTimer_Status_TimerActivated" ;
VAL_ 1120 EngineTimer_stat_Timer2Recurr 15 "HeaterTimerRecurrence_NotAvailable" 14 "HeaterTimerRecurrence_Error" 13 "HeaterTimerRecurrence_Spare_3" 12 "HeaterTimerRecurrence_Spare_2" 11 "HeaterTimerRecurrence_Spare_1" 10 "HeaterTimerRecurrence_Sundays" 9 "HeaterTimerRecurrence_Saturdays" 8 "HeaterTimerRecurrence_Fridays" 7 "HeaterTimerRecurrence_Thursdays" 6 "HeaterTimerRecurrence_Wednesdays" 5 "HeaterTimerRecurrence_Tuesdays" 4 "HeaterTimerRecurrence_Mondays" 3 "HeaterTimerRecurrence_Weekends" 2 "HeaterTimerRecurrence_AllWeekdays" 1 "HeaterTimerRecurrence_Daily" 0 "HeaterTimerRecurrence_None" ;
VAL_ 1120 EngineTimer_stat_Timer2_Status 3 "ParkHeaterTimer_Status_NotAvailable" 2 "ParkHeaterTimer_Status_TimerDeleted" 1 "ParkHeaterTimer_Status_TimerNotActivated" 0 "ParkHeaterTimer_Status_TimerActivated" ;
VAL_ 1120 EngineTimer_stat_Timer1StartDay 15 "HeaterTimerStartDay_NotAvailable" 14 "HeaterTimerStartDay_Error" 13 "HeaterTimerStartDay_Spare_05" 12 "HeaterTimerStartDay_Spare_04" 11 "HeaterTimerStartDay_Spare_03" 10 "HeaterTimerStartDay_Spare_02" 9 "HeaterTimerStartDay_Spare_01" 8 "HeaterTimerStartDay_Spare" 7 "HeaterTimerStartDay_Sunday" 6 "HeaterTimerStartDay_Saturday" 5 "HeaterTimerStartDay_Friday" 4 "HeaterTimerStartDay_Thursday" 3 "HeaterTimerStartDay_Wednesday" 2 "HeaterTimerStartDay_Tuesday" 1 "HeaterTimerStartDay_Monday" 0 "HeaterTimerStartDay_NotUsed" ;
VAL_ 1120 EngineTimer_stat_Timer3StartDay 15 "HeaterTimerStartDay_NotAvailable" 14 "HeaterTimerStartDay_Error" 13 "HeaterTimerStartDay_Spare_05" 12 "HeaterTimerStartDay_Spare_04" 11 "HeaterTimerStartDay_Spare_03" 10 "HeaterTimerStartDay_Spare_02" 9 "HeaterTimerStartDay_Spare_01" 8 "HeaterTimerStartDay_Spare" 7 "HeaterTimerStartDay_Sunday" 6 "HeaterTimerStartDay_Saturday" 5 "HeaterTimerStartDay_Friday" 4 "HeaterTimerStartDay_Thursday" 3 "HeaterTimerStartDay_Wednesday" 2 "HeaterTimerStartDay_Tuesday" 1 "HeaterTimerStartDay_Monday" 0 "HeaterTimerStartDay_NotUsed" ;
VAL_ 912 PHMaintenanceService_stat 3 "PHMaintenanceService_stat_NotAvailable" 2 "PHMaintenanceService_stat_Error" 1 "PHMaintenanceService_stat_PHServiceNeeded" 0 "PHMaintenanceService_stat_NoPHServiceNeeded" ;
VAL_ 912 ParkingClimateAvailability 7 "ParkingClimateAvail_NotAvailable" 6 "ParkingClimateAvail_Error" 5 "ParkingClimateAvail_Spare3" 4 "ParkingClimateAvail_Spare2" 3 "ParkingClimateAvail_SystemNotAvailDueTolowFuel" 2 "ParkingClimateAvail_SystemNotAvailDueToRolloversensor" 1 "ParkingClimateAvail_SystemNotAvailDueToParkingBrake" 0 "ParkingClimateAvail_SystemAvailable" ;
VAL_ 402 PHTimer2_stat_StartDay 15 "HeaterTimerStartDay_NotAvailable" 14 "HeaterTimerStartDay_Error" 13 "HeaterTimerStartDay_Spare_05" 12 "HeaterTimerStartDay_Spare_04" 11 "HeaterTimerStartDay_Spare_03" 10 "HeaterTimerStartDay_Spare_02" 9 "HeaterTimerStartDay_Spare_01" 8 "HeaterTimerStartDay_Spare" 7 "HeaterTimerStartDay_Sunday" 6 "HeaterTimerStartDay_Saturday" 5 "HeaterTimerStartDay_Friday" 4 "HeaterTimerStartDay_Thursday" 3 "HeaterTimerStartDay_Wednesday" 2 "HeaterTimerStartDay_Tuesday" 1 "HeaterTimerStartDay_Monday" 0 "HeaterTimerStartDay_NotUsed" ;
VAL_ 402 PHTimer2_stat_Recurrence 15 "HeaterTimerRecurrence_NotAvailable" 14 "HeaterTimerRecurrence_Error" 13 "HeaterTimerRecurrence_Spare_3" 12 "HeaterTimerRecurrence_Spare_2" 11 "HeaterTimerRecurrence_Spare_1" 10 "HeaterTimerRecurrence_Sundays" 9 "HeaterTimerRecurrence_Saturdays" 8 "HeaterTimerRecurrence_Fridays" 7 "HeaterTimerRecurrence_Thursdays" 6 "HeaterTimerRecurrence_Wednesdays" 5 "HeaterTimerRecurrence_Tuesdays" 4 "HeaterTimerRecurrence_Mondays" 3 "HeaterTimerRecurrence_Weekends" 2 "HeaterTimerRecurrence_AllWeekdays" 1 "HeaterTimerRecurrence_Daily" 0 "HeaterTimerRecurrence_None" ;
VAL_ 402 PHTimer3_stat_Temp 31 "TemperatureRqstIndication_cmd_NotAvailable" 30 "TemperatureRqstIndication_cmd_Error" 29 "TemperatureRqstIndication_cmd_Spare_01" 28 "TemperatureRqstIndication_cmd_Spare" 27 "TemperatureRqstIndication_cmd_Max" 26 "TemperatureRqstIndication_cmd_29C" 25 "TemperatureRqstIndication_cmd_28C" 24 "TemperatureRqstIndication_cmd_27C" 23 "TemperatureRqstIndication_cmd_26C" 22 "TemperatureRqstIndication_cmd_25_5C" 21 "TemperatureRqstIndication_cmd_25C" 20 "TemperatureRqstIndication_cmd_24_5C" 19 "TemperatureRqstIndication_cmd_24C" 18 "TemperatureRqstIndication_cmd_23_5C" 17 "TemperatureRqstIndication_cmd_23C" 16 "TemperatureRqstIndication_cmd_22_5C" 15 "TemperatureRqstIndication_cmd_22C" 14 "TemperatureRqstIndication_cmd_21_5C" 13 "TemperatureRqstIndication_cmd_21C" 12 "TemperatureRqstIndication_cmd_20_5C" 11 "TemperatureRqstIndication_cmd_20C" 10 "TemperatureRqstIndication_cmd_19_5C" 9 "TemperatureRqstIndication_cmd_19C" 8 "TemperatureRqstIndication_cmd_18_5C" 7 "TemperatureRqstIndication_cmd_18C" 6 "TemperatureRqstIndication_cmd_17_5C" 5 "TemperatureRqstIndication_cmd_17C" 4 "TemperatureRqstIndication_cmd_16_5C" 3 "TemperatureRqstIndication_cmd_16C" 2 "TemperatureRqstIndication_cmd_15C" 1 "TemperatureRqstIndication_cmd_Min" 0 "TemperatureRqstIndication_cmd_NoTempDisplayed" ;
VAL_ 402 PHTimer2_stat_Temp 31 "TemperatureRqstIndication_cmd_NotAvailable" 30 "TemperatureRqstIndication_cmd_Error" 29 "TemperatureRqstIndication_cmd_Spare_01" 28 "TemperatureRqstIndication_cmd_Spare" 27 "TemperatureRqstIndication_cmd_Max" 26 "TemperatureRqstIndication_cmd_29C" 25 "TemperatureRqstIndication_cmd_28C" 24 "TemperatureRqstIndication_cmd_27C" 23 "TemperatureRqstIndication_cmd_26C" 22 "TemperatureRqstIndication_cmd_25_5C" 21 "TemperatureRqstIndication_cmd_25C" 20 "TemperatureRqstIndication_cmd_24_5C" 19 "TemperatureRqstIndication_cmd_24C" 18 "TemperatureRqstIndication_cmd_23_5C" 17 "TemperatureRqstIndication_cmd_23C" 16 "TemperatureRqstIndication_cmd_22_5C" 15 "TemperatureRqstIndication_cmd_22C" 14 "TemperatureRqstIndication_cmd_21_5C" 13 "TemperatureRqstIndication_cmd_21C" 12 "TemperatureRqstIndication_cmd_20_5C" 11 "TemperatureRqstIndication_cmd_20C" 10 "TemperatureRqstIndication_cmd_19_5C" 9 "TemperatureRqstIndication_cmd_19C" 8 "TemperatureRqstIndication_cmd_18_5C" 7 "TemperatureRqstIndication_cmd_18C" 6 "TemperatureRqstIndication_cmd_17_5C" 5 "TemperatureRqstIndication_cmd_17C" 4 "TemperatureRqstIndication_cmd_16_5C" 3 "TemperatureRqstIndication_cmd_16C" 2 "TemperatureRqstIndication_cmd_15C" 1 "TemperatureRqstIndication_cmd_Min" 0 "TemperatureRqstIndication_cmd_NoTempDisplayed" ;
VAL_ 402 PHTimer3_stat_StartDay 15 "HeaterTimerStartDay_NotAvailable" 14 "HeaterTimerStartDay_Error" 13 "HeaterTimerStartDay_Spare_05" 12 "HeaterTimerStartDay_Spare_04" 11 "HeaterTimerStartDay_Spare_03" 10 "HeaterTimerStartDay_Spare_02" 9 "HeaterTimerStartDay_Spare_01" 8 "HeaterTimerStartDay_Spare" 7 "HeaterTimerStartDay_Sunday" 6 "HeaterTimerStartDay_Saturday" 5 "HeaterTimerStartDay_Friday" 4 "HeaterTimerStartDay_Thursday" 3 "HeaterTimerStartDay_Wednesday" 2 "HeaterTimerStartDay_Tuesday" 1 "HeaterTimerStartDay_Monday" 0 "HeaterTimerStartDay_NotUsed" ;
VAL_ 402 PHTimer3_stat_Recurrence 15 "HeaterTimerRecurrence_NotAvailable" 14 "HeaterTimerRecurrence_Error" 13 "HeaterTimerRecurrence_Spare_3" 12 "HeaterTimerRecurrence_Spare_2" 11 "HeaterTimerRecurrence_Spare_1" 10 "HeaterTimerRecurrence_Sundays" 9 "HeaterTimerRecurrence_Saturdays" 8 "HeaterTimerRecurrence_Fridays" 7 "HeaterTimerRecurrence_Thursdays" 6 "HeaterTimerRecurrence_Wednesdays" 5 "HeaterTimerRecurrence_Tuesdays" 4 "HeaterTimerRecurrence_Mondays" 3 "HeaterTimerRecurrence_Weekends" 2 "HeaterTimerRecurrence_AllWeekdays" 1 "HeaterTimerRecurrence_Daily" 0 "HeaterTimerRecurrence_None" ;
VAL_ 402 PHTimer2_stat_Status 3 "ParkHeaterTimer_Status_NotAvailable" 2 "ParkHeaterTimer_Status_TimerDeleted" 1 "ParkHeaterTimer_Status_TimerNotActivated" 0 "ParkHeaterTimer_Status_TimerActivated" ;
VAL_ 402 PHTimer3_stat_Status 3 "ParkHeaterTimer_Status_NotAvailable" 2 "ParkHeaterTimer_Status_TimerDeleted" 1 "ParkHeaterTimer_Status_TimerNotActivated" 0 "ParkHeaterTimer_Status_TimerActivated" ;
VAL_ 401 PHTimer1_stat_Recurrence 15 "HeaterTimerRecurrence_NotAvailable" 14 "HeaterTimerRecurrence_Error" 13 "HeaterTimerRecurrence_Spare_3" 12 "HeaterTimerRecurrence_Spare_2" 11 "HeaterTimerRecurrence_Spare_1" 10 "HeaterTimerRecurrence_Sundays" 9 "HeaterTimerRecurrence_Saturdays" 8 "HeaterTimerRecurrence_Fridays" 7 "HeaterTimerRecurrence_Thursdays" 6 "HeaterTimerRecurrence_Wednesdays" 5 "HeaterTimerRecurrence_Tuesdays" 4 "HeaterTimerRecurrence_Mondays" 3 "HeaterTimerRecurrence_Weekends" 2 "HeaterTimerRecurrence_AllWeekdays" 1 "HeaterTimerRecurrence_Daily" 0 "HeaterTimerRecurrence_None" ;
VAL_ 401 PHTimer1_stat_Temp 31 "TemperatureRqstIndication_cmd_NotAvailable" 30 "TemperatureRqstIndication_cmd_Error" 29 "TemperatureRqstIndication_cmd_Spare_01" 28 "TemperatureRqstIndication_cmd_Spare" 27 "TemperatureRqstIndication_cmd_Max" 26 "TemperatureRqstIndication_cmd_29C" 25 "TemperatureRqstIndication_cmd_28C" 24 "TemperatureRqstIndication_cmd_27C" 23 "TemperatureRqstIndication_cmd_26C" 22 "TemperatureRqstIndication_cmd_25_5C" 21 "TemperatureRqstIndication_cmd_25C" 20 "TemperatureRqstIndication_cmd_24_5C" 19 "TemperatureRqstIndication_cmd_24C" 18 "TemperatureRqstIndication_cmd_23_5C" 17 "TemperatureRqstIndication_cmd_23C" 16 "TemperatureRqstIndication_cmd_22_5C" 15 "TemperatureRqstIndication_cmd_22C" 14 "TemperatureRqstIndication_cmd_21_5C" 13 "TemperatureRqstIndication_cmd_21C" 12 "TemperatureRqstIndication_cmd_20_5C" 11 "TemperatureRqstIndication_cmd_20C" 10 "TemperatureRqstIndication_cmd_19_5C" 9 "TemperatureRqstIndication_cmd_19C" 8 "TemperatureRqstIndication_cmd_18_5C" 7 "TemperatureRqstIndication_cmd_18C" 6 "TemperatureRqstIndication_cmd_17_5C" 5 "TemperatureRqstIndication_cmd_17C" 4 "TemperatureRqstIndication_cmd_16_5C" 3 "TemperatureRqstIndication_cmd_16C" 2 "TemperatureRqstIndication_cmd_15C" 1 "TemperatureRqstIndication_cmd_Min" 0 "TemperatureRqstIndication_cmd_NoTempDisplayed" ;
VAL_ 401 PHTimer1_stat_Status 3 "ParkHeaterTimer_Status_NotAvailable" 2 "ParkHeaterTimer_Status_TimerDeleted" 1 "ParkHeaterTimer_Status_TimerNotActivated" 0 "ParkHeaterTimer_Status_TimerActivated" ;
VAL_ 401 PHTimer_rqst_SetAlarmOper 7 "SetAlarmOperation_NotAvailable" 6 "SetAlarmOperation_Error" 5 "SetAlarmOperation_Spare_02" 4 "SetAlarmOperation_Spare_01" 3 "SetAlarmOperation_Reset" 2 "SetAlarmOperation_Continue" 1 "SetAlarmOperation_Stop" 0 "SetAlarmOperation_Start" ;
VAL_ 401 PHTimer_rqst_DayOfWeekRq 15 "DayOfWeekRq_NotAvailable" 14 "DayOfWeekRq_Error" 13 "DayOfWeekRq_Spare_7" 12 "DayOfWeekRq_Spare_6" 11 "DayOfWeekRq_Spare_5" 10 "DayOfWeekRq_Spare_4" 9 "DayOfWeekRq_Spare_3" 8 "DayOfWeekRq_Spare_2" 7 "DayOfWeekRq_NoDay" 6 "DayOfWeekRq_Sunday" 5 "DayOfWeekRq_Saturday" 4 "DayOfWeekRq_Friday" 3 "DayOfWeekRq_Thursday" 2 "DayOfWeekRq_Wednesday" 1 "DayOfWeekRq_Tuesday" 0 "DayOfWeekRq_Monday" ;
VAL_ 401 PHTimer1_stat_StartDay 15 "HeaterTimerStartDay_NotAvailable" 14 "HeaterTimerStartDay_Error" 13 "HeaterTimerStartDay_Spare_05" 12 "HeaterTimerStartDay_Spare_04" 11 "HeaterTimerStartDay_Spare_03" 10 "HeaterTimerStartDay_Spare_02" 9 "HeaterTimerStartDay_Spare_01" 8 "HeaterTimerStartDay_Spare" 7 "HeaterTimerStartDay_Sunday" 6 "HeaterTimerStartDay_Saturday" 5 "HeaterTimerStartDay_Friday" 4 "HeaterTimerStartDay_Thursday" 3 "HeaterTimerStartDay_Wednesday" 2 "HeaterTimerStartDay_Tuesday" 1 "HeaterTimerStartDay_Monday" 0 "HeaterTimerStartDay_NotUsed" ;
VAL_ 400 WindscreenDefrostInd_cmd 1 "IndicationCmd_ONLEDActivated" 0 "IndicationCmd_OFFLEDNotActivated" ;
VAL_ 400 ParkingHeater_IndicationCmd 1 "IndicationCmd_ONLEDActivated" 0 "IndicationCmd_OFFLEDNotActivated" ;
VAL_ 400 AutoBlowerLevelIndication_Cmd 7 "AutoBlowerLevel_NotAvailable" 6 "AutoBlowerLevel_Error" 5 "AutoBlowerLevel_Spare_02" 4 "AutoBlowerLevel_Spare_01" 3 "AutoBlowerLevel_Spare" 2 "AutoBlowerLevel_Low" 1 "AutoBlowerLevel_Normal" 0 "AutoBlowerLevel_High" ;
VAL_ 400 AC_CompressorClutchCmd 3 "DisengageEngage_NotAvailable" 2 "DisengageEngage_Error" 1 "DisengageEngage_Engage" 0 "DisengageEngage_Disengage" ;
VAL_ 400 ACdisplayIndication_Cmd 7 "ACMode_NotAvailable" 6 "ACMode_Error" 5 "ACMode_Spare_01" 4 "ACMode_Spare" 3 "ACMode_ExtraDryCabAir" 2 "ACMode_HumidCabAir" 1 "ACMode_Standard" 0 "ACMode_Economy" ;
VAL_ 400 ParkingHeaterCleaning_Rqst 3 "Request_NotAvailable" 2 "Request_Error" 1 "Request_RequestActive" 0 "Request_NotRequested" ;
VAL_ 400 TemperatureRqstIndication_cmd 31 "TemperatureRqstIndication_cmd_NotAvailable" 30 "TemperatureRqstIndication_cmd_Error" 29 "TemperatureRqstIndication_cmd_Spare_01" 28 "TemperatureRqstIndication_cmd_Spare" 27 "TemperatureRqstIndication_cmd_Max" 26 "TemperatureRqstIndication_cmd_29C" 25 "TemperatureRqstIndication_cmd_28C" 24 "TemperatureRqstIndication_cmd_27C" 23 "TemperatureRqstIndication_cmd_26C" 22 "TemperatureRqstIndication_cmd_25_5C" 21 "TemperatureRqstIndication_cmd_25C" 20 "TemperatureRqstIndication_cmd_24_5C" 19 "TemperatureRqstIndication_cmd_24C" 18 "TemperatureRqstIndication_cmd_23_5C" 17 "TemperatureRqstIndication_cmd_23C" 16 "TemperatureRqstIndication_cmd_22_5C" 15 "TemperatureRqstIndication_cmd_22C" 14 "TemperatureRqstIndication_cmd_21_5C" 13 "TemperatureRqstIndication_cmd_21C" 12 "TemperatureRqstIndication_cmd_20_5C" 11 "TemperatureRqstIndication_cmd_20C" 10 "TemperatureRqstIndication_cmd_19_5C" 9 "TemperatureRqstIndication_cmd_19C" 8 "TemperatureRqstIndication_cmd_18_5C" 7 "TemperatureRqstIndication_cmd_18C" 6 "TemperatureRqstIndication_cmd_17_5C" 5 "TemperatureRqstIndication_cmd_17C" 4 "TemperatureRqstIndication_cmd_16_5C" 3 "TemperatureRqstIndication_cmd_16C" 2 "TemperatureRqstIndication_cmd_15C" 1 "TemperatureRqstIndication_cmd_Min" 0 "TemperatureRqstIndication_cmd_NoTempDisplayed" ;
VAL_ 400 ParkingClimate_IndicationCmd 7 "ParkingClimate_IndicationCmd_NotAvailable" 6 "ParkingClimate_IndicationCmd_Error" 5 "ParkingClimate_IndicationCmd_Spare_01" 4 "ParkingClimate_IndicationCmd_ShortStopHeaterActivated" 3 "ParkingClimate_IndicationCmd_ParkCoolWithoutCompActivReducedMode" 2 "ParkingClimate_IndicationCmd_ParkCoolWithCompActivFullMode" 1 "ParkingClimate_IndicationCmd_ParkingHeaterActivated" 0 "ParkingClimate_IndicationCmd_NoSystemActivated" ;
VAL_ 400 ACmode_IndicationCmd 1 "IndicationCmd_ONLEDActivated" 0 "IndicationCmd_OFFLEDNotActivated" ;
VAL_ 400 AutoDefogIndication_Cmd 7 "AutoDefogmode_NotAvailable" 6 "AutoDefogmode_Error" 5 "AutoDefogmode_Spare_01" 4 "AutoDefogmode_Spare" 3 "AutoDefogmode_Moderate" 2 "AutoDefogmode_Normal" 1 "AutoDefogmode_Sensitive" 0 "AutoDefogmode_OFF" ;
VAL_ 400 TempRqst_cmd 31 "TempRqst_cmd_NotAvailable" 30 "TempRqst_cmd_Error" 29 "TempRqst_cmd_Spare_02" 28 "TempRqst_cmd_Spare_01" 27 "TempRqst_cmd_Spare" 26 "TempRqst_cmd_30C" 25 "TempRqst_cmd_29C" 24 "TempRqst_cmd_28C" 23 "TempRqst_cmd_27C" 22 "TempRqst_cmd_26C" 21 "TempRqst_cmd_25_5C" 20 "TempRqst_cmd_25C" 19 "TempRqst_cmd_24_5C" 18 "TempRqst_cmd_24C" 17 "TempRqst_cmd_23_5C" 16 "TempRqst_cmd_23C" 15 "TempRqst_cmd_22_5C" 14 "TempRqst_cmd_22C" 13 "TempRqst_cmd_21_5C" 12 "TempRqst_cmd_21C" 11 "TempRqst_cmd_20_5C" 10 "TempRqst_cmd_20C" 9 "TempRqst_cmd_19_5C" 8 "TempRqst_cmd_19C" 7 "TempRqst_cmd_18_5C" 6 "TempRqst_cmd_18C" 5 "TempRqst_cmd_17_5C" 4 "TempRqst_cmd_17C" 3 "TempRqst_cmd_16_5C" 2 "TempRqst_cmd_16C" 1 "TempRqst_cmd_15C" 0 "TempRqst_cmd_14C" ;
VAL_ 400 ExtraHeating_status 3 "OffAuto_NotAvailable" 2 "OffAuto_Error" 1 "OffAuto_AutoStart" 0 "OffAuto_Off" ;
VAL_ 400 AQSmodeIndication_Cmd 3 "AQSMode_NotAvailable" 2 "AQSMode_Error" 1 "AQSMode_Auto" 0 "AQSMode_OFF" ;
VAL_ 400 AutoMode_IndicationCmd 1 "IndicationCmd_ONLEDActivated" 0 "IndicationCmd_OFFLEDNotActivated" ;
VAL_ 400 ShortStopHeater_cmd 3 "Request_NotAvailable" 2 "Request_Error" 1 "Request_RequestActive" 0 "Request_NotRequested" ;
SIG_GROUP_ 895 WheelBasedVehicleSpd_sg 1 : WheelBasedVehicleSpd_Value WheelBasedVehicleSpd_CRC WheelBasedVehicleSpd_SqC;
SIG_GROUP_ 930 OBDRelDTC_IC_sg 1 : OBDRelDTC_IC_DrvngCycleB OBDRelDTC_IC_EvalResultA OBDRelDTC_IC_EvalResultB OBDRelDTC_IC_EvalStatA OBDRelDTC_IC_DtcIdB OBDRelDTC_IC_DrvngCycleA OBDRelDTC_IC_FailTB OBDRelDTC_IC_DtcIdA OBDRelDTC_IC_FailTA OBDRelDTC_IC_EvalStatB;
SIG_GROUP_ 784 SpeedAdaptEnableRqst_sg 1 : SpeedAdaptEnableRqst_SpeedLimit SpeedAdaptEnableRqst_SlowTraffic SpeedAdaptEnableRqst_Curve;
SIG_GROUP_ 416 SSReq_sg 1 : SSReq_Repetition SSReq_Balance SSReq_Time SSReq_Id SSReq_Mixed SSReq_State SSReq_Volume;
SIG_GROUP_ 1120 EngineTimer_stat_sg 1 : EngineTimer_stat_Timer2Minutes EngineTimer_stat_Timer1Recurr EngineTimer_stat_Timer3Minutes EngineTimer_stat_Timer2StartDay EngineTimer_stat_Timer3Recurr EngineTimer_stat_Timer1Hours EngineTimer_stat_Timer3_Status EngineTimer_stat_Timer1_Status EngineTimer_stat_Timer1Minutes EngineTimer_stat_Timer2Recurr EngineTimer_stat_Timer3Hours EngineTimer_stat_Timer2_Status EngineTimer_stat_Timer2Hours EngineTimer_stat_Timer1StartDay EngineTimer_stat_Timer3StartDay;
SIG_GROUP_ 1168 DiagFaultStat_CCM_sg 1 : DiagFaultStat_CCM_FailTA DiagFaultStat_CCM_FailTB DiagFaultStat_CCM_DtcIdA DiagFaultStat_CCM_DtcIdB DiagFaultStat_CCM_EcuAdr;
SIG_GROUP_ 402 PHTimer2_stat_sg 1 : PHTimer2_stat_StartDay PHTimer2_stat_Recurrence PHTimer2_stat_Temp PHTimer2_stat_Hours PHTimer2_stat_Minutes PHTimer2_stat_Status;
SIG_GROUP_ 402 PHTimer3_stat_sg 1 : PHTimer3_stat_Minutes PHTimer3_stat_Temp PHTimer3_stat_StartDay PHTimer3_stat_Recurrence PHTimer3_stat_Status PHTimer3_stat_Hours;
SIG_GROUP_ 401 PHTimer1_stat_sg 1 : PHTimer1_stat_Recurrence PHTimer1_stat_Temp PHTimer1_stat_Duration PHTimer1_stat_Status PHTimer1_stat_Hours PHTimer1_stat_Minutes PHTimer1_stat_StartDay;
SIG_GROUP_ 401 PHTimer_rqst_sg 1 : PHTimer_rqst_Hours PHTimer_rqst_SetAlarmOper PHTimer_rqst_Minutes PHTimer_rqst_DayOfWeekRq;
